VERSION "HNNBNNNYNNNNNNNNNNNNNNNNNNNNNNNNNNNNNNNNNN/4/%%%/4/'%**4NNN///"

NS_ :

BS_:

BU_: BAP_Tester BCM Gateway_Max TSGGen3_BFS TSGGen3_FS TSGGen3_HBFS TSGGen3_HFS WLC_01_CFD

BO_ 332 Motor_54: 32 Gateway_Max
 SG_ Motor_54_CRC : 0|8@1+ (1,0) [0|255] ""  BCM
 SG_ Motor_54_BZ : 8|4@1+ (1,0) [0|15] ""  BCM
 SG_ MO_Anforderung_HMS : 12|3@1+ (1.0,0.0) [0.0|7] ""  BCM
 SG_ FoD_DTC_TSK_GRA : 15|1@1+ (1.0,0.0) [0.0|1] ""  BCM
 SG_ TSK_vMax_aktuell : 16|8@1+ (1,0) [0|253] "Unit_KiloMeterPerHour"  BCM
 SG_ ISA_Status : 24|3@1+ (1.0,0.0) [0.0|7] ""  BCM
 SG_ ISA_Regelung_aktiv : 27|1@1+ (1.0,0.0) [0.0|1] ""  BCM
 SG_ ISA_Tempolimitwarnung : 28|1@1+ (1.0,0.0) [0.0|1] ""  BCM
 SG_ MO_Red_El_Fahrleistung : 29|3@1+ (1.0,0.0) [0.0|7] ""  BCM
 SG_ TSK_Status_EA : 32|3@1+ (1.0,0.0) [0.0|7] ""  BCM
 SG_ FoD_DTC_TSK_ACC : 35|1@1+ (1.0,0.0) [0.0|1] ""  BCM
 SG_ TSK_ACC_FoD_Status : 36|2@1+ (1.0,0.0) [0.0|3] ""  BCM
 SG_ TSK_GRA_FoD_Status : 38|2@1+ (1.0,0.0) [0.0|3] ""  BCM
 SG_ TSK_vMax_Fahrerassistenz : 40|9@1+ (1,0) [0|510] ""  BCM
 SG_ TSK_Einheit_vMax_Fahrerassistenz : 49|1@1+ (1.0,0.0) [0.0|1] ""  BCM
 SG_ TSK_Status_PLA : 50|3@1+ (1.0,0.0) [0.0|7] ""  BCM
 SG_ TSK_aktives_System : 53|3@1+ (1.0,0.0) [0.0|7] ""  BCM
 SG_ TSK_erhoehter_Fahrwiderstand : 56|1@1+ (1.0,0.0) [0.0|1] ""  BCM
 SG_ TSK_Anf_Antriebsmoment : 57|1@1+ (1.0,0.0) [0.0|1] ""  BCM
 SG_ TSK_Status_ARA : 58|3@1+ (1.0,0.0) [0.0|7] ""  BCM
 SG_ TSK_Status_IPA : 61|3@1+ (1.0,0.0) [0.0|7] ""  BCM
 SG_ TSK_aktives_System_02 : 64|4@1+ (1.0,0.0) [0.0|15] ""  BCM
 SG_ TSK_Status_RHP : 68|3@1+ (1.0,0.0) [0.0|7] ""  BCM
 SG_ MO_Kuppl_betaetigt : 72|1@1+ (1.0,0.0) [0.0|1] ""  BCM
 SG_ MO_QBit_Kuppl_betaetigt : 73|1@1+ (1.0,0.0) [0.0|1] ""  BCM
 SG_ MO_Klima_Regelmodus : 74|2@1+ (1.0,0.0) [0.0|3] ""  BCM
 SG_ MO_Fahrbereitschaft : 76|2@1+ (1.0,0.0) [0.0|3] ""  BCM
 SG_ MO_Freilauf_Info : 78|2@1+ (1.0,0.0) [0.0|3] ""  BCM
 SG_ CE_FlgLnchCtlPreCnd : 80|1@1+ (1.0,0.0) [0.0|1] ""  BCM
 SG_ MO_Krit_Heckobjekt : 81|3@1+ (1.0,0.0) [0.0|7] ""  BCM
 SG_ MO_NGS_Gangpos : 84|3@1+ (1.0,0.0) [0.0|7] ""  BCM
 SG_ MO_Freilauf_Status : 87|3@1+ (1.0,0.0) [0.0|7] ""  BCM
 SG_ MO_EBoost_verf_praed : 90|2@1+ (1.0,0.0) [0.0|3] ""  BCM
 SG_ MO_Heckspoiler_Anf : 92|1@1+ (1.0,0.0) [0.0|1] ""  BCM
 SG_ MO_eLaunch_verf : 93|2@1+ (1.0,0.0) [0.0|3] ""  BCM
 SG_ MO_Positionierung_aktiv : 95|1@1+ (1.0,0.0) [0.0|1] ""  BCM
 SG_ MO_Veto_Launchcontrol : 96|1@1+ (1.0,0.0) [0.0|1] ""  BCM
 SG_ MO_Startwunsch : 100|1@1+ (1.0,0.0) [0.0|1] ""  BCM
 SG_ MO_LaunchControl : 101|1@1+ (1.0,0.0) [0.0|1] ""  BCM
 SG_ MO_UBE_Hybrid_Reserve : 102|10@1+ (5,0) [0|5110] "Unit_WattHour"  BCM
 SG_ OBDProtocol_req : 112|8@1+ (1.0,0.0) [0.0|255] ""  BCM
 SG_ OBD_Calc_Load_Val : 128|8@1+ (0.39215686274509803,0) [0E-17|99.99999999999999765] "Unit_PerCent"  BCM
 SG_ OBD_Eng_Cool_Temp : 136|8@1+ (1,-40) [-40|215] "Unit_DegreCelsi"  BCM
 SG_ OBD_Abs_Throttle_Pos : 144|8@1+ (0.39215686274509803,0) [0E-17|99.99999999999999765] "Unit_PerCent"  BCM
 SG_ OBD_Abs_Load_Val : 152|16@1+ (0.39215686274509803,0) [0E-17|25699.99999999999939605] "Unit_PerCent"  BCM
 SG_ OBD_Abs_Pedal_Pos : 168|8@1+ (0.39215686274509803,0) [0E-17|99.99999999999999765] "Unit_PerCent"  BCM
 SG_ MO_Servicemodus : 176|4@1+ (1.0,0.0) [0.0|15] ""  BCM
 SG_ OBD_ClearMem_Inhibit : 183|1@1+ (1.0,0.0) [0.0|1] ""  BCM
 SG_ OBD_Sperrung_Kaltstart_Denom : 184|1@1+ (1.0,0.0) [0.0|1] ""  BCM
 SG_ MO_QBit_Aussen_Temp : 185|1@1+ (1.0,0.0) [0.0|1] ""  BCM
 SG_ OBD_Sperrung_IUMPR : 186|1@1+ (1.0,0.0) [0.0|1] ""  BCM
 SG_ OBD_Kaltstart_Denominator : 187|1@1+ (1.0,0.0) [0.0|1] ""  BCM
 SG_ OBD_Minimum_Trip : 188|1@1+ (1.0,0.0) [0.0|1] ""  BCM
 SG_ OBD_Driving_Cycle : 189|1@1+ (1.0,0.0) [0.0|1] ""  BCM,TSGGen3_BFS,TSGGen3_FS,TSGGen3_HBFS,TSGGen3_HFS,WLC_01_CFD
 SG_ OBD_Warm_Up_Cycle : 190|1@1+ (1.0,0.0) [0.0|1] ""  BCM,TSGGen3_BFS,TSGGen3_FS,TSGGen3_HBFS,TSGGen3_HFS,WLC_01_CFD
 SG_ OBD_Normed_Trip : 191|1@1+ (1.0,0.0) [0.0|1] ""  BCM
 SG_ MO_EMG_Min_Leistung : 192|11@1+ (100,-102200) [-102200|102300] "Unit_Watt"  BCM
 SG_ MO_EMG_Max_Leistung : 203|11@1+ (100,-102200) [-102200|102300] "Unit_Watt"  BCM
 SG_ MO_MVEM_MinLeistung_MVVerbrauch : 214|10@1+ (50,-10500) [-10500|40500] "Unit_Watt"  BCM
 SG_ MO_MVEM_MaxLeistung_MVVerbrauch : 224|10@1+ (50,-10500) [-10500|40500] "Unit_Watt"  BCM
 SG_ MO_UBE_Reserve : 238|10@1+ (5,0) [0|5110] "Unit_WattHour"  BCM
 SG_ OBD_Aussen_Temp_gef : 248|8@1+ (1,-40) [-40|213] "Unit_DegreCelsi"  BCM

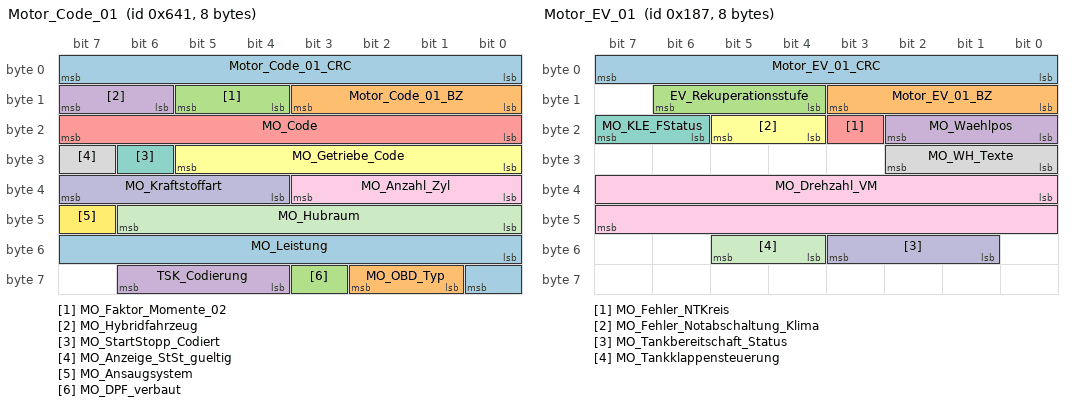
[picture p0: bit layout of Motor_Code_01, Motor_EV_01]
BO_ 1601 Motor_Code_01: 8 Gateway_Max
 SG_ Motor_Code_01_CRC : 0|8@1+ (1,0) [0|255] ""  Vector__XXX
 SG_ Motor_Code_01_BZ : 8|4@1+ (1,0) [0|15] ""  Vector__XXX
 SG_ MO_Faktor_Momente_02 : 12|2@1+ (1,0) [1|3] "Unit_NewtoMeter"  Vector__XXX
 SG_ MO_Hybridfahrzeug : 14|2@1+ (1.0,0.0) [0.0|3] ""  BCM,TSGGen3_BFS,TSGGen3_FS,TSGGen3_HBFS,TSGGen3_HFS
 SG_ MO_Code : 16|8@1+ (1,0) [0|255] ""  Vector__XXX
 SG_ MO_Getriebe_Code : 24|6@1+ (1.0,0.0) [0.0|63] ""  BCM
 SG_ MO_StartStopp_Codiert : 30|1@1+ (1.0,0.0) [0.0|1] ""  Vector__XXX
 SG_ MO_Anzeige_StSt_gueltig : 31|1@1+ (1.0,0.0) [0.0|1] ""  Vector__XXX
 SG_ MO_Anzahl_Zyl : 32|4@1+ (1.0,0.0) [0.0|15] ""  Vector__XXX
 SG_ MO_Kraftstoffart : 36|4@1+ (1.0,0.0) [0.0|15] ""  Vector__XXX
 SG_ MO_Hubraum : 40|7@1+ (0.1,0) [0.0|12.7] "Unit_Liter"  Vector__XXX
 SG_ MO_Ansaugsystem : 47|1@1+ (1.0,0.0) [0.0|1] ""  Vector__XXX
 SG_ MO_Leistung : 48|9@1+ (1,0) [0|511] "Unit_KiloWatt"  Vector__XXX
 SG_ MO_OBD_Typ : 57|2@1+ (1.0,0.0) [0.0|3] ""  Vector__XXX
 SG_ MO_DPF_verbaut : 59|1@1+ (1.0,0.0) [0.0|1] ""  Vector__XXX
 SG_ TSK_Codierung : 60|3@1+ (1.0,0.0) [0.0|7] ""  Vector__XXX

BO_ 391 Motor_EV_01: 8 Gateway_Max
 SG_ Motor_EV_01_CRC : 0|8@1+ (1,0) [0|255] ""  Vector__XXX
 SG_ Motor_EV_01_BZ : 8|4@1+ (1,0) [0|15] ""  Vector__XXX
 SG_ EV_Rekuperationsstufe : 12|3@1+ (1.0,0.0) [0.0|7] ""  Vector__XXX
 SG_ MO_Waehlpos : 16|3@1+ (1.0,0.0) [0.0|7] ""  BCM
 SG_ MO_Fehler_NTKreis : 19|1@1+ (1.0,0.0) [0.0|1] ""  Vector__XXX
 SG_ MO_Fehler_Notabschaltung_Klima : 20|2@1+ (1.0,0.0) [0.0|3] ""  Vector__XXX
 SG_ MO_KLE_FStatus : 22|2@1+ (1.0,0.0) [0.0|3] ""  Vector__XXX
 SG_ MO_WH_Texte : 24|3@1+ (1.0,0.0) [0.0|7] ""  Vector__XXX
 SG_ MO_Drehzahl_VM : 32|16@1+ (0.25,0) [0.00|16383.00] "Unit_MinutInver"  Vector__XXX
 SG_ MO_Tankbereitschaft_Status : 49|3@1+ (1.0,0.0) [0.0|7] ""  Vector__XXX
 SG_ MO_Tankklappensteuerung : 52|2@1+ (1.0,0.0) [0.0|3] ""  BCM

BO_ 16 MSG1_WFS_Anfrage: 8 Gateway_Max
 SG_ WFS_MSG1_RND : 0|32@1+ (1.0,0.0) [0.0|4294967295] ""  BCM
 SG_ WFS_MSG1_CRC : 32|32@1+ (1.0,0.0) [0.0|4294967295] ""  BCM

BO_ 22 MSG3_WFS_Anfrage: 8 Gateway_Max
 SG_ WFS_MSG3_RND : 0|32@1+ (1.0,0.0) [0.0|4294967295] ""  BCM
 SG_ WFS_MSG3_CRC : 32|32@1+ (1.0,0.0) [0.0|4294967295] ""  BCM

BO_ 24 MSG4_WFS_Anfrage: 8 Gateway_Max
 SG_ WFS_MSG4_RND : 0|32@1+ (1.0,0.0) [0.0|4294967295] ""  BCM
 SG_ WFS_MSG4_CRC : 32|32@1+ (1.0,0.0) [0.0|4294967295] ""  BCM

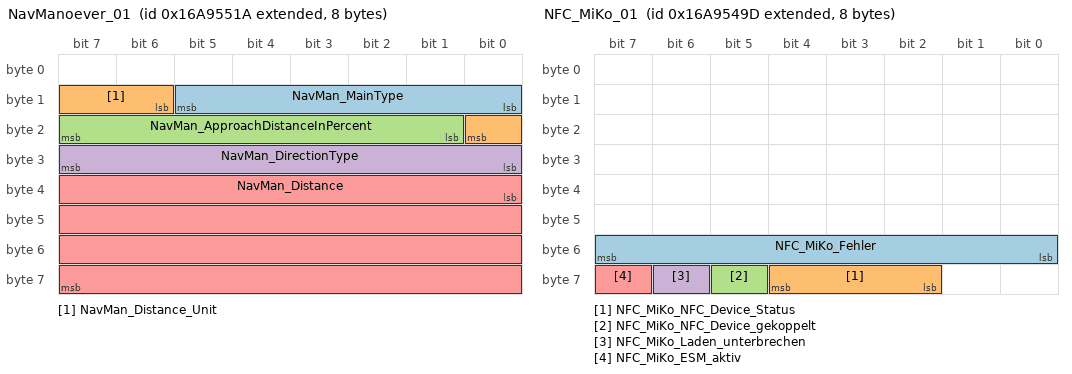
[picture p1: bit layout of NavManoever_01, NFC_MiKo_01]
BO_ 2527679770 NavManoever_01: 8 Gateway_Max
 SG_ NavMan_MainType : 8|6@1+ (1.0,0.0) [0.0|63] ""  BCM
 SG_ NavMan_Distance_Unit : 14|3@1+ (1.0,0.0) [0.0|7] ""  Vector__XXX
 SG_ NavMan_ApproachDistanceInPercent : 17|7@1+ (1,0) [0|100] "Unit_PerCent"  BCM
 SG_ NavMan_DirectionType : 24|8@1+ (1.411764705882353,0) [0E-15|360.000000000000015] "Unit_DegreOfArc"  BCM
 SG_ NavMan_Distance : 32|32@1+ (0.1,0) [0.0|429496729.5] "Unit_None"  Vector__XXX

BO_ 2527679645 NFC_MiKo_01: 8 WLC_01_CFD
 SG_ NFC_MiKo_Fehler : 48|8@1+ (1.0,0.0) [0.0|255] ""  Gateway_Max
 SG_ NFC_MiKo_NFC_Device_Status : 58|3@1+ (1.0,0.0) [0.0|7] ""  BCM,Gateway_Max
 SG_ NFC_MiKo_NFC_Device_gekoppelt : 61|1@1+ (1.0,0.0) [0.0|1] ""  BCM,Gateway_Max
 SG_ NFC_MiKo_Laden_unterbrechen : 62|1@1+ (1.0,0.0) [0.0|1] ""  Gateway_Max
 SG_ NFC_MiKo_ESM_aktiv : 63|1@1+ (1.0,0.0) [0.0|1] ""  Gateway_Max

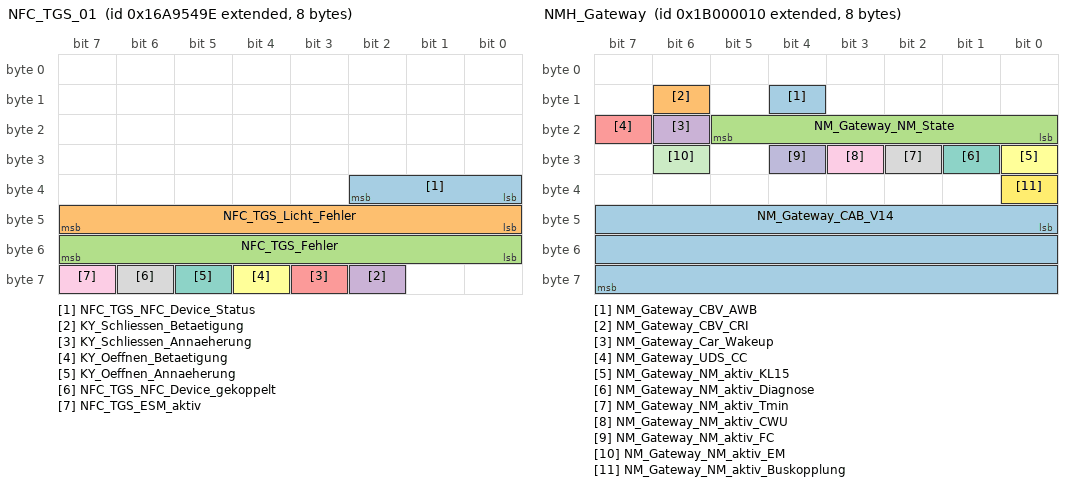
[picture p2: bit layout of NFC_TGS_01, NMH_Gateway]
BO_ 2527679646 NFC_TGS_01: 8 BCM
 SG_ NFC_TGS_NFC_Device_Status : 32|3@1+ (1.0,0.0) [0.0|7] ""  Vector__XXX
 SG_ NFC_TGS_Licht_Fehler : 40|8@1+ (1.0,0.0) [0.0|255] ""  Vector__XXX
 SG_ NFC_TGS_Fehler : 48|8@1+ (1.0,0.0) [0.0|255] ""  Vector__XXX
 SG_ KY_Schliessen_Betaetigung : 58|1@1+ (1.0,0.0) [0.0|1] ""  Vector__XXX
 SG_ KY_Schliessen_Annaeherung : 59|1@1+ (1.0,0.0) [0.0|1] ""  Vector__XXX
 SG_ KY_Oeffnen_Betaetigung : 60|1@1+ (1.0,0.0) [0.0|1] ""  TSGGen3_FS
 SG_ KY_Oeffnen_Annaeherung : 61|1@1+ (1.0,0.0) [0.0|1] ""  TSGGen3_FS
 SG_ NFC_TGS_NFC_Device_gekoppelt : 62|1@1+ (1.0,0.0) [0.0|1] ""  Vector__XXX
 SG_ NFC_TGS_ESM_aktiv : 63|1@1+ (1.0,0.0) [0.0|1] ""  Vector__XXX

BO_ 2600468494 NMH_BCM1: 8 BCM
 SG_ NM_BCM1_CBV_AWB : 12|1@1+ (1.0,0.0) [0.0|1] ""  Gateway_Max
 SG_ NM_BCM1_CBV_CRI : 14|1@1+ (1.0,0.0) [0.0|1] ""  Gateway_Max
 SG_ NM_BCM1_NM_State : 16|6@1+ (1.0,0.0) [0.0|63] ""  TSGGen3_BFS,TSGGen3_FS,TSGGen3_HBFS,TSGGen3_HFS,WLC_01_CFD
 SG_ NM_BCM1_Car_Wakeup : 22|1@1+ (1.0,0.0) [0.0|1] ""  Gateway_Max
 SG_ NM_BCM1_UDS_CC : 23|1@1+ (1.0,0.0) [0.0|1] ""  Vector__XXX
 SG_ NM_BCM1_NM_aktiv_KL15 : 24|1@1+ (1.0,0.0) [0.0|1] ""  Vector__XXX
 SG_ NM_BCM1_NM_aktiv_Diagnose : 25|1@1+ (1.0,0.0) [0.0|1] ""  Vector__XXX
 SG_ NM_BCM1_NM_aktiv_Tmin : 26|1@1+ (1.0,0.0) [0.0|1] ""  Vector__XXX
 SG_ NM_BCM1_NM_aktiv_Aussenlicht : 27|1@1+ (1.0,0.0) [0.0|1] ""  Vector__XXX
 SG_ NM_BCM1_NM_aktiv_ZV : 28|1@1+ (1.0,0.0) [0.0|1] ""  Vector__XXX
 SG_ NM_BCM1_NM_aktiv_Heizung : 29|1@1+ (1.0,0.0) [0.0|1] ""  Vector__XXX
 SG_ NM_BCM1_NM_aktiv_Innenlicht : 30|1@1+ (1.0,0.0) [0.0|1] ""  Vector__XXX
 SG_ NM_BCM1_NM_aktiv_DWA : 31|1@1+ (1.0,0.0) [0.0|1] ""  Vector__XXX
 SG_ NM_BCM1_NM_aktiv_Funk : 32|1@1+ (1.0,0.0) [0.0|1] ""  Vector__XXX
 SG_ NM_BCM1_NM_aktiv_Kessy : 33|1@1+ (1.0,0.0) [0.0|1] ""  Vector__XXX
 SG_ NM_BCM1_NM_aktiv_TK_geschlossen : 34|1@1+ (1.0,0.0) [0.0|1] ""  Vector__XXX
 SG_ NM_BCM1_NM_aktiv_Applikation : 35|1@1+ (1.0,0.0) [0.0|1] ""  Vector__XXX
 SG_ NM_BCM1_NM_aktiv_Remotestart : 36|1@1+ (1.0,0.0) [0.0|1] ""  Vector__XXX
 SG_ NM_BCM1_NM_aktiv_Remot_Door_L_Un : 37|1@1+ (1.0,0.0) [0.0|1] ""  Vector__XXX
 SG_ NM_BCM1_NM_aktiv_VLW : 38|1@1+ (1.0,0.0) [0.0|1] ""  Vector__XXX
 SG_ NM_BCM1_CAB_V14 : 40|24@1+ (1.0,0.0) [0.0|16777215] ""  Gateway_Max

BO_ 2600468496 NMH_Gateway: 8 Gateway_Max
 SG_ NM_Gateway_CBV_AWB : 12|1@1+ (1.0,0.0) [0.0|1] ""  Vector__XXX
 SG_ NM_Gateway_CBV_CRI : 14|1@1+ (1.0,0.0) [0.0|1] ""  Vector__XXX
 SG_ NM_Gateway_NM_State : 16|6@1+ (1.0,0.0) [0.0|63] ""  BCM,TSGGen3_BFS,TSGGen3_FS,TSGGen3_HBFS,TSGGen3_HFS,WLC_01_CFD
 SG_ NM_Gateway_Car_Wakeup : 22|1@1+ (1.0,0.0) [0.0|1] ""  Vector__XXX
 SG_ NM_Gateway_UDS_CC : 23|1@1+ (1.0,0.0) [0.0|1] ""  Vector__XXX
 SG_ NM_Gateway_NM_aktiv_KL15 : 24|1@1+ (1.0,0.0) [0.0|1] ""  Vector__XXX
 SG_ NM_Gateway_NM_aktiv_Diagnose : 25|1@1+ (1.0,0.0) [0.0|1] ""  Vector__XXX
 SG_ NM_Gateway_NM_aktiv_Tmin : 26|1@1+ (1.0,0.0) [0.0|1] ""  Vector__XXX
 SG_ NM_Gateway_NM_aktiv_CWU : 27|1@1+ (1.0,0.0) [0.0|1] ""  Vector__XXX
 SG_ NM_Gateway_NM_aktiv_FC : 28|1@1+ (1.0,0.0) [0.0|1] ""  Vector__XXX
 SG_ NM_Gateway_NM_aktiv_EM : 30|1@1+ (1.0,0.0) [0.0|1] ""  Vector__XXX
 SG_ NM_Gateway_NM_aktiv_Buskopplung : 32|1@1+ (1.0,0.0) [0.0|1] ""  Vector__XXX
 SG_ NM_Gateway_CAB_V14 : 40|24@1+ (1.0,0.0) [0.0|16777215] ""  Vector__XXX

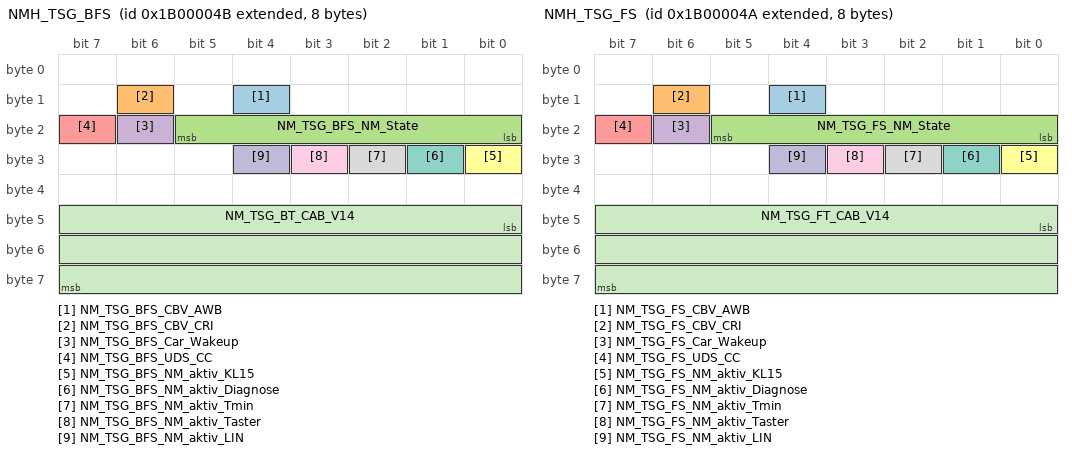
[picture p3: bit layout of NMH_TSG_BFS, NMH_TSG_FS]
BO_ 2600468555 NMH_TSG_BFS: 8 TSGGen3_BFS
 SG_ NM_TSG_BFS_CBV_AWB : 12|1@1+ (1.0,0.0) [0.0|1] ""  Gateway_Max
 SG_ NM_TSG_BFS_CBV_CRI : 14|1@1+ (1.0,0.0) [0.0|1] ""  Gateway_Max
 SG_ NM_TSG_BFS_NM_State : 16|6@1+ (1.0,0.0) [0.0|63] ""  BCM,TSGGen3_FS,TSGGen3_HBFS,TSGGen3_HFS,WLC_01_CFD
 SG_ NM_TSG_BFS_Car_Wakeup : 22|1@1+ (1.0,0.0) [0.0|1] ""  Gateway_Max
 SG_ NM_TSG_BFS_UDS_CC : 23|1@1+ (1.0,0.0) [0.0|1] ""  Vector__XXX
 SG_ NM_TSG_BFS_NM_aktiv_KL15 : 24|1@1+ (1.0,0.0) [0.0|1] ""  Vector__XXX
 SG_ NM_TSG_BFS_NM_aktiv_Diagnose : 25|1@1+ (1.0,0.0) [0.0|1] ""  Vector__XXX
 SG_ NM_TSG_BFS_NM_aktiv_Tmin : 26|1@1+ (1.0,0.0) [0.0|1] ""  Vector__XXX
 SG_ NM_TSG_BFS_NM_aktiv_Taster : 27|1@1+ (1.0,0.0) [0.0|1] ""  Vector__XXX
 SG_ NM_TSG_BFS_NM_aktiv_LIN : 28|1@1+ (1.0,0.0) [0.0|1] ""  Vector__XXX
 SG_ NM_TSG_BT_CAB_V14 : 40|24@1+ (1.0,0.0) [0.0|16777215] ""  Gateway_Max

BO_ 2600468554 NMH_TSG_FS: 8 TSGGen3_FS
 SG_ NM_TSG_FS_CBV_AWB : 12|1@1+ (1.0,0.0) [0.0|1] ""  Gateway_Max
 SG_ NM_TSG_FS_CBV_CRI : 14|1@1+ (1.0,0.0) [0.0|1] ""  Gateway_Max
 SG_ NM_TSG_FS_NM_State : 16|6@1+ (1.0,0.0) [0.0|63] ""  BCM,TSGGen3_BFS,TSGGen3_HBFS,TSGGen3_HFS,WLC_01_CFD
 SG_ NM_TSG_FS_Car_Wakeup : 22|1@1+ (1.0,0.0) [0.0|1] ""  Gateway_Max
 SG_ NM_TSG_FS_UDS_CC : 23|1@1+ (1.0,0.0) [0.0|1] ""  Vector__XXX
 SG_ NM_TSG_FS_NM_aktiv_KL15 : 24|1@1+ (1.0,0.0) [0.0|1] ""  Vector__XXX
 SG_ NM_TSG_FS_NM_aktiv_Diagnose : 25|1@1+ (1.0,0.0) [0.0|1] ""  Vector__XXX
 SG_ NM_TSG_FS_NM_aktiv_Tmin : 26|1@1+ (1.0,0.0) [0.0|1] ""  Vector__XXX
 SG_ NM_TSG_FS_NM_aktiv_Taster : 27|1@1+ (1.0,0.0) [0.0|1] ""  Vector__XXX
 SG_ NM_TSG_FS_NM_aktiv_LIN : 28|1@1+ (1.0,0.0) [0.0|1] ""  Vector__XXX
 SG_ NM_TSG_FT_CAB_V14 : 40|24@1+ (1.0,0.0) [0.0|16777215] ""  Gateway_Max

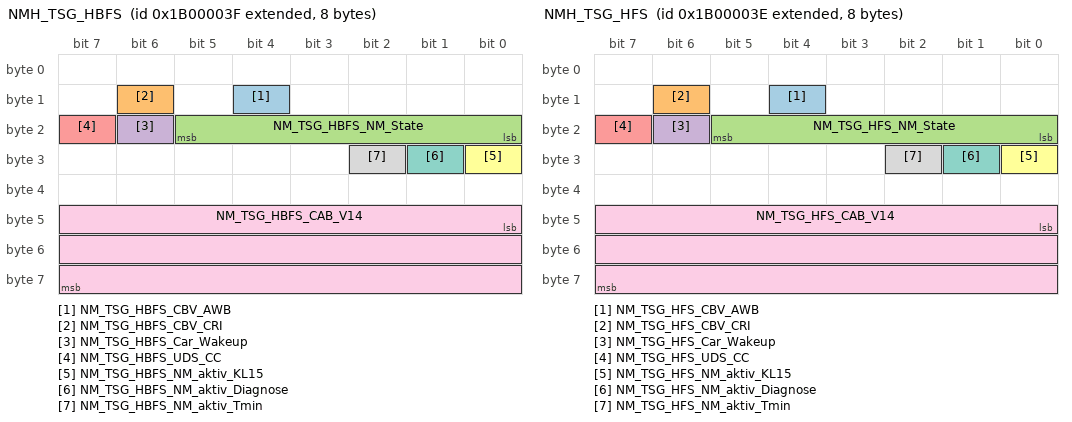
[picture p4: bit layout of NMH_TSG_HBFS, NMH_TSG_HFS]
BO_ 2600468543 NMH_TSG_HBFS: 8 TSGGen3_HBFS
 SG_ NM_TSG_HBFS_CBV_AWB : 12|1@1+ (1.0,0.0) [0.0|1] ""  Vector__XXX
 SG_ NM_TSG_HBFS_CBV_CRI : 14|1@1+ (1.0,0.0) [0.0|1] ""  Gateway_Max
 SG_ NM_TSG_HBFS_NM_State : 16|6@1+ (1.0,0.0) [0.0|63] ""  BCM,TSGGen3_BFS,TSGGen3_FS,TSGGen3_HFS,WLC_01_CFD
 SG_ NM_TSG_HBFS_Car_Wakeup : 22|1@1+ (1.0,0.0) [0.0|1] ""  Gateway_Max
 SG_ NM_TSG_HBFS_UDS_CC : 23|1@1+ (1.0,0.0) [0.0|1] ""  Vector__XXX
 SG_ NM_TSG_HBFS_NM_aktiv_KL15 : 24|1@1+ (1.0,0.0) [0.0|1] ""  Vector__XXX
 SG_ NM_TSG_HBFS_NM_aktiv_Diagnose : 25|1@1+ (1.0,0.0) [0.0|1] ""  Vector__XXX
 SG_ NM_TSG_HBFS_NM_aktiv_Tmin : 26|1@1+ (1.0,0.0) [0.0|1] ""  Vector__XXX
 SG_ NM_TSG_HBFS_CAB_V14 : 40|24@1+ (1.0,0.0) [0.0|16777215] ""  Gateway_Max

BO_ 2600468542 NMH_TSG_HFS: 8 TSGGen3_HFS
 SG_ NM_TSG_HFS_CBV_AWB : 12|1@1+ (1.0,0.0) [0.0|1] ""  Vector__XXX
 SG_ NM_TSG_HFS_CBV_CRI : 14|1@1+ (1.0,0.0) [0.0|1] ""  Vector__XXX
 SG_ NM_TSG_HFS_NM_State : 16|6@1+ (1.0,0.0) [0.0|63] ""  BCM,TSGGen3_BFS,TSGGen3_FS,TSGGen3_HBFS,WLC_01_CFD
 SG_ NM_TSG_HFS_Car_Wakeup : 22|1@1+ (1.0,0.0) [0.0|1] ""  Gateway_Max
 SG_ NM_TSG_HFS_UDS_CC : 23|1@1+ (1.0,0.0) [0.0|1] ""  Vector__XXX
 SG_ NM_TSG_HFS_NM_aktiv_KL15 : 24|1@1+ (1.0,0.0) [0.0|1] ""  Vector__XXX
 SG_ NM_TSG_HFS_NM_aktiv_Diagnose : 25|1@1+ (1.0,0.0) [0.0|1] ""  Vector__XXX
 SG_ NM_TSG_HFS_NM_aktiv_Tmin : 26|1@1+ (1.0,0.0) [0.0|1] ""  Vector__XXX
 SG_ NM_TSG_HFS_CAB_V14 : 40|24@1+ (1.0,0.0) [0.0|16777215] ""  Gateway_Max

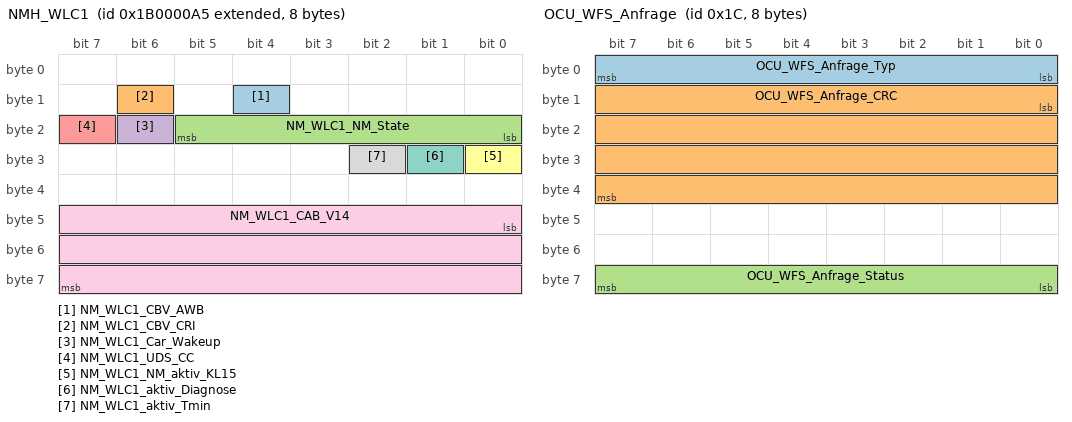
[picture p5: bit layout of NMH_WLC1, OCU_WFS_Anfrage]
BO_ 2600468645 NMH_WLC1: 8 WLC_01_CFD
 SG_ NM_WLC1_CBV_AWB : 12|1@1+ (1.0,0.0) [0.0|1] ""  Gateway_Max
 SG_ NM_WLC1_CBV_CRI : 14|1@1+ (1.0,0.0) [0.0|1] ""  Gateway_Max
 SG_ NM_WLC1_NM_State : 16|6@1+ (1.0,0.0) [0.0|63] ""  BCM,TSGGen3_BFS,TSGGen3_FS,TSGGen3_HBFS,TSGGen3_HFS
 SG_ NM_WLC1_Car_Wakeup : 22|1@1+ (1.0,0.0) [0.0|1] ""  Gateway_Max
 SG_ NM_WLC1_UDS_CC : 23|1@1+ (1.0,0.0) [0.0|1] ""  Vector__XXX
 SG_ NM_WLC1_NM_aktiv_KL15 : 24|1@1+ (1.0,0.0) [0.0|1] ""  Vector__XXX
 SG_ NM_WLC1_aktiv_Diagnose : 25|1@1+ (1.0,0.0) [0.0|1] ""  Vector__XXX
 SG_ NM_WLC1_aktiv_Tmin : 26|1@1+ (1.0,0.0) [0.0|1] ""  Vector__XXX
 SG_ NM_WLC1_CAB_V14 : 40|24@1+ (1.0,0.0) [0.0|16777215] ""  Gateway_Max

BO_ 2621440526 OBDC_BCM1_Req_FD: 64 Gateway_Max
 SG_ OBDC_BCM1_Req_FD_Data : 0|512@1+ (1.0,0.0) [0.0|13407807929942597099574024998205846127479365820592393377723561443721764030073546976801874298166903427690031858186486050853753882811946569946433649006084095] ""  BCM

BO_ 2621571598 OBDC_BCM1_Resp_FD: 64 BCM
 SG_ OBDC_BCM1_Resp_FD_Data : 0|512@1+ (1.0,0.0) [0.0|13407807929942597099574024998205846127479365820592393377723561443721764030073546976801874298166903427690031858186486050853753882811946569946433649006084095] ""  Gateway_Max

BO_ 2549875386 OBDC_DDA_Req: 8 Gateway_Max
 SG_ OBDC_DDA_Req_Data : 0|64@1+ (1.0,0.0) [0.0|18446744073709551615] ""  BCM

BO_ 2550006458 OBDC_DDA_Resp: 8 BCM
 SG_ OBDC_DDA_Resp_Data : 0|64@1+ (1.0,0.0) [0.0|18446744073709551615] ""  Gateway_Max

BO_ 2549940736 OBDC_Funktionaler_Req_All: 8 Gateway_Max
 SG_ OBDC_Funktionaler_Req_All_Data : 0|64@1+ (1.0,0.0) [0.0|18446744073709551615] ""  BCM

BO_ 2621506048 OBDC_Funktionaler_Req_All_FD: 64 Gateway_Max
 SG_ OBDC_Funktion_Req_All_FD_Data : 0|512@1+ (1.0,0.0) [0.0|13407807929942597099574024998205846127479365820592393377723561443721764030073546976801874298166903427690031858186486050853753882811946569946433649006084095] ""  BCM,TSGGen3_BFS,TSGGen3_FS,TSGGen3_HBFS,TSGGen3_HFS,WLC_01_CFD

BO_ 2549875250 OBDC_Kessy_Req: 8 Gateway_Max
 SG_ OBDC_Kessy_Req_Data : 0|64@1+ (1.0,0.0) [0.0|18446744073709551615] ""  BCM

BO_ 2550006322 OBDC_Kessy_Resp: 8 BCM
 SG_ OBDC_Kessy_Resp_Data : 0|64@1+ (1.0,0.0) [0.0|18446744073709551615] ""  Gateway_Max

BO_ 2549875350 OBDC_LED_LM_L_Req: 8 Gateway_Max
 SG_ OBDC_LED_LM_L_Req_Data : 0|64@1+ (1.0,0.0) [0.0|18446744073709551615] ""  BCM

BO_ 2550006422 OBDC_LED_LM_L_Resp: 8 BCM
 SG_ OBDC_LED_LM_L_Resp_Data : 0|64@1+ (1.0,0.0) [0.0|18446744073709551615] ""  Gateway_Max

BO_ 2549875351 OBDC_LED_LM_R_Req: 8 Gateway_Max
 SG_ OBDC_LED_LM_R_Req_Data : 0|64@1+ (1.0,0.0) [0.0|18446744073709551615] ""  BCM

BO_ 2550006423 OBDC_LED_LM_R_Resp: 8 BCM
 SG_ OBDC_LED_LM_R_Resp_Data : 0|64@1+ (1.0,0.0) [0.0|18446744073709551615] ""  Gateway_Max

BO_ 2550399491 OBDC_RSAD_HL_Req: 8 Gateway_Max
 SG_ OBDC_RSAD_HL_Req_Data : 0|64@1+ (1,0) [0|18446744073709551615] "Unit_None"  BCM

BO_ 2621702659 OBDC_RSAD_HL_Req_FD: 64 Gateway_Max
 SG_ OBDC_RSAD_HL_Req_FD_Data : 0|512@1+ (1.0,0.0) [0.0|13407807929942597099574024998205846127479365820592393377723561443721764030073546976801874298166903427690031858186486050853753882811946569946433649006084095] ""  BCM

BO_ 2550530563 OBDC_RSAD_HL_Resp: 8 BCM
 SG_ OBDC_RSAD_HL_Resp_Data : 0|64@1+ (1,0) [0|18446744073709551615] "Unit_None"  Gateway_Max

BO_ 2621833731 OBDC_RSAD_HL_Resp_FD: 64 BCM
 SG_ OBDC_RSAD_HL_Resp_FD_Data : 0|512@1+ (1.0,0.0) [0.0|13407807929942597099574024998205846127479365820592393377723561443721764030073546976801874298166903427690031858186486050853753882811946569946433649006084095] ""  Gateway_Max

BO_ 2550399492 OBDC_RSAD_HR_Req: 8 Gateway_Max
 SG_ OBDC_RSAD_HR_Req_Data : 0|64@1+ (1,0) [0|18446744073709551615] "Unit_None"  BCM

BO_ 2621702660 OBDC_RSAD_HR_Req_FD: 64 Gateway_Max
 SG_ OBDC_RSAD_HR_Req_FD_Data : 0|512@1+ (1.0,0.0) [0.0|13407807929942597099574024998205846127479365820592393377723561443721764030073546976801874298166903427690031858186486050853753882811946569946433649006084095] ""  BCM

BO_ 2550530564 OBDC_RSAD_HR_Resp: 8 BCM
 SG_ OBDC_RSAD_HR_Resp_Data : 0|64@1+ (1,0) [0|18446744073709551615] "Unit_None"  Gateway_Max

BO_ 2621833732 OBDC_RSAD_HR_Resp_FD: 64 BCM
 SG_ OBDC_RSAD_HR_Resp_FD_Data : 0|512@1+ (1.0,0.0) [0.0|13407807929942597099574024998205846127479365820592393377723561443721764030073546976801874298166903427690031858186486050853753882811946569946433649006084095] ""  Gateway_Max

BO_ 2621702709 OBDC_RSAD_IN2_Req_FD: 64 Gateway_Max
 SG_ OBDC_RSAD_IN2_Req_FD_Data : 0|512@1+ (1.0,0.0) [0.0|13407807929942597099574024998205846127479365820592393377723561443721764030073546976801874298166903427690031858186486050853753882811946569946433649006084095] ""  BCM

BO_ 2621833781 OBDC_RSAD_IN2_Resp_FD: 64 BCM
 SG_ OBDC_RSAD_IN2_Resp_FD_Data : 0|512@1+ (1.0,0.0) [0.0|13407807929942597099574024998205846127479365820592393377723561443721764030073546976801874298166903427690031858186486050853753882811946569946433649006084095] ""  Gateway_Max

BO_ 2621702710 OBDC_RSAD_IN3_Req_FD: 64 Gateway_Max
 SG_ OBDC_RSAD_IN3_Req_FD_Data : 0|512@1+ (1.0,0.0) [0.0|13407807929942597099574024998205846127479365820592393377723561443721764030073546976801874298166903427690031858186486050853753882811946569946433649006084095] ""  BCM

BO_ 2621833782 OBDC_RSAD_IN3_Resp_FD: 64 BCM
 SG_ OBDC_RSAD_IN3_Resp_FD_Data : 0|512@1+ (1.0,0.0) [0.0|13407807929942597099574024998205846127479365820592393377723561443721764030073546976801874298166903427690031858186486050853753882811946569946433649006084095] ""  Gateway_Max

BO_ 2621702711 OBDC_RSAD_IN4_Req_FD: 64 Gateway_Max
 SG_ OBDC_RSAD_IN4_Req_FD_Data : 0|512@1+ (1.0,0.0) [0.0|13407807929942597099574024998205846127479365820592393377723561443721764030073546976801874298166903427690031858186486050853753882811946569946433649006084095] ""  BCM

BO_ 2621833783 OBDC_RSAD_IN4_Resp_FD: 64 BCM
 SG_ OBDC_RSAD_IN4_Resp_FD_Data : 0|512@1+ (1.0,0.0) [0.0|13407807929942597099574024998205846127479365820592393377723561443721764030073546976801874298166903427690031858186486050853753882811946569946433649006084095] ""  Gateway_Max

BO_ 2550399493 OBDC_RSAD_IN_Req: 8 Gateway_Max
 SG_ OBDC_RSAD_IN_Req_Data : 0|64@1+ (1,0) [0|18446744073709551615] "Unit_None"  BCM

BO_ 2621702661 OBDC_RSAD_IN_Req_FD: 64 Gateway_Max
 SG_ OBDC_RSAD_IN_Req_FD_Data : 0|512@1+ (1.0,0.0) [0.0|13407807929942597099574024998205846127479365820592393377723561443721764030073546976801874298166903427690031858186486050853753882811946569946433649006084095] ""  BCM

BO_ 2550530565 OBDC_RSAD_IN_Resp: 8 BCM
 SG_ OBDC_RSAD_IN_Resp_Data : 0|64@1+ (1,0) [0|18446744073709551615] "Unit_None"  Gateway_Max

BO_ 2621833733 OBDC_RSAD_IN_Resp_FD: 64 BCM
 SG_ OBDC_RSAD_IN_Resp_FD_Data : 0|512@1+ (1.0,0.0) [0.0|13407807929942597099574024998205846127479365820592393377723561443721764030073546976801874298166903427690031858186486050853753882811946569946433649006084095] ""  Gateway_Max

BO_ 2550399489 OBDC_RSAD_VL_Req: 8 Gateway_Max
 SG_ OBDC_RSAD_VL_Req_Data : 0|64@1+ (1,0) [0|18446744073709551615] "Unit_None"  BCM

BO_ 2621702657 OBDC_RSAD_VL_Req_FD: 64 Gateway_Max
 SG_ OBDC_RSAD_VL_Req_FD_Data : 0|512@1+ (1.0,0.0) [0.0|13407807929942597099574024998205846127479365820592393377723561443721764030073546976801874298166903427690031858186486050853753882811946569946433649006084095] ""  BCM

BO_ 2550530561 OBDC_RSAD_VL_Resp: 8 BCM
 SG_ OBDC_RSAD_VL_Resp_Data : 0|64@1+ (1,0) [0|18446744073709551615] "Unit_None"  Gateway_Max

BO_ 2621833729 OBDC_RSAD_VL_Resp_FD: 64 BCM
 SG_ OBDC_RSAD_VL_Resp_FD_Data : 0|512@1+ (1.0,0.0) [0.0|13407807929942597099574024998205846127479365820592393377723561443721764030073546976801874298166903427690031858186486050853753882811946569946433649006084095] ""  Gateway_Max

BO_ 2550399490 OBDC_RSAD_VR_Req: 8 Gateway_Max
 SG_ OBDC_RSAD_VR_Req_Data : 0|64@1+ (1,0) [0|18446744073709551615] "Unit_None"  BCM

BO_ 2621702658 OBDC_RSAD_VR_Req_FD: 64 Gateway_Max
 SG_ OBDC_RSAD_VR_Req_FD_Data : 0|512@1+ (1.0,0.0) [0.0|13407807929942597099574024998205846127479365820592393377723561443721764030073546976801874298166903427690031858186486050853753882811946569946433649006084095] ""  BCM

BO_ 2550530562 OBDC_RSAD_VR_Resp: 8 BCM
 SG_ OBDC_RSAD_VR_Resp_Data : 0|64@1+ (1,0) [0|18446744073709551615] "Unit_None"  Gateway_Max

BO_ 2621833730 OBDC_RSAD_VR_Resp_FD: 64 BCM
 SG_ OBDC_RSAD_VR_Resp_FD_Data : 0|512@1+ (1.0,0.0) [0.0|13407807929942597099574024998205846127479365820592393377723561443721764030073546976801874298166903427690031858186486050853753882811946569946433649006084095] ""  Gateway_Max

BO_ 2549903595 OBDC_SSN_NFC_TGS_Req: 8 Gateway_Max
 SG_ OBDC_SSN_NFC_TGS_Req_Data : 0|64@1+ (1.0,0.0) [0.0|18446744073709551615] ""  BCM

BO_ 2550034667 OBDC_SSN_NFC_TGS_Resp: 8 BCM
 SG_ OBDC_SSN_NFC_TGS_Resp_Data : 0|64@1+ (1.0,0.0) [0.0|18446744073709551615] ""  Gateway_Max

BO_ 2621440587 OBDC_TSG_BT_Req_FD: 64 Gateway_Max
 SG_ OBDC_TSG_BT_Req_FD_Data : 0|512@1+ (1.0,0.0) [0.0|13407807929942597099574024998205846127479365820592393377723561443721764030073546976801874298166903427690031858186486050853753882811946569946433649006084095] ""  TSGGen3_BFS

BO_ 2621571659 OBDC_TSG_BT_Resp_FD: 64 TSGGen3_BFS
 SG_ OBDC_TSG_BT_Resp_FD_Data : 0|512@1+ (1.0,0.0) [0.0|13407807929942597099574024998205846127479365820592393377723561443721764030073546976801874298166903427690031858186486050853753882811946569946433649006084095] ""  Gateway_Max

BO_ 2621440586 OBDC_TSG_FT_Req_FD: 64 Gateway_Max
 SG_ OBDC_TSG_FT_Req_FD_Data : 0|512@1+ (1.0,0.0) [0.0|13407807929942597099574024998205846127479365820592393377723561443721764030073546976801874298166903427690031858186486050853753882811946569946433649006084095] ""  TSGGen3_FS

BO_ 2621571658 OBDC_TSG_FT_Resp_FD: 64 TSGGen3_FS
 SG_ OBDC_TSG_FT_Resp_FD_Data : 0|512@1+ (1.0,0.0) [0.0|13407807929942597099574024998205846127479365820592393377723561443721764030073546976801874298166903427690031858186486050853753882811946569946433649006084095] ""  Gateway_Max

BO_ 2621440575 OBDC_TSG_HBFS_Req_FD: 64 Gateway_Max
 SG_ OBDC_TSG_HBFS_Req_FD_Data : 0|512@1+ (1.0,0.0) [0.0|13407807929942597099574024998205846127479365820592393377723561443721764030073546976801874298166903427690031858186486050853753882811946569946433649006084095] ""  TSGGen3_HBFS

BO_ 2621571647 OBDC_TSG_HBFS_Resp_FD: 64 TSGGen3_HBFS
 SG_ OBDC_TSG_HBFS_Resp_FD_Data : 0|512@1+ (1.0,0.0) [0.0|13407807929942597099574024998205846127479365820592393377723561443721764030073546976801874298166903427690031858186486050853753882811946569946433649006084095] ""  Gateway_Max

BO_ 2621440574 OBDC_TSG_HFS_Req_FD: 64 Gateway_Max
 SG_ OBDC_TSG_HFS_Req_FD_Data : 0|512@1+ (1.0,0.0) [0.0|13407807929942597099574024998205846127479365820592393377723561443721764030073546976801874298166903427690031858186486050853753882811946569946433649006084095] ""  TSGGen3_HFS

BO_ 2621571646 OBDC_TSG_HFS_Resp_FD: 64 TSGGen3_HFS
 SG_ OBDC_TSG_HFS_Resp_FD_Data : 0|512@1+ (1.0,0.0) [0.0|13407807929942597099574024998205846127479365820592393377723561443721764030073546976801874298166903427690031858186486050853753882811946569946433649006084095] ""  Gateway_Max

BO_ 2621440677 OBDC_WLC1_Req_FD: 64 Gateway_Max
 SG_ OBDC_WLC1_Req_FD_Data : 0|512@1+ (1.0,0.0) [0.0|13407807929942597099574024998205846127479365820592393377723561443721764030073546976801874298166903427690031858186486050853753882811946569946433649006084095] ""  WLC_01_CFD

BO_ 2621571749 OBDC_WLC1_Resp_FD: 64 WLC_01_CFD
 SG_ OBDC_WLC1_Resp_FD_Data : 0|512@1+ (1.0,0.0) [0.0|13407807929942597099574024998205846127479365820592393377723561443721764030073546976801874298166903427690031858186486050853753882811946569946433649006084095] ""  Gateway_Max

BO_ 2564502513 OBDx_allOBD_Req: 8 Gateway_Max
 SG_ OBDx_allOBD_Req_Data : 0|64@1+ (1.0,0.0) [0.0|18446744073709551615] ""  Vector__XXX

BO_ 28 OCU_WFS_Anfrage: 8 Gateway_Max
 SG_ OCU_WFS_Anfrage_Typ : 0|8@1+ (1.0,0.0) [0.0|255] ""  BCM
 SG_ OCU_WFS_Anfrage_CRC : 8|32@1+ (1.0,0.0) [0.0|4294967295] ""  BCM
 SG_ OCU_WFS_Anfrage_Status : 56|8@1+ (1.0,0.0) [0.0|255] ""  BCM

BO_ 2589283656 ORU_01: 8 Gateway_Max
 SG_ ORU_Warnung : 58|2@1+ (1.0,0.0) [0.0|3] ""  BCM
 SG_ ORU_Status : 61|3@1+ (1.0,0.0) [0.0|7] ""  BCM,TSGGen3_BFS,TSGGen3_FS,TSGGen3_HBFS,TSGGen3_HFS

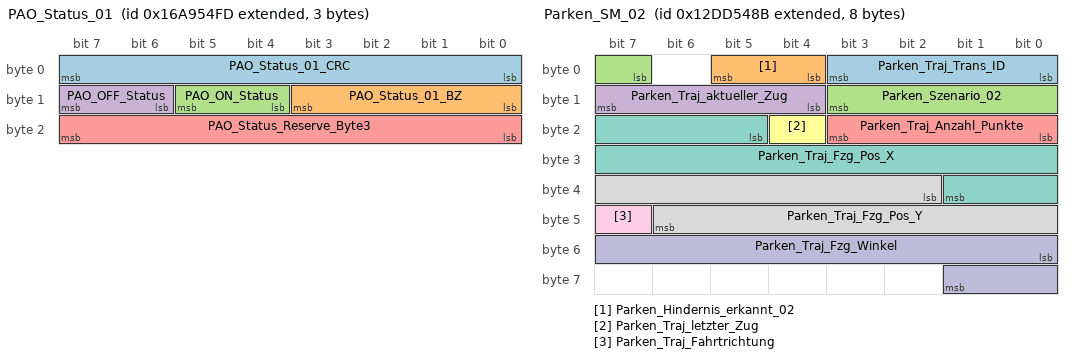
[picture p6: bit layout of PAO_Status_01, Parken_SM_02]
BO_ 2527679741 PAO_Status_01: 3 BCM
 SG_ PAO_Status_01_CRC : 0|8@1+ (1,0) [0|255] ""  Gateway_Max
 SG_ PAO_Status_01_BZ : 8|4@1+ (1,0) [0|15] ""  Gateway_Max
 SG_ PAO_ON_Status : 12|2@1+ (1.0,0.0) [0.0|3] ""  Gateway_Max
 SG_ PAO_OFF_Status : 14|2@1+ (1.0,0.0) [0.0|3] ""  Gateway_Max
 SG_ PAO_Status_Reserve_Byte3 : 16|8@1+ (1.0,0.0) [0.0|255] ""  Gateway_Max

BO_ 233 Parken_SM_01: 8 Gateway_Max
 SG_ Parken_Hindernis_Bereich : 0|4@1+ (1.0,0.0) [0.0|15] ""  BCM
 SG_ Parken_SM_Sensor : 5|1@1+ (1.0,0.0) [0.0|1] ""  BCM
 SG_ Parken_SM_Stillstand : 6|1@1+ (1.0,0.0) [0.0|1] ""  BCM
 SG_ Parken_SM_Schluessel : 7|1@1+ (1.0,0.0) [0.0|1] ""  BCM
 SG_ Parken_SM_Tueren : 8|1@1+ (1.0,0.0) [0.0|1] ""  BCM
 SG_ Parken_SM_Anhaenger : 9|1@1+ (1.0,0.0) [0.0|1] ""  BCM
 SG_ Parken_SM_Fahrbereitschaft : 10|1@1+ (1.0,0.0) [0.0|1] ""  BCM
 SG_ Parken_SM_Fahrstufe : 11|1@1+ (1.0,0.0) [0.0|1] ""  BCM
 SG_ Parken_Anhaltegrund_ext : 12|6@1+ (1.0,0.0) [0.0|63] ""  BCM
 SG_ Parken_Touchdiagnose_Anf : 18|1@1+ (1.0,0.0) [0.0|1] ""  BCM
 SG_ Parken_BT_Wunsch : 19|1@1+ (1.0,0.0) [0.0|1] ""  BCM
 SG_ Parken_Hindernis_erkannt : 20|1@1+ (1.0,0.0) [0.0|1] ""  BCM
 SG_ Parken_Fortschrittszaehler : 21|7@1+ (1,0) [0|100] "Unit_PerCent"  BCM
 SG_ Parken_SM_AktivesRemoteSystem : 28|2@1+ (1.0,0.0) [0.0|3] ""  BCM
 SG_ Parken_Fahrtaster_Empfehlung : 32|2@1+ (1.0,0.0) [0.0|3] ""  BCM
 SG_ Parken_Aktives_Bedienelement : 34|2@1+ (1.0,0.0) [0.0|3] ""  BCM
 SG_ Parken_FFB_Status : 36|3@1+ (1.0,0.0) [0.0|7] ""  BCM
 SG_ Parken_Reversieren_moeglich : 39|1@1+ (1.0,0.0) [0.0|1] ""  BCM
 SG_ Parken_Seite : 40|3@1+ (1.0,0.0) [0.0|7] ""  BCM
 SG_ Parken_Seite_Aktiv : 43|2@1+ (1.0,0.0) [0.0|3] ""  BCM
 SG_ Parken_Szenario_Aktiv : 45|3@1+ (1.0,0.0) [0.0|7] ""  BCM
 SG_ Parken_Manoever_Aktiv : 48|2@1+ (1.0,0.0) [0.0|3] ""  BCM
 SG_ Parken_Manoever : 50|2@1+ (1.0,0.0) [0.0|3] ""  BCM
 SG_ Parken_Szenario : 52|4@1+ (1.0,0.0) [0.0|15] ""  BCM
 SG_ Parken_Funktionsstatus : 56|4@1+ (1.0,0.0) [0.0|15] ""  BCM
 SG_ Parken_Richtung : 60|2@1+ (1.0,0.0) [0.0|3] ""  BCM
 SG_ Parken_Richtung_Aktiv : 62|2@1+ (1.0,0.0) [0.0|3] ""  BCM

BO_ 2463978635 Parken_SM_02: 8 Gateway_Max
 SG_ Parken_Traj_Trans_ID : 0|4@1+ (1.0,0.0) [0.0|15] ""  BCM
 SG_ Parken_Hindernis_erkannt_02 : 4|2@1+ (1.0,0.0) [0.0|3] ""  BCM
 SG_ Parken_Szenario_02 : 7|5@1+ (1.0,0.0) [0.0|31] ""  BCM
 SG_ Parken_Traj_aktueller_Zug : 12|4@1+ (1.0,0.0) [0.0|15] ""  BCM
 SG_ Parken_Traj_Anzahl_Punkte : 16|4@1+ (1.0,0.0) [0.0|15] ""  BCM
 SG_ Parken_Traj_letzter_Zug : 20|1@1+ (1.0,0.0) [0.0|1] ""  BCM
 SG_ Parken_Traj_Fzg_Pos_X : 21|13@1+ (0.5,-2047.5) [-2047.5|2048.0] "Unit_Centimeter"  BCM
 SG_ Parken_Traj_Fzg_Pos_Y : 34|13@1+ (0.5,-2047.5) [-2047.5|2048.0] "Unit_Centimeter"  BCM
 SG_ Parken_Traj_Fahrtrichtung : 47|1@1+ (1.0,0.0) [0.0|1] ""  BCM
 SG_ Parken_Traj_Fzg_Winkel : 48|10@1+ (0.3515625,0) [0E-7|359.6484375] "Unit_DegreOfArc"  BCM

BO_ 850 Parken_SM_03: 8 Gateway_Max
 SG_ Parken_SM_03_MUX M  : 0|3@1+ (1.0,0.0) [0.0|7] ""  BCM
 SG_ Parken_SM_03_Traj_Trans_ID_00 m0  : 3|4@1+ (1.0,0.0) [0.0|15] ""  BCM
 SG_ Parken_SM_03_Traj_Trans_ID_01 m1  : 3|4@1+ (1.0,0.0) [0.0|15] ""  BCM
 SG_ Parken_SM_03_Traj_Trans_ID_02 m2  : 3|4@1+ (1.0,0.0) [0.0|15] ""  BCM
 SG_ Parken_SM_03_Traj_Trans_ID_03 m3  : 3|4@1+ (1.0,0.0) [0.0|15] ""  BCM
 SG_ Parken_SM_03_Traj_Trans_ID_04 m4  : 3|4@1+ (1.0,0.0) [0.0|15] ""  BCM
 SG_ Parken_SM_03_Traj_Trans_ID_05 m5  : 3|4@1+ (1.0,0.0) [0.0|15] ""  BCM
 SG_ Parken_SM_03_Traj_Trans_ID_06 m6  : 3|4@1+ (1.0,0.0) [0.0|15] ""  BCM
 SG_ Parken_Traj_P1_Pos_X m0  : 7|13@1+ (0.5,-2047.5) [-2047.5|2048.0] "Unit_Centimeter"  BCM
 SG_ Parken_Traj_P2_Pos_Y m1  : 7|13@1+ (0.5,-2047.5) [-2047.5|2048.0] "Unit_Centimeter"  BCM
 SG_ Parken_Traj_P3_Tangent m2  : 7|10@1+ (0.3515625,0) [0E-7|359.6484375] "Unit_DegreOfArc"  BCM
 SG_ Parken_Traj_P5_Pos_X m3  : 7|13@1+ (0.5,-2047.5) [-2047.5|2048.0] "Unit_Centimeter"  BCM
 SG_ Parken_Traj_P6_Pos_Y m4  : 7|13@1+ (0.5,-2047.5) [-2047.5|2048.0] "Unit_Centimeter"  BCM
 SG_ Parken_Traj_P7_Tangent m5  : 7|10@1+ (0.3515625,0) [0E-7|359.6484375] "Unit_DegreOfArc"  BCM
 SG_ Parken_Traj_P9_Pos_X m6  : 7|13@1+ (0.5,-2047.5) [-2047.5|2048.0] "Unit_Centimeter"  BCM
 SG_ Parken_Traj_P4_Pos_X m2  : 17|13@1+ (0.5,-2047.5) [-2047.5|2048.0] "Unit_Centimeter"  BCM
 SG_ Parken_Traj_P8_Pos_X m5  : 17|13@1+ (0.5,-2047.5) [-2047.5|2048.0] "Unit_Centimeter"  BCM
 SG_ Parken_Traj_P1_Pos_Y m0  : 20|13@1+ (0.5,-2047.5) [-2047.5|2048.0] "Unit_Centimeter"  BCM
 SG_ Parken_Traj_P2_Tangent m1  : 20|10@1+ (0.3515625,0) [0E-7|359.6484375] "Unit_DegreOfArc"  BCM
 SG_ Parken_Traj_P5_Pos_Y m3  : 20|13@1+ (0.5,-2047.5) [-2047.5|2048.0] "Unit_Centimeter"  BCM
 SG_ Parken_Traj_P6_Tangent m4  : 20|10@1+ (0.3515625,0) [0E-7|359.6484375] "Unit_DegreOfArc"  BCM
 SG_ Parken_Traj_P9_Pos_Y m6  : 20|13@1+ (0.5,-2047.5) [-2047.5|2048.0] "Unit_Centimeter"  BCM
 SG_ Parken_Traj_P3_Pos_X m1  : 30|13@1+ (0.5,-2047.5) [-2047.5|2048.0] "Unit_Centimeter"  BCM
 SG_ Parken_Traj_P4_Pos_Y m2  : 30|13@1+ (0.5,-2047.5) [-2047.5|2048.0] "Unit_Centimeter"  BCM
 SG_ Parken_Traj_P7_Pos_X m4  : 30|13@1+ (0.5,-2047.5) [-2047.5|2048.0] "Unit_Centimeter"  BCM
 SG_ Parken_Traj_P8_Pos_Y m5  : 30|13@1+ (0.5,-2047.5) [-2047.5|2048.0] "Unit_Centimeter"  BCM
 SG_ Parken_Traj_P1_Tangent m0  : 33|10@1+ (0.3515625,0) [0E-7|359.6484375] "Unit_DegreOfArc"  BCM
 SG_ Parken_Traj_P5_Tangent m3  : 33|10@1+ (0.3515625,0) [0E-7|359.6484375] "Unit_DegreOfArc"  BCM
 SG_ Parken_Traj_P9_Tangent m6  : 33|10@1+ (0.3515625,0) [0E-7|359.6484375] "Unit_DegreOfArc"  BCM
 SG_ Parken_Traj_P2_Pos_X m0  : 43|13@1+ (0.5,-2047.5) [-2047.5|2048.0] "Unit_Centimeter"  BCM
 SG_ Parken_Traj_P3_Pos_Y m1  : 43|13@1+ (0.5,-2047.5) [-2047.5|2048.0] "Unit_Centimeter"  BCM
 SG_ Parken_Traj_P4_Tangent m2  : 43|10@1+ (0.3515625,0) [0E-7|359.6484375] "Unit_DegreOfArc"  BCM
 SG_ Parken_Traj_P6_Pos_X m3  : 43|13@1+ (0.5,-2047.5) [-2047.5|2048.0] "Unit_Centimeter"  BCM
 SG_ Parken_Traj_P7_Pos_Y m4  : 43|13@1+ (0.5,-2047.5) [-2047.5|2048.0] "Unit_Centimeter"  BCM
 SG_ Parken_Traj_P8_Tangent m5  : 43|10@1+ (0.3515625,0) [0E-7|359.6484375] "Unit_DegreOfArc"  BCM

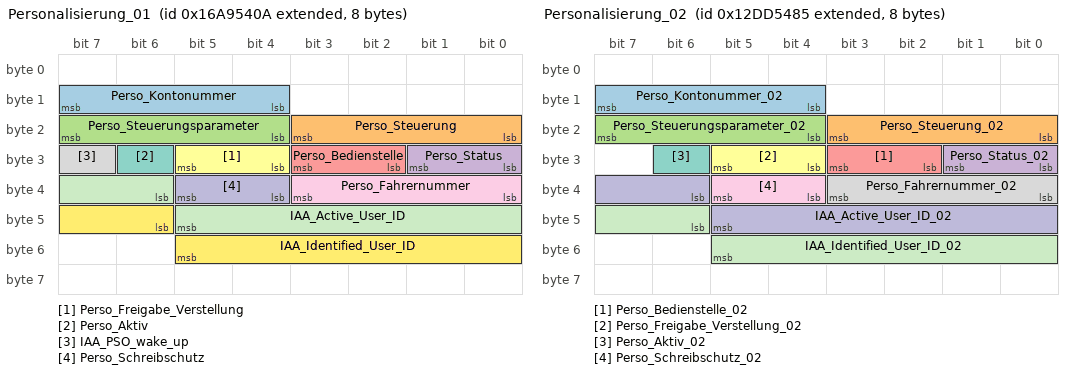
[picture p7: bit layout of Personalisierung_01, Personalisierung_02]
BO_ 2527679498 Personalisierung_01: 8 BCM
 SG_ Perso_Kontonummer : 12|4@1+ (1.0,0.0) [0.0|15] ""  Gateway_Max,TSGGen3_BFS,TSGGen3_FS,TSGGen3_HBFS,TSGGen3_HFS
 SG_ Perso_Steuerung : 16|4@1+ (1.0,0.0) [0.0|15] ""  Gateway_Max,TSGGen3_BFS,TSGGen3_FS,TSGGen3_HBFS,TSGGen3_HFS
 SG_ Perso_Steuerungsparameter : 20|4@1+ (1.0,0.0) [0.0|15] ""  Gateway_Max,TSGGen3_BFS,TSGGen3_FS,TSGGen3_HBFS,TSGGen3_HFS
 SG_ Perso_Status : 24|2@1+ (1.0,0.0) [0.0|3] ""  Gateway_Max,TSGGen3_BFS,TSGGen3_FS,TSGGen3_HBFS,TSGGen3_HFS
 SG_ Perso_Bedienstelle : 26|2@1+ (1.0,0.0) [0.0|3] ""  Gateway_Max
 SG_ Perso_Freigabe_Verstellung : 28|2@1+ (1.0,0.0) [0.0|3] ""  Gateway_Max
 SG_ Perso_Aktiv : 30|1@1+ (1.0,0.0) [0.0|1] ""  Gateway_Max
 SG_ IAA_PSO_wake_up : 31|1@1+ (1.0,0.0) [0.0|1] ""  Gateway_Max
 SG_ Perso_Fahrernummer : 32|4@1+ (1.0,0.0) [0.0|15] ""  Gateway_Max,TSGGen3_BFS,TSGGen3_FS,TSGGen3_HBFS,TSGGen3_HFS
 SG_ Perso_Schreibschutz : 36|2@1+ (1.0,0.0) [0.0|3] ""  Gateway_Max
 SG_ IAA_Active_User_ID : 38|8@1+ (1,0) [0|255] "Unit_None"  Gateway_Max
 SG_ IAA_Identified_User_ID : 46|8@1+ (1,0) [0|255] "Unit_None"  Gateway_Max

BO_ 2463978629 Personalisierung_02: 8 Gateway_Max
 SG_ Perso_Kontonummer_02 : 12|4@1+ (1.0,0.0) [0.0|15] ""  BCM
 SG_ Perso_Steuerung_02 : 16|4@1+ (1.0,0.0) [0.0|15] ""  BCM
 SG_ Perso_Steuerungsparameter_02 : 20|4@1+ (1.0,0.0) [0.0|15] ""  BCM
 SG_ Perso_Status_02 : 24|2@1+ (1.0,0.0) [0.0|3] ""  BCM
 SG_ Perso_Bedienstelle_02 : 26|2@1+ (1.0,0.0) [0.0|3] ""  BCM
 SG_ Perso_Freigabe_Verstellung_02 : 28|2@1+ (1.0,0.0) [0.0|3] ""  BCM
 SG_ Perso_Aktiv_02 : 30|1@1+ (1.0,0.0) [0.0|1] ""  BCM
 SG_ Perso_Fahrernummer_02 : 32|4@1+ (1.0,0.0) [0.0|15] ""  BCM
 SG_ Perso_Schreibschutz_02 : 36|2@1+ (1.0,0.0) [0.0|3] ""  BCM
 SG_ IAA_Active_User_ID_02 : 38|8@1+ (1,0) [0|255] "Unit_None"  BCM
 SG_ IAA_Identified_User_ID_02 : 46|8@1+ (1,0) [0|255] "Unit_None"  BCM

CM_ BO_ 1601 "ab MQB mit CRC-8";
CM_ BO_ 2549940736 "VDC funktionaler Request auf CANHS";
CM_ BO_ 2621506048 "VDC funktionaler Request auf CANFD";

CM_ SG_ 332 CE_FlgLnchCtlPreCnd "Launch Control: status of combustion engine preconditions";
CM_ SG_ 332 FoD_DTC_TSK_ACC "DTC ist entweder bereits eingetragen oder wird eingetragen, sobald die zugehörige FOD Funktion freigeschaltet wird.";
CM_ SG_ 332 FoD_DTC_TSK_GRA "DTC ist entweder bereits eingetragen oder wird eingetragen, sobald die zugehörige FoD Funktion freigeschaltet wird.";
CM_ SG_ 332 ISA_Regelung_aktiv "Signalisiert, dass die Regelung zur Überführung der Fahrzeuggeschwindigkeit auf ein gültiges Tempolimit der Funktion Intelligent Speed Assist (ISA) aktiv ist.";
CM_ SG_ 332 ISA_Status "Signalisiert den Status der Funktion Intelligent Speed Assist (ISA). Der Status zeigt an, ob ISA Tempolimits übernimmt und einregelt. Dabei wird unterschieden, ob es sich um eine globale Aktivierung/Deaktivierung der Funktion, oder um eine temporäre Einsc";
CM_ SG_ 332 ISA_Tempolimitwarnung "Signal zur Ausgabe einer Warnung an den Fahrer, wenn bei aktiviertem Intelligent Speed Assit (ISA) das gültige Tempolimit überschritten wird.";
CM_ SG_ 332 MO_Anforderung_HMS "Halteanforderung vom Motor an HMS";
CM_ SG_ 332 MO_EBoost_verf_praed "Zeigt an, ob für eine im Projekt definierte Zeit (max. 10s) E-Boost in Höhe von EM1_maxPred_Moment verfügbar sein wird.

0 - Init_oder_nicht_verfügbar
1 - EBoost_kurzzeit_verfügbar (~3Sek.)
2 - EBoost_langzeit_verfügbar (~10Sek)";
CM_ SG_ 332 MO_eLaunch_verf "Zeigt an, ob aus Antriebssicht E-Launch verfügbar ist.";
CM_ SG_ 332 MO_EMG_Max_Leistung "zugeteilte elektrische Leistung für den motorischen Betrieb;
elektrische Leistung zur Berechnung eines momentan möglichen maximalen Moments";
CM_ SG_ 332 MO_EMG_Min_Leistung "zugeteilte elektrische Leistung für den generatorischen Betrieb;
elektrische Leistung zur Berechnung eines momentan möglichen minimalen Moments";
CM_ SG_ 332 MO_Fahrbereitschaft "Das Signal MO_Fahrbereitschaft zeigt in mehreren Stufen an, ob der Motor in einem anfahrbereiten Zustand ist.";
CM_ SG_ 332 MO_Freilauf_Info "Freilauf Informationssignal vom Motorsteuergerät zum Getriebesteuergerät. Das Motorsteuergerät kann über dieses Signal den Freilauf freigeben, verhindern bzw. explizit anfordern.";
CM_ SG_ 332 MO_Freilauf_Status "Freilauf-Status-Signal vom Frailauf-Master an aktive Freilauf-Teilnehmer. In diesem Signal zeigt der Freilauf-Master an, welchen aktuellen Status die Freilauf-Betriebsstrategie hat.";
CM_ SG_ 332 MO_Heckspoiler_Anf "Anforderung den Heckspoiler zur Ladeluft- bzw. Motorraumkühlung auszufahren.";
CM_ SG_ 332 MO_Klima_Regelmodus "Anforderung an Klima SG zur Regelungsanpassung der HV Klimakomponenten bei bestimmten Umweltbedingungen";
CM_ SG_ 332 MO_Krit_Heckobjekt "Beschreibt die Kritikalität des hinter einem in der Spur fahrenden Fahrzeuges";
CM_ SG_ 332 MO_Kuppl_betaetigt "Das Motorsteuergerät gibt eine plausibilisierte Information aus, ob die Kupplung betätigt oder nicht betätigt wurde.";
CM_ SG_ 332 MO_LaunchControl "Signalisierung einer verfügbaren LaunchControl Funktion ans Kombiinstrument";
CM_ SG_ 332 MO_MVEM_MaxLeistung_MVVerbrauch "Einzuhaltende Max-Grenze der Leistungsaufnahme bzw. -abgabe der 48V-Verbraucher (inkl 48V-DC/DC-Wandler) im 48V-Netz. Für Begrenzung der Leistungsaufnahme der MV-Verbraucher vorgesehen.

Verbrauch - positiv";
CM_ SG_ 332 MO_MVEM_MinLeistung_MVVerbrauch "Einzuhaltende Min-Grenze der Leistungsaufnahme bzw. -abgabe der 48V-Verbraucher (inkl 48V-DC/DC-Wandler) im 48V-Netz. Für Anforderung einer Leistungsaufnahme der MV-Verbraucher vorgesehen. 
 
Verbrauch - positiv
Rückspeisung - negativ";
CM_ SG_ 332 MO_NGS_Gangpos "Gang- bzw. Neutralinformation des erweiterten Neutralgangsensors. Bedingt durch den eingeschränkten Erfassungssbereich des Sensors sind die Ganginformationen als eingelegt bzw. fast eingelegt/vorausgewählt zu interpretieren (nur Handschalter)";
CM_ SG_ 332 MO_Positionierung_aktiv "Zeigt an, dass die Motorpositionierung mit Hilfe des Riemenstartergenerator momentan aktiv ist.";
CM_ SG_ 332 MO_QBit_Aussen_Temp "QBit der Aussentemperatur. Gesetzt bei Ersatzwert, Init oder Fehler.";
CM_ SG_ 332 MO_QBit_Kuppl_betaetigt "Q - Bit für das Signal Kupplung betätigt";
CM_ SG_ 332 MO_Red_El_Fahrleistung "Anzeige einer eingeschränkten Fahrleistung";
CM_ SG_ 332 MO_Servicemodus "Ausgabe aktiver Service-Mode";
CM_ SG_ 332 MO_Startwunsch "o	Setzen bei Erfüllung der kompletten Fahrerbedienhandlung (z.B. Zündanlasstaster + Bremse + Fahrstufe P/N [klassisch] oder Fahrstufe D/R + Bremse [MEB]), je nach Fahrzeug z.T. bereits vor oder immer erst nach Einschalten der Klemme 15;
o	Rücksetzen bei ";
CM_ SG_ 332 MO_UBE_Hybrid_Reserve "Seitens Antrieb in einem (P)HEV erforderliche Energiereserve der HV-Batterie, die den Fußpunkt der „Usable Battery Energy“ (BMS_UBE) verschiebt. Die Reserve dient der Darstellung von Hybrid-Grundfunktionen (z.B. Start/Stopp, elektrisch Kriechen,usw.) unte";
CM_ SG_ 332 MO_UBE_Reserve "Seitens Antrieb erforderliche Energiereserve der HV-Batterie, die den Fußpunkt der „Usable Battery Energy“ (BMS_UBE) verschiebt. Die Reserve dient der Gewährleistung von Sicherheitsfunktionen und ggf. Emissionierungsmaßnahmen unterhalb des Fahrbetriebs im";
CM_ SG_ 332 MO_Veto_Launchcontrol "Veto des Motor-Steuergeräts bzgl. der Aktivierung der Launch-Control";
CM_ SG_ 332 Motor_54_BZ "4bit Botschaftszähler, wird mit jeder Sendebotschaft inkrementiert";
CM_ SG_ 332 Motor_54_CRC "Für MLB:
Berechnung siehe Lastenheft 'Kommunikationsabsicherung für FlexRay und CAN'
Ab MQB und MLBevo:
Berechnung siehe Lastenheft 'End-to-End Kommunikationsabsicherung'

Endwerte siehe Begleitdokument 'S-PDU Kennungsfolgen'";
CM_ SG_ 332 OBD_Abs_Load_Val "Absolute Load Value

Übertragung von Meßgrößen an das Getriebesteuergerät für Freeze Frame Abspeicherung bei Getriebefehlern

PID $43 Absolute Load Value; 0 .. 25700%  mit 100/255 %/bit";
CM_ SG_ 332 OBD_Abs_Pedal_Pos "Absolute Pedal Position

Übertragung von Meßgrößen an das Getriebesteuergerät für Freeze Frame Abspeicherung bei Getriebefehlern

PID $49 Accelerator Pedal Position D; 0 .. 100% mit 100/255 %/bit";
CM_ SG_ 332 OBD_Abs_Throttle_Pos "Absolute Throttle Position

Übertragung von Meßgrößen an das Getriebesteuergerät für Freeze Frame Abspeicherung bei Getriebefehlern

PID $11 Absolute Throttle Position; 0 .. 100% mit 100/255 %/bit";
CM_ SG_ 332 OBD_Aussen_Temp_gef "Gefilterte Aussentemperatur vom Motor für OBD Funktionen.";
CM_ SG_ 332 OBD_Calc_Load_Val "Calculated Load Value

Übertragung von Meßgrößen an das Getriebesteuergerät für Freeze Frame Abspeicherung bei Getriebefehlern

PID $04 Calculated Load Value; 0 .. 100% mit 100/255 % per bit
";
CM_ SG_ 332 OBD_ClearMem_Inhibit "Bei FSP_Loeschen_zulässig müssen alle OBD-ECUs im Gesamtfahrzeug einen Service 04hex Request (Ereignisspeicher löschen) korrekt ausführen. 

In MLB-, MLBevo-, MQB-Fahrzeugkonzepten muss der MIL-Master/Motorsteuergerät bei Kl.15 ein, projektabhängig, kon";
CM_ SG_ 332 OBD_Driving_Cycle "Signalisierung Driving Cycle Qualifizierung - Trigger Ignition Cycle Counter";
CM_ SG_ 332 OBD_Eng_Cool_Temp "Engine Coolant Temperature

Übertragung von Meßgrößen an das Getriebesteuergerät für Freeze Frame Abspeicherung bei Getriebefehlern

PID $05 Engine Coolant Temperature; -40 .. +215°C mit 1°C/bit und 40°C Offset";
CM_ SG_ 332 OBD_Kaltstart_Denominator "Bestimmte Diagnosen werden nur unter Kaltstartbedingungen durchgeführt, der entsprechende Denominator bei IUMPR-pflichtigen Systemen wird anhand dieses vom MSG gebildeten Signals inkrementiert. (Entspricht EVAP-Denominator)";
CM_ SG_ 332 OBD_Minimum_Trip "Grundlage OBD-Gesetz CCR 1968.2 (d)(4.3) Denominator Specifications
Bildung des General Denominator 'Normed Trip':
 600 sec. (kumulativ) Zeit nach Motorstart
 300 sec. (kumulativ) mit Fahrzeuggeschwindigkeit > 25 mph (40 km/h)
 30 sec. (kontinuierlich";
CM_ SG_ 332 OBD_Normed_Trip "Gesetzlich definierte 'Normed Condition' erfüllt, 'General Denominator' darf erhöht werden";
CM_ SG_ 332 OBD_Sperrung_IUMPR "Wenn der General Denominator auf Grund eines Fehlers in den Eingangsgrößen gesperrt wird, wird diese Information über Bussystem als OBD-Statusinformation OBD_Sperrung_IUMPR für andere OBD-Steuergeräte bereitgestellt. 

Das MSG (MIL-Master) setzt dieses ";
CM_ SG_ 332 OBD_Sperrung_Kaltstart_Denom "Information vom MIL Master, dass die Bildung des EVAP Denominators  im Motor nicht möglich ist und damit der noECM-Denominator gesperrt werden darf.";
CM_ SG_ 332 OBD_Warm_Up_Cycle "Mit dem Warm-Up-Cycle wird der zentrale Verlernzähler vom Gateway inkrementiert";
CM_ SG_ 332 OBDProtocol_req "Der PrimaryOBDECU_MILMaster stellt allen PrimaryOBDECUnoMILMaster über das Bussignal [OBDProtocol_req], das für das Fahrzeug zu verwendende OBD-Diagnoseprotokoll bereit.";
CM_ SG_ 332 TSK_ACC_FoD_Status "Information, ob die TSK-ACC-Funktion freigeschaltet ist oder nicht.";
CM_ SG_ 332 TSK_aktives_System "Anzeige der in der TSK-Längsführung aktiven Funktion";
CM_ SG_ 332 TSK_aktives_System_02 "Anzeige der in der TSK-Längsführung aktiven Funktion";
CM_ SG_ 332 TSK_Anf_Antriebsmoment "Das Signal zeigt an, ob die TSK-Laengsregelung aktuell Antriebsmoment anfordert, zur Verwendung in der ASR/EDS-Funktion";
CM_ SG_ 332 TSK_Einheit_vMax_Fahrerassistenz "Einheit zu Signal TSK_vMax_Fahrerassistenz";
CM_ SG_ 332 TSK_erhoehter_Fahrwiderstand "Rueckmeldung vom Triebstrangkoordinator, dass eine große Reglerdifferenz detektiert wurde. Soll ermoeglichen, einen ggfs. unbekannten Fahrwiderstand am Boden zu erkennen.";
CM_ SG_ 332 TSK_GRA_FoD_Status "Information, ob die TSK-GRA-Funktion freigeschaltet ist oder nicht.";
CM_ SG_ 332 TSK_Status_ARA "Funktionsstatus des Triebstrangkoordinators für den Anhängerrangierassistenten";
CM_ SG_ 332 TSK_Status_EA "Funktionsstatus des Triebstrangkoordinators für den Anforderer Emergency Assist";
CM_ SG_ 332 TSK_Status_IPA "Funktionsstatus des Triebstrangkoordinators für die Längsführung des Einparkassistenten";
CM_ SG_ 332 TSK_Status_PLA "Funktionsstatus des Triebstrangkoordinators für den Speedlimiter des Parkassistenten";
CM_ SG_ 332 TSK_Status_RHP "Functional status of the drive train coordinator for the longitudinal guidance of the rush hour pilot.";
CM_ SG_ 332 TSK_vMax_aktuell "Im aktuellen Betriebszustand global gültige Geschwindigkeitslimitierung.";
CM_ SG_ 332 TSK_vMax_Fahrerassistenz "maximale Sollgeschwindigkeit für GRA/ACC/Limiter
Hinweis: Signal ist mit Signal TSK_Einheit_vMax_Fahrerassistenz zu interpretieren.  Das Signal wird abwechselnd in km/h und mph gesendet.";

CM_ SG_ 1601 MO_Ansaugsystem "Art des Ansaugsystems des Verbrennungsmotors";
CM_ SG_ 1601 MO_Anzahl_Zyl "Zylinderzahl des Verbrennungsmotors";
CM_ SG_ 1601 MO_Anzeige_StSt_gueltig "Zeigt die Gültigkeit der neuen StSt-Anzeigesignale an, MO_Anzeige_StSt_Text und  MO_Anzeige_Symbol. Mo_Text_Motorstart 1..5 sind zu ignorieren.";
CM_ SG_ 1601 MO_Code "Motorcodierinformation Version 16 (Details siehe Anhang)";
CM_ SG_ 1601 MO_DPF_verbaut "Verbauinformation Diesel-Partikel-Filter
";
CM_ SG_ 1601 MO_Faktor_Momente_02 "Dieses Signal schaltet den Wertebereich aller Momente vom Motor, Getriebe, TSK, Bremse ... um! Die Momente besitzen somit einen variablen Wertebereich, weil sich durch den Faktor die Momente sowohl in Auflösung als auch Maximalwerten ändert.

0x0 nicht ";
CM_ SG_ 1601 MO_Getriebe_Code "Getriebecodierung des Motors";
CM_ SG_ 1601 MO_Hubraum "Hubraum des Verbrennungsmotors";
CM_ SG_ 1601 MO_Hybridfahrzeug "Anhand dieses Signals plausibilisiert die Lenkhilfe das Bit Fahrbereitschaft.

Im Projekt Cayenne PHEV (und ggf. auch VW526 PHEV) ist aus Gründen der Abwärtskompatibilität der Wert '2' zu senden.";
CM_ SG_ 1601 MO_Kraftstoffart "Primärkraftstoff zum Antrieb des Fahrzeugs";
CM_ SG_ 1601 MO_Leistung "Nennleistung des Verbrennungsmotors

Im reinen E-Fahrzeug (BEV): Ausgabe der elektrischen Systemleistung";
CM_ SG_ 1601 MO_OBD_Typ "Abgastyp OBD
Hinweis: In Fahrzeugen mit dem Zielmarkt China und einer Zertifizierung ab China 6 muss auf dem Signal 'MO_OBD_Typ' der Wert 'US_OBD' gesendet werden.";
CM_ SG_ 1601 MO_StartStopp_Codiert "Funktion StartStopp im aktuellen Klemmenzyklus verbaut";
CM_ SG_ 1601 Motor_Code_01_CRC "Für MLB:
'Berechnung siehe Lastenheft 'Kommunikationsabsicherung für FlexRay und CAN''

Ab MQB und MLBevo:
'Berechnung siehe Lastenheft 'End-to-End Kommunikationsabsicherung''

Endwerte siehe Begleitdokument 'S-PDU Kennungsfolgen'";
CM_ SG_ 1601 TSK_Codierung "Information über den plausibilisierten Codierungszustand des Triebstrangskoordinators auf ACC oder GRA.";

CM_ SG_ 391 EV_Rekuperationsstufe "Im Kombi anzuzeigende Rekuperationsstufe";
CM_ SG_ 391 MO_Drehzahl_VM "Motordrehzahl des Verbrennungsmotors

für OBD freeze frame

Hinweis: 
Ehemaliger Fehlerwert 0xFFFF wird senderseitig nicht unterstützt. 
Diesen Wert aus Kompatibilitätsgründen nicht neu belegen!";
CM_ SG_ 391 MO_Fehler_Notabschaltung_Klima "Das Signal dient der schnellen Abschaltung der Klimakomponenten (EKK, HV-Heizung) durch den HV-Koordinator (MSG) nach einem HV-Interlock Ereignis.";
CM_ SG_ 391 MO_Fehler_NTKreis "Fehlerstatus Niedertemperaturkreis";
CM_ SG_ 391 MO_KLE_FStatus "Fehlerstatus der Kühlerlüfterelektronik";
CM_ SG_ 391 MO_Tankbereitschaft_Status "Meldung der Tankbereitschaft";
CM_ SG_ 391 MO_Tankklappensteuerung "Ansteuerungsanforderung der Tankklappe";
CM_ SG_ 391 MO_Waehlpos "Wählhebelposition (im VW120/7 und MQB BEV ist der Wählhebel am HCAN mit Master Motor-SG angeschlossen)

(wenn das Signal zusätzlich in Botschaft MSG_HYB_03 verortet ist, gilt: Signal nur in der CAN-Welt PQ35/25 zu verwenden, da dort am ACAN die Wählhebe";
CM_ SG_ 391 MO_WH_Texte "Fahrerhinweise für das Kombi";
CM_ SG_ 391 Motor_EV_01_BZ "Fehlende Beschreibung (Import)";
CM_ SG_ 391 Motor_EV_01_CRC "Für MLB:
'Berechnung siehe Lastenheft 'Kommunikationsabsicherung für FlexRay und CAN''

Ab MQB und MLBevo:
'Berechnung siehe Lastenheft 'End-to-End Kommunikationsabsicherung''

Endwerte siehe Begleitdokument 'S-PDU Kennungsfolgen'";

CM_ SG_ 2527679770 NavMan_ApproachDistanceInPercent "The distance to the maneuver point within the approach range as defined by the service for each maneuver. 100 = maximum distance to the maneuver within the approaching range, 0 = maneuver point reached.";
CM_ SG_ 2527679770 NavMan_DirectionType "The direction type of the maneuver
0 -> Straight
64 -> Left
128 -> Back
192 -> Right";
CM_ SG_ 2527679770 NavMan_Distance "Maneouvering Information for brand specific (SEAT) lighting events";
CM_ SG_ 2527679770 NavMan_Distance_Unit "Maneouvering Information for brand specific (SEAT) lighting events";
CM_ SG_ 2527679770 NavMan_MainType "The type of the requested maneuver encoded in a integer.";

CM_ SG_ 2527679645 NFC_MiKo_ESM_aktiv "Energiesparmodus ist aktiv, z.B. nach 72h Fahrzeugstillstand";
CM_ SG_ 2527679645 NFC_MiKo_Fehler "Das Steuergeraet hat einen Fehler und ist nicht komplett einsatzfaehig.";
CM_ SG_ 2527679645 NFC_MiKo_Laden_unterbrechen "Anforderung seitens Mittelkonsolen-STG das Laden in der Phonebox zu unterbrechen";
CM_ SG_ 2527679645 NFC_MiKo_NFC_Device_gekoppelt "Ein NFC-Device ist im Empfangsbereich und der NFC-Reader hat eine aktive Verbindung aufgebaut.";
CM_ SG_ 2527679645 NFC_MiKo_NFC_Device_Status "Status der aktuellen NFC Erkennung";

CM_ SG_ 2527679646 KY_Oeffnen_Annaeherung "Der Kapazitive Sensor hat eine Annaeherung zum Oeffnen erkannt.";
CM_ SG_ 2527679646 KY_Oeffnen_Betaetigung "Der Kapazitive Sensor hat eine Betaetigung zum Oeffnen erkannt.";
CM_ SG_ 2527679646 KY_Schliessen_Annaeherung "Der Kapazitive Sensor hat eine Annaeherung zum Schliessen erkannt.";
CM_ SG_ 2527679646 KY_Schliessen_Betaetigung "Der Kapazitive Sensor hat eine Betaetigung zum Schliessen erkannt.";
CM_ SG_ 2527679646 NFC_TGS_ESM_aktiv "Energiesparmodus ist aktiv, z.B. nach 72h Fahrzeugstillstand";
CM_ SG_ 2527679646 NFC_TGS_Fehler "Das Steuergeraet hat einen Fehler und ist nicht komplett einsatzfaehig.";
CM_ SG_ 2527679646 NFC_TGS_Licht_Fehler "Sammelsignal für Fehler, die ein Lichtmodul hat, das in den NFC-Türgriff integriert ist";
CM_ SG_ 2527679646 NFC_TGS_NFC_Device_gekoppelt "Ein NFC-Device ist im Empfangsbereich und der NFC-Reader hat eine aktive Verbindung aufgebaut.";
CM_ SG_ 2527679646 NFC_TGS_NFC_Device_Status "Status der aktuellen NFC Erkennung";

CM_ SG_ 2600468494 NM_BCM1_CAB_V14 "CAB_01_Antrieb
Remotestartvoraussetzungen nach Bedienhandlung prüfen
Aktive Verlassenswarn. (Aktive Warnung max.5min; Stillstand, nicht p-verriegelt, Tür offen)
CAB_02_Hybrid_Laden
ZV Zust.wchsl. (ZV Zust.wchsl. verriegelt/gesafet steuert Ladeklappe u";
CM_ SG_ 2600468494 NM_BCM1_Car_Wakeup "Car Wakeup (Gateway wertet aus)

MQB: 
-Kl.58xd, Kl.58xs, Kl.58xt eingeschaltet oder ausgeschaltet oder Dimmungssignal wurde vom Kunden geändert (nicht vom Fototransistor)
-S-Kontakt wurde ein- oder ausgeschaltet
-Remotestartbetrieb
-Tankklappe wurd";
CM_ SG_ 2600468494 NM_BCM1_CBV_AWB "Das Signal ist zu setzen, wenn das SG aktiv den Bus geweckt hat
0 = Passiver_WakeUp = SG hat das Netzwerk nicht aktiv geweckt
1 = Akitiver_WakeUp = SG hat das Netzwerk aktiv geweckt";
CM_ SG_ 2600468494 NM_BCM1_CBV_CRI "Das Signal ist dauerhaft gesetzt, wenn das NM-Layout Cluster- Anforderungen enthält";
CM_ SG_ 2600468494 NM_BCM1_NM_aktiv_Applikation "Eine Applikationsanforderung fordert den Bus.";
CM_ SG_ 2600468494 NM_BCM1_NM_aktiv_Aussenlicht "Funktionsnachlauf Außenlicht (inkl. Blinken, Warnblinken, Lichthupe)";
CM_ SG_ 2600468494 NM_BCM1_NM_aktiv_Diagnose "Diagnose befindet sich nach VW80124 in einer NonDefaultDiagnostic-Session, z.B. ExtendedDiagnostic-Session";
CM_ SG_ 2600468494 NM_BCM1_NM_aktiv_DWA "Funktionsnachlauf Diebstahlwarnanlage";
CM_ SG_ 2600468494 NM_BCM1_NM_aktiv_Funk "Funktionsnachlauf Funk";
CM_ SG_ 2600468494 NM_BCM1_NM_aktiv_Heizung "Funktionsnachlauf Klima/Heizung";
CM_ SG_ 2600468494 NM_BCM1_NM_aktiv_Innenlicht "Funktionsnachlauf Innenlicht (inkl. KL 58x)";
CM_ SG_ 2600468494 NM_BCM1_NM_aktiv_Kessy "Funktionsnachlauf Kessy";
CM_ SG_ 2600468494 NM_BCM1_NM_aktiv_KL15 "Steuergerät hat KL15-EIN erkannt";
CM_ SG_ 2600468494 NM_BCM1_NM_aktiv_Remot_Door_L_Un "Remote Door Lock oder Unlock wird ausgefuehrt";
CM_ SG_ 2600468494 NM_BCM1_NM_aktiv_Remotestart "Funktionsnachlauf Remotestart";
CM_ SG_ 2600468494 NM_BCM1_NM_aktiv_TK_geschlossen "Drucktank: Rückmeldung des Tankklappenstatus (Tankklappe wurde geschlossen)";
CM_ SG_ 2600468494 NM_BCM1_NM_aktiv_Tmin "Mindestaktivzeit ist noch nicht abgelaufen (bei jedem Weckereignis wird die Mindestaktivzeit neu gestartet)";
CM_ SG_ 2600468494 NM_BCM1_NM_aktiv_VLW "Über dieses Signal wird eine aktive Verlassenswarnung angezeigt.";
CM_ SG_ 2600468494 NM_BCM1_NM_aktiv_ZV "Funktionsnachlauf Zentralverriegelung";
CM_ SG_ 2600468494 NM_BCM1_NM_State "1 = Zustand Repeat Message (<-- Bus-Sleep Mode)
2 = Zustand Repeat Message (<-- Prepare Bus-Sleep Mode)
4 = Zustand Normal Operation (<-- Repeat Message)
8 = Zustand Normal Operation (<-- Ready Sleep)";
CM_ SG_ 2600468494 NM_BCM1_UDS_CC "Funktionseinschränkung aufgrund aktivem UDS-Communication Control, siehe VW80124";

CM_ SG_ 2600468496 NM_Gateway_CAB_V14 "CAB = Clusteraktivbits (V14)

Cluster CAB_01_Antrieb
-Innenraumklimatisierung starten
-Ladevorbedingung, Beginn des Ladens, Ende
-Lademodusänderung, Timer-Laden vs. Sofort Laden

Cluster CAB_02_Hybrid_Laden
-Laden an oder ausschalten
-Ladevorbedi";
CM_ SG_ 2600468496 NM_Gateway_Car_Wakeup "Car Wakeup (Subbusmaster wertet aus)

MQB: 
-Diagnose- oder Komponentenschutzmaster-Funktion weckt den schlafenden Subbus (z.B. MOST)

E3_Volumen:
- Diagnose aktiv -aktive Diagnosekommunikation am OBD-Stecker

MQBw_Baseline:
- Diagnose aktiv -akt";
CM_ SG_ 2600468496 NM_Gateway_CBV_AWB "Das Signal ist zu setzen, wenn das SG aktiv den Bus geweckt hat
0 = Passiver_WakeUp = SG hat das Netzwerk nicht aktiv geweckt
1 = Akitiver_WakeUp = SG hat das Netzwerk aktiv geweckt";
CM_ SG_ 2600468496 NM_Gateway_CBV_CRI "Das Signal ist dauerhaft gesetzt, wenn das NM-Layout Cluster- Anforderungen enthält";
CM_ SG_ 2600468496 NM_Gateway_NM_aktiv_Buskopplung "Nachlauf aufgrund Kopplung zweier Busse. z.B. K-CAN und K2-CAN";
CM_ SG_ 2600468496 NM_Gateway_NM_aktiv_CWU "Nachlauf aufgrund CWU Anforderung";
CM_ SG_ 2600468496 NM_Gateway_NM_aktiv_Diagnose "Diagnose befindet sich nach VW80124 in einer NonDefaultDiagnostic-Session, z.B. ExtendedDiagnostic-Session";
CM_ SG_ 2600468496 NM_Gateway_NM_aktiv_EM "Nachlauf aufgrund Energiemanagement";
CM_ SG_ 2600468496 NM_Gateway_NM_aktiv_FC "Nachlauf aufgrund Funktionscluster Anforderung";
CM_ SG_ 2600468496 NM_Gateway_NM_aktiv_KL15 "Steuergerät hat KL15-EIN erkannt";
CM_ SG_ 2600468496 NM_Gateway_NM_aktiv_Tmin "Mindestaktivzeit ist noch nicht abgelaufen (bei jedem Weckereignis wird die Mindestaktivzeit neu gestartet)";
CM_ SG_ 2600468496 NM_Gateway_NM_State "1 = Zustand Repeat Message (<-- Bus-Sleep Mode)
2 = Zustand Repeat Message (<-- Prepare Bus-Sleep Mode)
4 = Zustand Normal Operation (<-- Repeat Message)
8 = Zustand Normal Operation (<-- Ready Sleep)";
CM_ SG_ 2600468496 NM_Gateway_UDS_CC "Funktionseinschränkung aufgrund aktivem UDS-Communication Control, siehe VW80124";

CM_ SG_ 2600468555 NM_TSG_BFS_Car_Wakeup "Car Wakeup (Gateway wertet aus)

MQB: 
-Türkontakt öffnen

MQB2020:
-Beifahrertürkontakt öffnen: Vorlauf Infotainment, Türkontakt für Nfz

E3_1_1:
-Beifahrertürkontakt öffnen: Vorlauf Infotainment, Türkontakt für Nfz

E3_1_2:
-Beifahrertürkont";
CM_ SG_ 2600468555 NM_TSG_BFS_CBV_AWB "Das Signal ist zu setzen, wenn das SG aktiv den Bus geweckt hat";
CM_ SG_ 2600468555 NM_TSG_BFS_CBV_CRI "Das Signal ist dauerhaft gesetzt, wenn das NM-Layout dem neuen NM-Layout für Teilnetzbetrieb entspricht";
CM_ SG_ 2600468555 NM_TSG_BFS_NM_aktiv_Diagnose "Diagnose befindet sich nach VW80124 in einer NonDefaultDiagnostic-Session, z.B. ExtendedDiagnostic-Session";
CM_ SG_ 2600468555 NM_TSG_BFS_NM_aktiv_KL15 "Steuergerät hat KL15-EIN erkannt";
CM_ SG_ 2600468555 NM_TSG_BFS_NM_aktiv_LIN "Hinteres TSG (LIN-Slave) meldet keine Schlafbereitschaft.";
CM_ SG_ 2600468555 NM_TSG_BFS_NM_aktiv_Taster "Nachlauf aufgrund Betätigung oder anhaltenden Betätigung einer Taste oder Schalter.
Dies gilt auch für das Senden von Botschaften aufgrund aktiver oder inaktiver Wiederholungen die für Signale von Tasten oder Schalterereignissen definiert wurden.";
CM_ SG_ 2600468555 NM_TSG_BFS_NM_aktiv_Tmin "Mindestaktivzeit ist noch nicht abgelaufen (bei jedem Weckereignis wird die Mindestaktivzeit neu gestartet)";
CM_ SG_ 2600468555 NM_TSG_BFS_NM_State "1 = Zustand Repeat Message (<-- Bus-Sleep Mode)
2 = Zustand Repeat Message (<-- Prepare Bus-Sleep Mode)
4 = Zustand Normal Operation (<-- Repeat Message)
8 = Zustand Normal Operation (<-- Ready Sleep)";
CM_ SG_ 2600468555 NM_TSG_BFS_UDS_CC "Funktionseinschränkung aufgrund aktivem UDS-Communication Control; siehe VW80124";
CM_ SG_ 2600468555 NM_TSG_BT_CAB_V14 "CAB = Clusteraktivbits (V14)

CAB_04_Fahrerassistenz:
- Ausstiegswarnung ASW aktiv (Erstmaliges Öffnen einer Tür nach Entriegelung aktiviert Ausstiegswarnung)";

CM_ SG_ 2600468554 NM_TSG_FS_Car_Wakeup "Car Wakeup (Gateway wertet aus)

MQB:
-Türkontakt öffnen
-Tankwunschtaster betätigt (Drucktank)

MQB2020:
-Türkontakt öffnen
- ASW-aktiv (Erstmaliges Öffnen einer Tür nach Entriegelung aktiviert Ausstiegswarnung)
-Tankwunschtaster betätigt (Druck";
CM_ SG_ 2600468554 NM_TSG_FS_CBV_AWB "Das Signal ist zu setzen, wenn das SG aktiv den Bus geweckt hat";
CM_ SG_ 2600468554 NM_TSG_FS_CBV_CRI "Das Signal ist dauerhaft gesetzt, wenn das NM-Layout dem neuen NM-Layout für Teilnetzbetrieb entspricht";
CM_ SG_ 2600468554 NM_TSG_FS_NM_aktiv_Diagnose "Diagnose befindet sich nach VW80124 in einer NonDefaultDiagnostic-Session, z.B. ExtendedDiagnostic-Session";
CM_ SG_ 2600468554 NM_TSG_FS_NM_aktiv_KL15 "Steuergerät hat KL15-EIN erkannt";
CM_ SG_ 2600468554 NM_TSG_FS_NM_aktiv_LIN "Hinteres TSG (LIN-Slave) meldet keine Schlafbereitschaft.";
CM_ SG_ 2600468554 NM_TSG_FS_NM_aktiv_Taster "Nachlauf aufgrund Betätigung oder anhaltenden Betätigung einer Taste oder Schalter.
Dies gilt auch für das Senden von Botschaften aufgrund aktiver oder inaktiver Wiederholungen die für Signale von Tasten oder Schalterereignissen definiert wurden.
";
CM_ SG_ 2600468554 NM_TSG_FS_NM_aktiv_Tmin "Mindestaktivzeit ist noch nicht abgelaufen (bei jedem Weckereignis wird die Mindestaktivzeit neu gestartet)";
CM_ SG_ 2600468554 NM_TSG_FS_NM_State "1 = Zustand Repeat Message (<-- Bus-Sleep Mode)
2 = Zustand Repeat Message (<-- Prepare Bus-Sleep Mode)
4 = Zustand Normal Operation (<-- Repeat Message)
8 = Zustand Normal Operation (<-- Ready Sleep)";
CM_ SG_ 2600468554 NM_TSG_FS_UDS_CC "Funktionseinschränkung aufgrund aktivem UDS-Communication Control; siehe VW80124";
CM_ SG_ 2600468554 NM_TSG_FT_CAB_V14 "CAB = Clusteraktivbits (V14)

CAB_01_Antrieb:
-Tankwunschtaster betätigt (Drucktank)

CAB_04_Fahrerassistenz:
- Ausstiegswarnung ASW aktiv (Erstmaliges Öffnen einer Tür nach Entriegelung aktiviert Ausstiegswarnung)";

CM_ SG_ 2600468543 NM_TSG_HBFS_CAB_V14 "CAB = Clusteraktivbits (V14)

CAB_04_Fahrerassistenz:
- Ausstiegswarnung ASW aktiv (Erstmaliges Öffnen einer Tür nach Entriegelung aktiviert Ausstiegswarnung)";
CM_ SG_ 2600468543 NM_TSG_HBFS_Car_Wakeup "Car Wakeup (Gateway wertet aus)";
CM_ SG_ 2600468543 NM_TSG_HBFS_CBV_AWB "Das Signal ist zu setzen, wenn das SG aktiv den Bus geweckt hat
0 = Passiver_WakeUp = SG hat das Netzwerk nicht aktiv geweckt
1 = Akitiver_WakeUp = SG hat das Netzwerk aktiv geweckt";
CM_ SG_ 2600468543 NM_TSG_HBFS_CBV_CRI "Das Signal ist dauerhaft gesetzt, wenn das NM-Layout Cluster- Anforderungen enthält";
CM_ SG_ 2600468543 NM_TSG_HBFS_NM_aktiv_Diagnose "Diagnose befindet sich nach VW80124 in einer NonDefaultDiagnostic-Session, z.B. ExtendedDiagnostic-Session";
CM_ SG_ 2600468543 NM_TSG_HBFS_NM_aktiv_KL15 "Steuergerät hat KL15-EIN erkannt";
CM_ SG_ 2600468543 NM_TSG_HBFS_NM_aktiv_Tmin "Mindestaktivzeit ist noch nicht abgelaufen (bei jedem Weckereignis wird die Mindestaktivzeit neu gestartet)";
CM_ SG_ 2600468543 NM_TSG_HBFS_NM_State "1 = Zustand Repeat Message (<-- Bus-Sleep Mode)
2 = Zustand Repeat Message (<-- Prepare Bus-Sleep Mode)
4 = Zustand Normal Operation (<-- Repeat Message)
8 = Zustand Normal Operation (<-- Ready Sleep)";
CM_ SG_ 2600468543 NM_TSG_HBFS_UDS_CC "Funktionseinschränkung aufgrund aktivem UDS-Communication Control, siehe VW80124";

CM_ SG_ 2600468542 NM_TSG_HFS_CAB_V14 "CAB = Clusteraktivbits (V14)

CAB_04_Fahrerassistenz:
- Ausstiegswarnung ASW aktiv (Erstmaliges Öffnen einer Tür nach Entriegelung aktiviert Ausstiegswarnung)";
CM_ SG_ 2600468542 NM_TSG_HFS_Car_Wakeup "Car Wakeup (Gateway wertet aus)";
CM_ SG_ 2600468542 NM_TSG_HFS_CBV_AWB "Das Signal ist zu setzen, wenn das SG aktiv den Bus geweckt hat
0 = Passiver_WakeUp = SG hat das Netzwerk nicht aktiv geweckt
1 = Akitiver_WakeUp = SG hat das Netzwerk aktiv geweckt";
CM_ SG_ 2600468542 NM_TSG_HFS_CBV_CRI "Das Signal ist dauerhaft gesetzt, wenn das NM-Layout Cluster- Anforderungen enthält";
CM_ SG_ 2600468542 NM_TSG_HFS_NM_aktiv_Diagnose "Diagnose befindet sich nach VW80124 in einer NonDefaultDiagnostic-Session, z.B. ExtendedDiagnostic-Session";
CM_ SG_ 2600468542 NM_TSG_HFS_NM_aktiv_KL15 "Steuergerät hat KL15-EIN erkannt";
CM_ SG_ 2600468542 NM_TSG_HFS_NM_aktiv_Tmin "Mindestaktivzeit ist noch nicht abgelaufen (bei jedem Weckereignis wird die Mindestaktivzeit neu gestartet)";
CM_ SG_ 2600468542 NM_TSG_HFS_NM_State "1 = Zustand Repeat Message (<-- Bus-Sleep Mode)
2 = Zustand Repeat Message (<-- Prepare Bus-Sleep Mode)
4 = Zustand Normal Operation (<-- Repeat Message)
8 = Zustand Normal Operation (<-- Ready Sleep)";
CM_ SG_ 2600468542 NM_TSG_HFS_UDS_CC "Funktionseinschränkung aufgrund aktivem UDS-Communication Control, siehe VW80124";

CM_ SG_ 2600468645 NM_WLC1_aktiv_Diagnose "Diagnose befindet sich nach VW80124 in einer NonDefaultDiagnostic-Session, z.B. ExtendedDiagnostic-Session";
CM_ SG_ 2600468645 NM_WLC1_aktiv_Tmin "Mindestaktivzeit ist noch nicht abgelaufen (bei jedem Weckereignis wird die Mindestaktivzeit neu gestartet)";
CM_ SG_ 2600468645 NM_WLC1_CAB_V14 "CAB = Clusteraktivbits (V14)";
CM_ SG_ 2600468645 NM_WLC1_Car_Wakeup "Car Wakeup (Gateway wertet aus)";
CM_ SG_ 2600468645 NM_WLC1_CBV_AWB "Das Signal ist zu setzen, wenn das SG aktiv den Bus geweckt hat
0 = Passiver_WakeUp = SG hat das Netzwerk nicht aktiv geweckt
1 = Akitiver_WakeUp = SG hat das Netzwerk aktiv geweckt";
CM_ SG_ 2600468645 NM_WLC1_CBV_CRI "Das Signal ist dauerhaft gesetzt, wenn das NM-Layout Cluster- Anforderungen enthält";
CM_ SG_ 2600468645 NM_WLC1_NM_aktiv_KL15 "Steuergerät hat KL15-EIN erkannt";
CM_ SG_ 2600468645 NM_WLC1_NM_State "1 = Zustand Repeat Message (<-- Bus-Sleep Mode)
2 = Zustand Repeat Message (<-- Prepare Bus-Sleep Mode)
4 = Zustand Normal Operation (<-- Repeat Message)
8 = Zustand Normal Operation (<-- Ready Sleep)";
CM_ SG_ 2600468645 NM_WLC1_UDS_CC "Funktionseinschränkung aufgrund aktivem UDS-Communication Control, siehe VW80124";

CM_ SG_ 2621440526 OBDC_BCM1_Req_FD_Data "OnBoard Tester Diagnose über ISO TP.";

CM_ SG_ 2621571598 OBDC_BCM1_Resp_FD_Data "OnBoard Tester Diagnose über ISO TP.";

CM_ SG_ 2549875386 OBDC_DDA_Req_Data "TP-Kanal für den Onboard Datensammler";

CM_ SG_ 2550006458 OBDC_DDA_Resp_Data "TP-Kanal für den Onboard Datensammler";

CM_ SG_ 2549940736 OBDC_Funktionaler_Req_All_Data "VDC funktionaler Request auf CANHS";

CM_ SG_ 2621506048 OBDC_Funktion_Req_All_FD_Data "OnBoard Tester funktionaler Diagnose Request ALL";

CM_ SG_ 2550399491 OBDC_RSAD_HL_Req_Data "TP-Kanal für den Onboard Datensammler";

CM_ SG_ 2621702659 OBDC_RSAD_HL_Req_FD_Data "OnBoard Tester Diagnose Request RSAD_HL";

CM_ SG_ 2550530563 OBDC_RSAD_HL_Resp_Data "TP-Kanal für den Onboard Datensammler";

CM_ SG_ 2621833731 OBDC_RSAD_HL_Resp_FD_Data "OnBoard Tester Diagnose Response RSAD_HL";

CM_ SG_ 2550399492 OBDC_RSAD_HR_Req_Data "TP-Kanal für den Onboard Datensammler";

CM_ SG_ 2621702660 OBDC_RSAD_HR_Req_FD_Data "OnBoard Tester Diagnose Request RSAD_HR";

CM_ SG_ 2550530564 OBDC_RSAD_HR_Resp_Data "TP-Kanal für den Onboard Datensammler";

CM_ SG_ 2621833732 OBDC_RSAD_HR_Resp_FD_Data "OnBoard Tester Diagnose Response RSAD_HR";

CM_ SG_ 2621702709 OBDC_RSAD_IN2_Req_FD_Data "OnBoard Tester Diagnose Request RSAD_IN2";

CM_ SG_ 2621833781 OBDC_RSAD_IN2_Resp_FD_Data "OnBoard Tester Diagnose Response RSAD_IN2";

CM_ SG_ 2621702710 OBDC_RSAD_IN3_Req_FD_Data "OnBoard Tester Diagnose Request RSAD_IN3";

CM_ SG_ 2621833782 OBDC_RSAD_IN3_Resp_FD_Data "OnBoard Tester Diagnose Response RSAD_IN3";

CM_ SG_ 2621702711 OBDC_RSAD_IN4_Req_FD_Data "OnBoard Tester Diagnose Request RSAD_IN4";

CM_ SG_ 2621833783 OBDC_RSAD_IN4_Resp_FD_Data "OnBoard Tester Diagnose Response RSAD_IN4";

CM_ SG_ 2550399493 OBDC_RSAD_IN_Req_Data "TP-Kanal für den Onboard Datensammler";

CM_ SG_ 2621702661 OBDC_RSAD_IN_Req_FD_Data "OnBoard Tester Diagnose Request RSAD_IN";

CM_ SG_ 2550530565 OBDC_RSAD_IN_Resp_Data "TP-Kanal für den Onboard Datensammler";

CM_ SG_ 2621833733 OBDC_RSAD_IN_Resp_FD_Data "OnBoard Tester Diagnose Response RSAD_IN";

CM_ SG_ 2550399489 OBDC_RSAD_VL_Req_Data "TP-Kanal für den Onboard Datensammler";

CM_ SG_ 2621702657 OBDC_RSAD_VL_Req_FD_Data "OnBoard Tester Diagnose Request RSAD_VL";

CM_ SG_ 2550530561 OBDC_RSAD_VL_Resp_Data "TP-Kanal für den Onboard Datensammler";

CM_ SG_ 2621833729 OBDC_RSAD_VL_Resp_FD_Data "OnBoard Tester Diagnose Response RSAD_VL";

CM_ SG_ 2550399490 OBDC_RSAD_VR_Req_Data "TP-Kanal für den Onboard Datensammler";

CM_ SG_ 2621702658 OBDC_RSAD_VR_Req_FD_Data "OnBoard Tester Diagnose Request RSAD_VR";

CM_ SG_ 2550530562 OBDC_RSAD_VR_Resp_Data "TP-Kanal für den Onboard Datensammler";

CM_ SG_ 2621833730 OBDC_RSAD_VR_Resp_FD_Data "OnBoard Tester Diagnose Response RSAD_VR";

CM_ SG_ 2549903595 OBDC_SSN_NFC_TGS_Req_Data "Request FID- zu NA- Kommunikation zw. OnboardDiagnoseClient und DK2F Sub-System-Knoten NFC_TGS";

CM_ SG_ 2550034667 OBDC_SSN_NFC_TGS_Resp_Data "Response FID- zu NA- Kommunikation zw. OnboardDiagnoseClient und DK2F Sub-System-Knoten NFC_TGS";

CM_ SG_ 2621440587 OBDC_TSG_BT_Req_FD_Data "OnBoard Tester Diagnose Request TSG_BT";

CM_ SG_ 2621571659 OBDC_TSG_BT_Resp_FD_Data "OnBoard Tester Diagnose Response TSG_BT";

CM_ SG_ 2621440586 OBDC_TSG_FT_Req_FD_Data "OnBoard Tester Diagnose Request TSG_FT";

CM_ SG_ 2621571658 OBDC_TSG_FT_Resp_FD_Data "OnBoard Tester Diagnose Response TSG_FT";

CM_ SG_ 2621440575 OBDC_TSG_HBFS_Req_FD_Data "OnBoard Tester Diagnose Request TSG_HBFS";

CM_ SG_ 2621571647 OBDC_TSG_HBFS_Resp_FD_Data "OnBoard Tester Diagnose Response TSG_HBFS";

CM_ SG_ 2621440574 OBDC_TSG_HFS_Req_FD_Data "OnBoard Tester Diagnose Request TSG_HFS";

CM_ SG_ 2621571646 OBDC_TSG_HFS_Resp_FD_Data "OnBoard Tester Diagnose Response TSG_HFS";

CM_ SG_ 2621440677 OBDC_WLC1_Req_FD_Data "OnBoard Tester Diagnose Request WLC1";

CM_ SG_ 2621571749 OBDC_WLC1_Resp_FD_Data "OnBoard Tester Diagnose Response WLC1";

CM_ SG_ 2564502513 OBDx_allOBD_Req_Data "Generic Scan Tool funktionaler Diagnose Request ALL OBD";

CM_ SG_ 28 OCU_WFS_Anfrage_CRC "OCU_WFS_Anfrage_CRC";
CM_ SG_ 28 OCU_WFS_Anfrage_Status "OCU_WFS_Anfrage_Status";
CM_ SG_ 28 OCU_WFS_Anfrage_Typ "OCU_WFS_Anfrage_Typ";

CM_ SG_ 2589283656 ORU_Status "Verteilung des internen ORU Zustandes";
CM_ SG_ 2589283656 ORU_Warnung "Wenn durch Störungen der Funktion Online Remote Update nicht sichergestellt ist, dass vor Kunde keine Funktionseinschränkungen auftreten, muss der Benutzer des Fahrzeugs entsprechend gewarnt werden.";

CM_ SG_ 2527679741 PAO_OFF_Status "Istwert für LED 'OFF' in Anzeige Passenger Airbag On/Off";
CM_ SG_ 2527679741 PAO_ON_Status "Istwert für LED 'ON' in Anzeige Passenger Airbag On/Off";
CM_ SG_ 2527679741 PAO_Status_01_BZ "4bit Botschaftszähler, wird mit jeder Sendebotschaft inkrementiert";
CM_ SG_ 2527679741 PAO_Status_01_CRC "Für MLB:
Berechnung siehe Lastenheft 'Kommunikationsabsicherung für FlexRay und CAN'
Ab MQB und MLBevo:
Berechnung siehe Lastenheft 'End-to-End Kommunikationsabsicherung'

Endwerte siehe Begleitdokument 'S-PDU Kennungsfolgen'";
CM_ SG_ 2527679741 PAO_Status_Reserve_Byte3 "Zweck: Befüllen der reservierten Bitpositionen mit 0 (wg. LIN-Teilnehmer)";

CM_ SG_ 233 Parken_Aktives_Bedienelement "Wird während der Bedienung mittels Smartphone ein anderes Bedienelement betätigt (Schlüssel, Innenraumtaste) wird die Funktion zunächst unterbrochen. Der Kunde muss den Grund hierfür auf dem Smartphone angezeigt bekommen. ";
CM_ SG_ 233 Parken_Anhaltegrund_ext "Beschreibt den Grund für das Anhalten des Fahrzeugs. Grund kann ein Abbruch oder eine Unterbrechung sein. Dieses Signal erweitert den Wertebereich von Parken_Anhaltegrund.";
CM_ SG_ 233 Parken_BT_Wunsch "Das zFAS teilt der Antenne mit, dass eine Bluetooth Verbindung erwuenscht ist. Der Wert „0“ zeigt an, dass die Antenne in den Sleep Mode gehen kann.";
CM_ SG_ 233 Parken_Fahrtaster_Empfehlung "Hat der Nutzer den Fahrtaster auf dem Smartphone losgelassen und erkennt die Parkfunktion die Möglichkeit in mehr als eine Fahrtrichtung fortzusetzen, bekommt der Nutzer eine Empfehlung der Parkfunktion ausgesprochen. Dieses Signal dient der Markierung/He";
CM_ SG_ 233 Parken_FFB_Status "Dieses Signal teilt den aktuellen Fahrzeugschlüsselstatus mit. ";
CM_ SG_ 233 Parken_Fortschrittszaehler "Zeigt den aktuellen Zustand des Fortschrittsbalken. Der Fortschrittsbalken spiegelt den zeitlichen Verlauf des gesamten Parkvorgangs wider.";
CM_ SG_ 233 Parken_Funktionsstatus "Die Parkfunktion liefert den aktuellen Funktionsstatus. Daraus resultieren die verschiedenen Screens auf dem Smartphone, die Freischaltung bestimmter Eingabeelemente und/oder die Anzeige von Texten etc.";
CM_ SG_ 233 Parken_Hindernis_Bereich "Teilt dem Smartphone mit, in welchem Bereich das nächstgelegene Hindernis im Fahrschlauch erkannt wurde.";
CM_ SG_ 233 Parken_Hindernis_erkannt "Die Parkfunktion teilt dem Smartphone mit, ob ein Hindernis erkannt wurde, auf das gebremst wurde. ";
CM_ SG_ 233 Parken_Manoever "Beschreibt ob ein- oder ausgeparkt werden soll";
CM_ SG_ 233 Parken_Manoever_Aktiv "Beschreibt das anliegende bzw. ausgewählte Manoever.";
CM_ SG_ 233 Parken_Reversieren_moeglich "Die Parkfunktion teilt dem Smartphone mit, ob eine Betätigung des 'Reverse' oder 'Back' Tasters durch den Kunden möglich ist. ";
CM_ SG_ 233 Parken_Richtung "Beschreibt ob die Parklücke vorwärts oder rückwärts beparkt werden soll";
CM_ SG_ 233 Parken_Richtung_Aktiv "Beschreibt die anliegende bzw. ausgewählte Richtung.";
CM_ SG_ 233 Parken_Seite "Beschreibt ob eine Lücke links oder rechts vom Fahrzeug beparkt werden soll. Beim Ausparken kann zusätzlich zu einer Seite, geradeaus ausgeparkt werden. ";
CM_ SG_ 233 Parken_Seite_Aktiv "Beschreibt die anliegende bzw. ausgewählte Seite.";
CM_ SG_ 233 Parken_SM_AktivesRemoteSystem "Gibt an welche der Remote Funktionen Aktiv";
CM_ SG_ 233 Parken_SM_Anhaenger "Teilt der App mit, dass ein gültiger Anhänger erkannt wurde.";
CM_ SG_ 233 Parken_SM_Fahrbereitschaft "Teilt der App die Fahrbereitschaft des Motors mit";
CM_ SG_ 233 Parken_SM_Fahrstufe "Teilt der App mit, dass die korrekteFahrstufe eingelegt ist.";
CM_ SG_ 233 Parken_SM_Schluessel "Teilt der App mit, dass ein gültiger Schlüssel in Reichweite ist.";
CM_ SG_ 233 Parken_SM_Sensor "Teilt der App den Zustand der Rückfahkamera mit";
CM_ SG_ 233 Parken_SM_Stillstand "Teilt der App den sicheren Stillstand mit.";
CM_ SG_ 233 Parken_SM_Tueren "Teilt der App den Zustand der Klappen und Türen mit.";
CM_ SG_ 233 Parken_Szenario "Beschreibt den Grundszenarientyp (Parallel = Längsparken; Perpendicular = Querparken; Garage = Garagenparken; Basic = Basisfunktion vorwärts oder rückwärts ohne Lenkeingriff) ";
CM_ SG_ 233 Parken_Szenario_Aktiv "Beschreibt das anliegende bzw. ausgewählte Szenario.";
CM_ SG_ 233 Parken_Touchdiagnose_Anf "Anforderung einer Touch-Diagnose auf dem mobilen Endgerät.";

CM_ SG_ 2463978635 Parken_Hindernis_erkannt_02 "Die Parkfunktion teilt dem Smartphone mit, ob ein Hindernis erkannt wurde, auf das gebremst wurde.";
CM_ SG_ 2463978635 Parken_Szenario_02 "Beschreibt den Grundszenarientyp (Parallel = Längsparken; Perpendicular = Querparken; Garage = Garagenparken; Basic = Basisfunktion vorwärts oder rückwärts ohne Lenkeingriff; TPA = Trainiertes Parken) 
Die Bezeichnungen in den Signalwertbeschreibungen wu";
CM_ SG_ 2463978635 Parken_Traj_aktueller_Zug "Nummer des aktuellen Zuges";
CM_ SG_ 2463978635 Parken_Traj_Anzahl_Punkte "Anzahl der Punkte auf der Trajektorie";
CM_ SG_ 2463978635 Parken_Traj_Fahrtrichtung "Aktuelle Fahrtrichtung des Fahrzeugs";
CM_ SG_ 2463978635 Parken_Traj_Fzg_Pos_X "relative X-Position Fahrzeug zu Startpunkt Parkvorgang in cm";
CM_ SG_ 2463978635 Parken_Traj_Fzg_Pos_Y "relative Y-Position Fahrzeug zu Startpunkt Parkvorgang in cm";
CM_ SG_ 2463978635 Parken_Traj_Fzg_Winkel "Ausrichtung des Fahrzeugs ausgehend von der Fahrzeug Position als Polarwinkel";
CM_ SG_ 2463978635 Parken_Traj_letzter_Zug "Zur Definition, ob es sich um ein Wendepunkt oder Zielpunkt handelt";
CM_ SG_ 2463978635 Parken_Traj_Trans_ID "Eineindeutige ID für berechnete Trajektorie zum aktuellen Parkvorgang vom ZFAS für das Smartphone (geroutet über die DDA)";

CM_ SG_ 850 Parken_SM_03_MUX "Linearer MUX-Verlauf.

Wird bei jedem MUX übertragen
Punktinfo 1 -9 (Mux 0 -6)";
CM_ SG_ 850 Parken_SM_03_Traj_Trans_ID_00 "wird bei jedem MUX übertragen
Transaktion ID der Trajektorienpunkte
Wird bei jedem MUX übertragen um die Zusammengehörigkeit zwischen Basisinfo und Punktinfos zu gewährleisten";
CM_ SG_ 850 Parken_SM_03_Traj_Trans_ID_01 "wird bei jedem MUX übertragen
Transaktion ID der Trajektorienpunkte
Wird bei jedem MUX übertragen um die Zusammengehörigkeit zwischen Basisinfo und Punktinfos zu gewährleisten";
CM_ SG_ 850 Parken_SM_03_Traj_Trans_ID_02 "wird bei jedem MUX übertragen
Transaktion ID der Trajektorienpunkte
Wird bei jedem MUX übertragen um die Zusammengehörigkeit zwischen Basisinfo und Punktinfos zu gewährleisten";
CM_ SG_ 850 Parken_SM_03_Traj_Trans_ID_03 "wird bei jedem MUX übertragen
Transaktion ID der Trajektorienpunkte
Wird bei jedem MUX übertragen um die Zusammengehörigkeit zwischen Basisinfo und Punktinfos zu gewährleisten";
CM_ SG_ 850 Parken_SM_03_Traj_Trans_ID_04 "wird bei jedem MUX übertragen
Transaktion ID der Trajektorienpunkte
Wird bei jedem MUX übertragen um die Zusammengehörigkeit zwischen Basisinfo und Punktinfos zu gewährleisten";
CM_ SG_ 850 Parken_SM_03_Traj_Trans_ID_05 "wird bei jedem MUX übertragen
Transaktion ID der Trajektorienpunkte
Wird bei jedem MUX übertragen um die Zusammengehörigkeit zwischen Basisinfo und Punktinfos zu gewährleisten";
CM_ SG_ 850 Parken_SM_03_Traj_Trans_ID_06 "wird bei jedem MUX übertragen
Transaktion ID der Trajektorienpunkte
Wird bei jedem MUX übertragen um die Zusammengehörigkeit zwischen Basisinfo und Punktinfos zu gewährleisten";
CM_ SG_ 850 Parken_Traj_P1_Pos_X "MUX = 0 
relative X-Position Punkt zu Startpunkt Parkvorgang in cm";
CM_ SG_ 850 Parken_Traj_P1_Pos_Y "MUX = 0 
relative Y-Position Punkt zu Startpunkt Parkvorgang in cm";
CM_ SG_ 850 Parken_Traj_P1_Tangent "MUX = 0
Beschreibt den Polarwinkel den Tangenten-Vektor des Kreisbogen der am Punkt (X-Position / Y-Position) startet";
CM_ SG_ 850 Parken_Traj_P2_Pos_X "MUX = 0 
relative X-Position Punkt zu Startpunkt Parkvorgang in cm";
CM_ SG_ 850 Parken_Traj_P2_Pos_Y "MUX = 1
relative Y-Position Punkt zu Startpunkt Parkvorgang in cm";
CM_ SG_ 850 Parken_Traj_P2_Tangent "MUX = 1
Beschreibt den Polarwinkel den Tangenten-Vektor des Kreisbogen der am Punkt (X-Position / Y-Position) startet'";
CM_ SG_ 850 Parken_Traj_P3_Pos_X "MUX = 1
relative X-Position Punkt zu Startpunkt Parkvorgang in cm";
CM_ SG_ 850 Parken_Traj_P3_Pos_Y "MUX = 1
relative Y-Position Punkt zu Startpunkt Parkvorgang in cm";
CM_ SG_ 850 Parken_Traj_P3_Tangent "MUX = 2
Beschreibt den Polarwinkel den Tangenten-Vektor des Kreisbogen der am Punkt (X-Position / Y-Position) startet";
CM_ SG_ 850 Parken_Traj_P4_Pos_X "MUX = 2
relative X-Position Punkt zu Startpunkt Parkvorgang in cm";
CM_ SG_ 850 Parken_Traj_P4_Pos_Y "MUX = 2
relative Y-Position Punkt zu Startpunkt Parkvorgang in cm";
CM_ SG_ 850 Parken_Traj_P4_Tangent "MUX = 2
Beschreibt den Polarwinkel den Tangenten-Vektor des Kreisbogen der am Punkt (X-Position / Y-Position) startet";
CM_ SG_ 850 Parken_Traj_P5_Pos_X "MUX = 3
relative X-Position Punkt zu Startpunkt Parkvorgang in cm";
CM_ SG_ 850 Parken_Traj_P5_Pos_Y "MUX = 3
relative Y-Position Punkt zu Startpunkt Parkvorgang in cm";
CM_ SG_ 850 Parken_Traj_P5_Tangent "MUX = 3
Beschreibt den Polarwinkel den Tangenten-Vektor des Kreisbogen der am Punkt (X-Position / Y-Position) startet";
CM_ SG_ 850 Parken_Traj_P6_Pos_X "MUX = 3
relative X-Position Punkt zu Startpunkt Parkvorgang in cm";
CM_ SG_ 850 Parken_Traj_P6_Pos_Y "MUX = 4
relative Y-Position Punkt zu Startpunkt Parkvorgang in cm";
CM_ SG_ 850 Parken_Traj_P6_Tangent "MUX = 4
Beschreibt den Polarwinkel den Tangenten-Vektor des Kreisbogen der am Punkt (X-Position / Y-Position) startet";
CM_ SG_ 850 Parken_Traj_P7_Pos_X "MUX = 4
relative X-Position Punkt zu Startpunkt Parkvorgang in cm";
CM_ SG_ 850 Parken_Traj_P7_Pos_Y "MUX = 4
relative Y-Position Punkt zu Startpunkt Parkvorgang in cm";
CM_ SG_ 850 Parken_Traj_P7_Tangent "MUX = 5
Beschreibt den Polarwinkel den Tangenten-Vektor des Kreisbogen der am Punkt (X-Position / Y-Position) startet";
CM_ SG_ 850 Parken_Traj_P8_Pos_X "MUX = 5
relative X-Position Punkt zu Startpunkt Parkvorgang in cm";
CM_ SG_ 850 Parken_Traj_P8_Pos_Y "MUX = 5
relative Y-Position Punkt zu Startpunkt Parkvorgang in cm";
CM_ SG_ 850 Parken_Traj_P8_Tangent "MUX = 5
Beschreibt den Polarwinkel den Tangenten-Vektor des Kreisbogen der am Punkt (X-Position / Y-Position) startet";
CM_ SG_ 850 Parken_Traj_P9_Pos_X "MUX = 6
relative X-Position Punkt zu Startpunkt Parkvorgang in cm";
CM_ SG_ 850 Parken_Traj_P9_Pos_Y "MUX = 6
relative Y-Position Punkt zu Startpunkt Parkvorgang in cm";
CM_ SG_ 850 Parken_Traj_P9_Tangent "MUX = 6
Beschreibt den Polarwinkel den Tangenten-Vektor des Kreisbogen der am Punkt (X-Position / Y-Position) startet";

CM_ SG_ 2527679498 IAA_Active_User_ID "Signal gibt die IAA Nutzer ID des aktiven IAA Nutzers an.";
CM_ SG_ 2527679498 IAA_Identified_User_ID "Signal gibt die IAA Nutzer ID des vom BCM identifizierten IAA Nutzers an";
CM_ SG_ 2527679498 IAA_PSO_wake_up "Signal zum Wake_up der IAA und PSO Komponenten im Kombi und in der OCU";
CM_ SG_ 2527679498 Perso_Aktiv "Status Personalisierung für den Fahrer aktiviert/ deaktiviert (via HMI)";
CM_ SG_ 2527679498 Perso_Bedienstelle "Signal zeigt an, über welche Bedienstelle die Umschaltung des Benutzerkontos gestartet wurden.";
CM_ SG_ 2527679498 Perso_Fahrernummer "Signal gibt die jewels aktuelle Nummer des Fahrers für die Personalisierung an.
Nicht für AU736 und AU48x.";
CM_ SG_ 2527679498 Perso_Freigabe_Verstellung "Signal zeigt an, ob die Ergonomiefunktionen nach Umschaltung des Benutzerkontos verfahren dürfen.";
CM_ SG_ 2527679498 Perso_Kontonummer "Signal gibt die jewels aktuelle Kontonummer für die Personalisierung an.
Nicht für AU736 und AU48x.";
CM_ SG_ 2527679498 Perso_Schreibschutz "Signal zeigt an, ob der Schreibschutz der Personalisierung aktiv ist.";
CM_ SG_ 2527679498 Perso_Status "Codierstatus der Personalisierung
Nicht für AU736 und AU49x.";
CM_ SG_ 2527679498 Perso_Steuerung "Signal gibt einen Steuerungsbefehl an die Funktionsteilnehmer der Personalisierung.
Nicht für AU736 und AU49x.";
CM_ SG_ 2527679498 Perso_Steuerungsparameter "Signal gibt einen Parameter zum Steuerungsbefehl (Signal Perso_Steuerung) für die Personalisierung an.
Nicht für AU736 und AU49x.";

CM_ SG_ 2463978629 IAA_Active_User_ID_02 "Signal gibt die IAA Nutzer ID des aktiven IAA Nutzers an.";
CM_ SG_ 2463978629 IAA_Identified_User_ID_02 "Signal gibt die IAA Nutzer ID des vom BCM identifizierten IAA Nutzers an";
CM_ SG_ 2463978629 Perso_Aktiv_02 "Status Personalisierung für den Fahrer aktiviert/ deaktiviert (via HMI)";
CM_ SG_ 2463978629 Perso_Bedienstelle_02 "Signal zeigt an, über welche Bedienstelle die Umschaltung des Benutzerkontos gestartet wurden.";
CM_ SG_ 2463978629 Perso_Fahrernummer_02 "Signal gibt die jewels aktuelle Nummer des Fahrers für die Personalisierung an.
Nicht für AU736 und AU48x.";
CM_ SG_ 2463978629 Perso_Freigabe_Verstellung_02 "Signal zeigt an, ob die Ergonomiefunktionen nach Umschaltung des Benutzerkontos verfahren dürfen.";
CM_ SG_ 2463978629 Perso_Kontonummer_02 "Signal gibt die jewels aktuelle Kontonummer für die Personalisierung an.
Nicht für AU736 und AU48x.";
CM_ SG_ 2463978629 Perso_Schreibschutz_02 "Signal zeigt an, ob der Schreibschutz der Personalisierung aktiv ist.";
CM_ SG_ 2463978629 Perso_Status_02 "Codierstatus der Personalisierung
Nicht für AU736 und AU49x.";
CM_ SG_ 2463978629 Perso_Steuerung_02 "Signal gibt einen Steuerungsbefehl an die Funktionsteilnehmer der Personalisierung.
Nicht für AU736 und AU49x.";
CM_ SG_ 2463978629 Perso_Steuerungsparameter_02 "Signal gibt einen Parameter zum Steuerungsbefehl (Signal Perso_Steuerung) für die Personalisierung an.
Nicht für AU736 und AU49x.";
BA_DEF_REL_ BU_SG_REL_  "GenSigTimeoutTime" INT 0 65535;
BA_DEF_ BO_  "DiagRequest" ENUM "No", "Yes";
BA_DEF_ BO_  "DiagResponse" ENUM "No", "Yes";
BA_DEF_ BO_  "DiagState" ENUM "No", "Yes";
BA_DEF_ BO_  "GenMsgChkConstant" HEX 0 4095;
BA_DEF_ BO_  "GenMsgCycleTime" INT 0 65535;
BA_DEF_ BO_  "GenMsgCycleTimeFast" INT 0 65535;
BA_DEF_ BO_  "GenMsgDelayTime" INT 0 100000;
BA_DEF_ BO_  "GenMsgILSupport" ENUM "No", "Yes";
BA_DEF_ BO_  "GenMsgNrOfRepetition" INT 0 100;
BA_DEF_ BO_  "GenMsgPDUConstants" STRING;
BA_DEF_ BO_  "GenMsgSendType" ENUM "Cyclic", "not_used", "not_used", "not_used", "not_used", "not_used", "not_used", "IfActive", "NoMsgSendType";
BA_DEF_ BO_  "GenMsgStartDelayTime" INT 0 100000;
BA_DEF_ BO_  "NmMessage" ENUM "No", "Yes";
BA_DEF_ BO_  "NmhMessage" ENUM "No", "Yes";
BA_DEF_ BO_  "MsgType" ENUM "Application", "NM ", "NMH", "TP2.0", "ISO-TP ", "BAP", "EID", "KS", "XCP_PRE_CONFIGURED", "XCP_RUNTIME_CONFIGURED";
BA_DEF_ BO_  "VAGTP20_API" HEX 0 255;
BA_DEF_ BO_  "VAGTP20_DynConnection" ENUM "No", "Yes";
BA_DEF_ BO_  "VAGTP20_DynSetup" ENUM "No", "Yes";
BA_DEF_ BO_  "VAGTP20_StatConnection" ENUM "No", "Yes";
BA_DEF_ BO_  "CANFD_BRS" ENUM "0", "1";
BA_DEF_ BO_  "VFrameFormat" ENUM "StandardCAN", "ExtendedCAN", "reserved", "reserved", "reserved", "reserved", "reserved", "reserved", "reserved", "reserved", "reserved", "reserved", "reserved", "reserved", "StandardCAN_FD", "ExtendedCAN_FD";
BA_DEF_ SG_  "GenSigActiveRepetitions" INT -2147483648 2147483647;
BA_DEF_ SG_  "GenSigInactiveValue" INT -2147483648 2147483647;
BA_DEF_ SG_  "GenSigSendType" ENUM "Cyclic", "OnWrite", "OnWriteWithRepetition", "OnChange", "OnChangeWithRepetition", "IfActive", "IfActiveWithRepetition", "NoSigSendType", "OnChangeAndIfActive", "OnChangeAndIfActiveWithRepetition";
BA_DEF_ SG_  "GenSigStartValue" INT -2147483648 2147483647;
BA_DEF_ SG_  "NWM-WakeupAllowed" ENUM "No", "Yes";
BA_DEF_ SG_  "GenSigFuncType" ENUM "NoFunction", "MsgCounter", "CRC-8", "XOR", "XOR-2", "DatedBit", "SW-Kl15", "CHK", "Constant", "Protocol", "CRC-8-SAE_J1850", "CRC-32", "DataLength", "DataID", "MsgCounter16", "SOK-Signatur", "Cluster";
BA_DEF_ SG_  "GenSigSwitchedByIgnition" ENUM "No", "Yes";
BA_DEF_ SG_  "Fehlerwert" HEX 0 2147483647;
BA_DEF_ SG_  "GenSigMissingSourceValue" HEX 0 2147483647;
BA_DEF_DEF_REL_  "GenSigTimeoutTime" 0;
BA_DEF_DEF_  "DiagRequest" "No";
BA_DEF_DEF_  "DiagResponse" "No";
BA_DEF_DEF_  "DiagState" "No";
BA_DEF_DEF_  "GenMsgChkConstant" 0;
BA_DEF_DEF_  "GenMsgCycleTime" 0;
BA_DEF_DEF_  "GenMsgCycleTimeFast" 0;
BA_DEF_DEF_  "GenMsgDelayTime" 0;
BA_DEF_DEF_  "GenMsgILSupport" "No";
BA_DEF_DEF_  "GenMsgNrOfRepetition" 0;
BA_DEF_DEF_  "GenMsgPDUConstants" "";
BA_DEF_DEF_  "GenMsgSendType" "NoMsgSendType";
BA_DEF_DEF_  "GenMsgStartDelayTime" 0;
BA_DEF_DEF_  "NmMessage" "No";
BA_DEF_DEF_  "NmhMessage" "No";
BA_DEF_DEF_  "MsgType" "Application";
BA_DEF_DEF_  "VAGTP20_API" 0;
BA_DEF_DEF_  "VAGTP20_DynConnection" "No";
BA_DEF_DEF_  "VAGTP20_DynSetup" "No";
BA_DEF_DEF_  "VAGTP20_StatConnection" "No";
BA_DEF_DEF_  "CANFD_BRS" "1";
BA_DEF_DEF_  "VFrameFormat" "StandardCAN";
BA_DEF_DEF_  "GenSigActiveRepetitions" 0;
BA_DEF_DEF_  "GenSigInactiveValue" 0;
BA_DEF_DEF_  "GenSigSendType" "NoSigSendType";
BA_DEF_DEF_  "GenSigStartValue" 0;
BA_DEF_DEF_  "NWM-WakeupAllowed" "No";
BA_DEF_DEF_  "GenSigFuncType" "NoFunction";
BA_DEF_DEF_  "GenSigSwitchedByIgnition" "Yes";
BA_DEF_DEF_  "Fehlerwert" 0;
BA_DEF_DEF_  "GenSigMissingSourceValue" 0;
BA_ "GenMsgCycleTime" BO_ 332 100;
BA_ "GenMsgDelayTime" BO_ 332 10;
BA_ "GenMsgILSupport" BO_ 332 1;
BA_ "GenMsgPDUConstants" BO_ 332 "0x16,0x35,0x59,0x15,0x9a,0x2a,0x97,0xb8,0x0e,0x4e,0x30,0xcc,0xb3,0x07,0x01,0xad";
BA_ "GenMsgSendType" BO_ 332 0;
BA_ "CANFD_BRS" BO_ 332 0;
BA_ "VFrameFormat" BO_ 332 14;
BA_ "GenMsgChkConstant" BO_ 1601 71;
BA_ "GenMsgCycleTime" BO_ 1601 1000;
BA_ "GenMsgILSupport" BO_ 1601 1;
BA_ "GenMsgPDUConstants" BO_ 1601 "0x47,0x47,0x47,0x47,0x47,0x47,0x47,0x47,0x47,0x47,0x47,0x47,0x47,0x47,0x47,0x47";
BA_ "GenMsgSendType" BO_ 1601 0;
BA_ "CANFD_BRS" BO_ 1601 0;
BA_ "VFrameFormat" BO_ 1601 14;
BA_ "GenMsgCycleTime" BO_ 391 100;
BA_ "GenMsgDelayTime" BO_ 391 40;
BA_ "GenMsgILSupport" BO_ 391 1;
BA_ "GenMsgPDUConstants" BO_ 391 "0x7f,0xed,0x17,0xc2,0x7c,0xeb,0x44,0x21,0x01,0xfa,0xdb,0x15,0x4a,0x6b,0x23,0x05";
BA_ "GenMsgSendType" BO_ 391 0;
BA_ "CANFD_BRS" BO_ 391 0;
BA_ "VFrameFormat" BO_ 391 14;
BA_ "GenMsgILSupport" BO_ 16 1;
BA_ "CANFD_BRS" BO_ 16 0;
BA_ "VFrameFormat" BO_ 16 14;
BA_ "GenMsgILSupport" BO_ 22 1;
BA_ "CANFD_BRS" BO_ 22 0;
BA_ "VFrameFormat" BO_ 22 14;
BA_ "GenMsgILSupport" BO_ 24 1;
BA_ "CANFD_BRS" BO_ 24 0;
BA_ "VFrameFormat" BO_ 24 14;
BA_ "GenMsgCycleTime" BO_ 2527679770 200;
BA_ "GenMsgILSupport" BO_ 2527679770 1;
BA_ "GenMsgSendType" BO_ 2527679770 0;
BA_ "CANFD_BRS" BO_ 2527679770 0;
BA_ "VFrameFormat" BO_ 2527679770 15;
BA_ "GenMsgCycleTime" BO_ 2527679645 200;
BA_ "GenMsgILSupport" BO_ 2527679645 1;
BA_ "GenMsgSendType" BO_ 2527679645 0;
BA_ "CANFD_BRS" BO_ 2527679645 0;
BA_ "VFrameFormat" BO_ 2527679645 15;
BA_ "GenMsgCycleTime" BO_ 2527679646 200;
BA_ "GenMsgILSupport" BO_ 2527679646 1;
BA_ "GenMsgSendType" BO_ 2527679646 0;
BA_ "CANFD_BRS" BO_ 2527679646 0;
BA_ "VFrameFormat" BO_ 2527679646 15;
BA_ "GenMsgCycleTime" BO_ 2600468494 200;
BA_ "GenMsgCycleTimeFast" BO_ 2600468494 10;
BA_ "NmhMessage" BO_ 2600468494 1;
BA_ "MsgType" BO_ 2600468494 2;
BA_ "CANFD_BRS" BO_ 2600468494 0;
BA_ "VFrameFormat" BO_ 2600468494 1;
BA_ "GenMsgCycleTime" BO_ 2600468496 200;
BA_ "GenMsgCycleTimeFast" BO_ 2600468496 10;
BA_ "NmhMessage" BO_ 2600468496 1;
BA_ "MsgType" BO_ 2600468496 2;
BA_ "CANFD_BRS" BO_ 2600468496 0;
BA_ "VFrameFormat" BO_ 2600468496 1;
BA_ "GenMsgCycleTime" BO_ 2600468555 200;
BA_ "GenMsgCycleTimeFast" BO_ 2600468555 10;
BA_ "NmhMessage" BO_ 2600468555 1;
BA_ "MsgType" BO_ 2600468555 2;
BA_ "CANFD_BRS" BO_ 2600468555 0;
BA_ "VFrameFormat" BO_ 2600468555 1;
BA_ "GenMsgCycleTime" BO_ 2600468554 200;
BA_ "GenMsgCycleTimeFast" BO_ 2600468554 10;
BA_ "NmhMessage" BO_ 2600468554 1;
BA_ "MsgType" BO_ 2600468554 2;
BA_ "CANFD_BRS" BO_ 2600468554 0;
BA_ "VFrameFormat" BO_ 2600468554 1;
BA_ "GenMsgCycleTime" BO_ 2600468543 200;
BA_ "GenMsgCycleTimeFast" BO_ 2600468543 10;
BA_ "NmhMessage" BO_ 2600468543 1;
BA_ "MsgType" BO_ 2600468543 2;
BA_ "CANFD_BRS" BO_ 2600468543 0;
BA_ "VFrameFormat" BO_ 2600468543 1;
BA_ "GenMsgCycleTime" BO_ 2600468542 200;
BA_ "GenMsgCycleTimeFast" BO_ 2600468542 10;
BA_ "NmhMessage" BO_ 2600468542 1;
BA_ "MsgType" BO_ 2600468542 2;
BA_ "CANFD_BRS" BO_ 2600468542 0;
BA_ "VFrameFormat" BO_ 2600468542 1;
BA_ "GenMsgCycleTime" BO_ 2600468645 200;
BA_ "GenMsgCycleTimeFast" BO_ 2600468645 10;
BA_ "NmhMessage" BO_ 2600468645 1;
BA_ "MsgType" BO_ 2600468645 2;
BA_ "CANFD_BRS" BO_ 2600468645 0;
BA_ "VFrameFormat" BO_ 2600468645 1;
BA_ "DiagRequest" BO_ 2621440526 1;
BA_ "MsgType" BO_ 2621440526 4;
BA_ "CANFD_BRS" BO_ 2621440526 0;
BA_ "VFrameFormat" BO_ 2621440526 15;
BA_ "DiagResponse" BO_ 2621571598 1;
BA_ "MsgType" BO_ 2621571598 4;
BA_ "CANFD_BRS" BO_ 2621571598 0;
BA_ "VFrameFormat" BO_ 2621571598 15;
BA_ "DiagRequest" BO_ 2549875386 1;
BA_ "MsgType" BO_ 2549875386 4;
BA_ "CANFD_BRS" BO_ 2549875386 0;
BA_ "VFrameFormat" BO_ 2549875386 15;
BA_ "DiagResponse" BO_ 2550006458 1;
BA_ "MsgType" BO_ 2550006458 4;
BA_ "CANFD_BRS" BO_ 2550006458 0;
BA_ "VFrameFormat" BO_ 2550006458 15;
BA_ "DiagState" BO_ 2549940736 1;
BA_ "MsgType" BO_ 2549940736 4;
BA_ "CANFD_BRS" BO_ 2549940736 0;
BA_ "VFrameFormat" BO_ 2549940736 15;
BA_ "DiagState" BO_ 2621506048 1;
BA_ "MsgType" BO_ 2621506048 4;
BA_ "CANFD_BRS" BO_ 2621506048 0;
BA_ "VFrameFormat" BO_ 2621506048 15;
BA_ "DiagRequest" BO_ 2549875250 1;
BA_ "MsgType" BO_ 2549875250 4;
BA_ "CANFD_BRS" BO_ 2549875250 0;
BA_ "VFrameFormat" BO_ 2549875250 15;
BA_ "DiagResponse" BO_ 2550006322 1;
BA_ "MsgType" BO_ 2550006322 4;
BA_ "CANFD_BRS" BO_ 2550006322 0;
BA_ "VFrameFormat" BO_ 2550006322 15;
BA_ "DiagRequest" BO_ 2549875350 1;
BA_ "MsgType" BO_ 2549875350 4;
BA_ "CANFD_BRS" BO_ 2549875350 0;
BA_ "VFrameFormat" BO_ 2549875350 15;
BA_ "DiagResponse" BO_ 2550006422 1;
BA_ "MsgType" BO_ 2550006422 4;
BA_ "CANFD_BRS" BO_ 2550006422 0;
BA_ "VFrameFormat" BO_ 2550006422 15;
BA_ "DiagRequest" BO_ 2549875351 1;
BA_ "MsgType" BO_ 2549875351 4;
BA_ "CANFD_BRS" BO_ 2549875351 0;
BA_ "VFrameFormat" BO_ 2549875351 15;
BA_ "DiagResponse" BO_ 2550006423 1;
BA_ "MsgType" BO_ 2550006423 4;
BA_ "CANFD_BRS" BO_ 2550006423 0;
BA_ "VFrameFormat" BO_ 2550006423 15;
BA_ "DiagRequest" BO_ 2550399491 1;
BA_ "MsgType" BO_ 2550399491 4;
BA_ "CANFD_BRS" BO_ 2550399491 0;
BA_ "VFrameFormat" BO_ 2550399491 15;
BA_ "DiagRequest" BO_ 2621702659 1;
BA_ "MsgType" BO_ 2621702659 4;
BA_ "CANFD_BRS" BO_ 2621702659 0;
BA_ "VFrameFormat" BO_ 2621702659 15;
BA_ "DiagResponse" BO_ 2550530563 1;
BA_ "MsgType" BO_ 2550530563 4;
BA_ "CANFD_BRS" BO_ 2550530563 0;
BA_ "VFrameFormat" BO_ 2550530563 15;
BA_ "DiagResponse" BO_ 2621833731 1;
BA_ "MsgType" BO_ 2621833731 4;
BA_ "CANFD_BRS" BO_ 2621833731 0;
BA_ "VFrameFormat" BO_ 2621833731 15;
BA_ "DiagRequest" BO_ 2550399492 1;
BA_ "MsgType" BO_ 2550399492 4;
BA_ "CANFD_BRS" BO_ 2550399492 0;
BA_ "VFrameFormat" BO_ 2550399492 15;
BA_ "DiagRequest" BO_ 2621702660 1;
BA_ "MsgType" BO_ 2621702660 4;
BA_ "CANFD_BRS" BO_ 2621702660 0;
BA_ "VFrameFormat" BO_ 2621702660 15;
BA_ "DiagResponse" BO_ 2550530564 1;
BA_ "MsgType" BO_ 2550530564 4;
BA_ "CANFD_BRS" BO_ 2550530564 0;
BA_ "VFrameFormat" BO_ 2550530564 15;
BA_ "DiagResponse" BO_ 2621833732 1;
BA_ "MsgType" BO_ 2621833732 4;
BA_ "CANFD_BRS" BO_ 2621833732 0;
BA_ "VFrameFormat" BO_ 2621833732 15;
BA_ "DiagRequest" BO_ 2621702709 1;
BA_ "MsgType" BO_ 2621702709 4;
BA_ "CANFD_BRS" BO_ 2621702709 0;
BA_ "VFrameFormat" BO_ 2621702709 15;
BA_ "DiagResponse" BO_ 2621833781 1;
BA_ "MsgType" BO_ 2621833781 4;
BA_ "CANFD_BRS" BO_ 2621833781 0;
BA_ "VFrameFormat" BO_ 2621833781 15;
BA_ "DiagRequest" BO_ 2621702710 1;
BA_ "MsgType" BO_ 2621702710 4;
BA_ "CANFD_BRS" BO_ 2621702710 0;
BA_ "VFrameFormat" BO_ 2621702710 15;
BA_ "DiagResponse" BO_ 2621833782 1;
BA_ "MsgType" BO_ 2621833782 4;
BA_ "CANFD_BRS" BO_ 2621833782 0;
BA_ "VFrameFormat" BO_ 2621833782 15;
BA_ "DiagRequest" BO_ 2621702711 1;
BA_ "MsgType" BO_ 2621702711 4;
BA_ "CANFD_BRS" BO_ 2621702711 0;
BA_ "VFrameFormat" BO_ 2621702711 15;
BA_ "DiagResponse" BO_ 2621833783 1;
BA_ "MsgType" BO_ 2621833783 4;
BA_ "CANFD_BRS" BO_ 2621833783 0;
BA_ "VFrameFormat" BO_ 2621833783 15;
BA_ "DiagRequest" BO_ 2550399493 1;
BA_ "MsgType" BO_ 2550399493 4;
BA_ "CANFD_BRS" BO_ 2550399493 0;
BA_ "VFrameFormat" BO_ 2550399493 15;
BA_ "DiagRequest" BO_ 2621702661 1;
BA_ "MsgType" BO_ 2621702661 4;
BA_ "CANFD_BRS" BO_ 2621702661 0;
BA_ "VFrameFormat" BO_ 2621702661 15;
BA_ "DiagResponse" BO_ 2550530565 1;
BA_ "MsgType" BO_ 2550530565 4;
BA_ "CANFD_BRS" BO_ 2550530565 0;
BA_ "VFrameFormat" BO_ 2550530565 15;
BA_ "DiagResponse" BO_ 2621833733 1;
BA_ "MsgType" BO_ 2621833733 4;
BA_ "CANFD_BRS" BO_ 2621833733 0;
BA_ "VFrameFormat" BO_ 2621833733 15;
BA_ "DiagRequest" BO_ 2550399489 1;
BA_ "MsgType" BO_ 2550399489 4;
BA_ "CANFD_BRS" BO_ 2550399489 0;
BA_ "VFrameFormat" BO_ 2550399489 15;
BA_ "DiagRequest" BO_ 2621702657 1;
BA_ "MsgType" BO_ 2621702657 4;
BA_ "CANFD_BRS" BO_ 2621702657 0;
BA_ "VFrameFormat" BO_ 2621702657 15;
BA_ "DiagResponse" BO_ 2550530561 1;
BA_ "MsgType" BO_ 2550530561 4;
BA_ "CANFD_BRS" BO_ 2550530561 0;
BA_ "VFrameFormat" BO_ 2550530561 15;
BA_ "DiagResponse" BO_ 2621833729 1;
BA_ "MsgType" BO_ 2621833729 4;
BA_ "CANFD_BRS" BO_ 2621833729 0;
BA_ "VFrameFormat" BO_ 2621833729 15;
BA_ "DiagRequest" BO_ 2550399490 1;
BA_ "MsgType" BO_ 2550399490 4;
BA_ "CANFD_BRS" BO_ 2550399490 0;
BA_ "VFrameFormat" BO_ 2550399490 15;
BA_ "DiagRequest" BO_ 2621702658 1;
BA_ "MsgType" BO_ 2621702658 4;
BA_ "CANFD_BRS" BO_ 2621702658 0;
BA_ "VFrameFormat" BO_ 2621702658 15;
BA_ "DiagResponse" BO_ 2550530562 1;
BA_ "MsgType" BO_ 2550530562 4;
BA_ "CANFD_BRS" BO_ 2550530562 0;
BA_ "VFrameFormat" BO_ 2550530562 15;
BA_ "DiagResponse" BO_ 2621833730 1;
BA_ "MsgType" BO_ 2621833730 4;
BA_ "CANFD_BRS" BO_ 2621833730 0;
BA_ "VFrameFormat" BO_ 2621833730 15;
BA_ "DiagRequest" BO_ 2549903595 1;
BA_ "MsgType" BO_ 2549903595 4;
BA_ "CANFD_BRS" BO_ 2549903595 0;
BA_ "VFrameFormat" BO_ 2549903595 15;
BA_ "DiagResponse" BO_ 2550034667 1;
BA_ "MsgType" BO_ 2550034667 4;
BA_ "CANFD_BRS" BO_ 2550034667 0;
BA_ "VFrameFormat" BO_ 2550034667 15;
BA_ "DiagRequest" BO_ 2621440587 1;
BA_ "MsgType" BO_ 2621440587 4;
BA_ "CANFD_BRS" BO_ 2621440587 0;
BA_ "VFrameFormat" BO_ 2621440587 15;
BA_ "DiagResponse" BO_ 2621571659 1;
BA_ "MsgType" BO_ 2621571659 4;
BA_ "CANFD_BRS" BO_ 2621571659 0;
BA_ "VFrameFormat" BO_ 2621571659 15;
BA_ "DiagRequest" BO_ 2621440586 1;
BA_ "MsgType" BO_ 2621440586 4;
BA_ "CANFD_BRS" BO_ 2621440586 0;
BA_ "VFrameFormat" BO_ 2621440586 15;
BA_ "DiagResponse" BO_ 2621571658 1;
BA_ "MsgType" BO_ 2621571658 4;
BA_ "CANFD_BRS" BO_ 2621571658 0;
BA_ "VFrameFormat" BO_ 2621571658 15;
BA_ "DiagRequest" BO_ 2621440575 1;
BA_ "MsgType" BO_ 2621440575 4;
BA_ "CANFD_BRS" BO_ 2621440575 0;
BA_ "VFrameFormat" BO_ 2621440575 15;
BA_ "DiagResponse" BO_ 2621571647 1;
BA_ "MsgType" BO_ 2621571647 4;
BA_ "CANFD_BRS" BO_ 2621571647 0;
BA_ "VFrameFormat" BO_ 2621571647 15;
BA_ "DiagRequest" BO_ 2621440574 1;
BA_ "MsgType" BO_ 2621440574 4;
BA_ "CANFD_BRS" BO_ 2621440574 0;
BA_ "VFrameFormat" BO_ 2621440574 15;
BA_ "DiagResponse" BO_ 2621571646 1;
BA_ "MsgType" BO_ 2621571646 4;
BA_ "CANFD_BRS" BO_ 2621571646 0;
BA_ "VFrameFormat" BO_ 2621571646 15;
BA_ "DiagRequest" BO_ 2621440677 1;
BA_ "MsgType" BO_ 2621440677 4;
BA_ "CANFD_BRS" BO_ 2621440677 0;
BA_ "VFrameFormat" BO_ 2621440677 15;
BA_ "DiagResponse" BO_ 2621571749 1;
BA_ "MsgType" BO_ 2621571749 4;
BA_ "CANFD_BRS" BO_ 2621571749 0;
BA_ "VFrameFormat" BO_ 2621571749 15;
BA_ "DiagState" BO_ 2564502513 1;
BA_ "MsgType" BO_ 2564502513 4;
BA_ "CANFD_BRS" BO_ 2564502513 0;
BA_ "VFrameFormat" BO_ 2564502513 15;
BA_ "CANFD_BRS" BO_ 28 0;
BA_ "VFrameFormat" BO_ 28 14;
BA_ "GenMsgCycleTime" BO_ 2589283656 500;
BA_ "GenMsgDelayTime" BO_ 2589283656 100;
BA_ "GenMsgILSupport" BO_ 2589283656 1;
BA_ "GenMsgSendType" BO_ 2589283656 0;
BA_ "CANFD_BRS" BO_ 2589283656 0;
BA_ "VFrameFormat" BO_ 2589283656 15;
BA_ "GenMsgCycleTime" BO_ 2527679741 240;
BA_ "GenMsgILSupport" BO_ 2527679741 1;
BA_ "GenMsgPDUConstants" BO_ 2527679741 "0x9d,0xe8,0x36,0xa1,0xca,0x3b,0x1d,0x33,0xe0,0xd5,0xbb,0x5f,0xae,0x3c,0x31,0x9f";
BA_ "GenMsgSendType" BO_ 2527679741 0;
BA_ "CANFD_BRS" BO_ 2527679741 0;
BA_ "VFrameFormat" BO_ 2527679741 15;
BA_ "GenMsgCycleTime" BO_ 233 1000;
BA_ "GenMsgDelayTime" BO_ 233 20;
BA_ "GenMsgILSupport" BO_ 233 1;
BA_ "GenMsgSendType" BO_ 233 0;
BA_ "CANFD_BRS" BO_ 233 0;
BA_ "VFrameFormat" BO_ 233 14;
BA_ "GenMsgCycleTime" BO_ 2463978635 320;
BA_ "GenMsgDelayTime" BO_ 2463978635 20;
BA_ "GenMsgILSupport" BO_ 2463978635 1;
BA_ "GenMsgSendType" BO_ 2463978635 0;
BA_ "CANFD_BRS" BO_ 2463978635 0;
BA_ "VFrameFormat" BO_ 2463978635 15;
BA_ "GenMsgCycleTime" BO_ 850 200;
BA_ "GenMsgILSupport" BO_ 850 1;
BA_ "GenMsgSendType" BO_ 850 0;
BA_ "CANFD_BRS" BO_ 850 0;
BA_ "VFrameFormat" BO_ 850 14;
BA_ "GenMsgCycleTime" BO_ 2527679498 1000;
BA_ "GenMsgCycleTimeFast" BO_ 2527679498 200;
BA_ "GenMsgDelayTime" BO_ 2527679498 50;
BA_ "GenMsgILSupport" BO_ 2527679498 1;
BA_ "GenMsgNrOfRepetition" BO_ 2527679498 3;
BA_ "GenMsgSendType" BO_ 2527679498 0;
BA_ "CANFD_BRS" BO_ 2527679498 0;
BA_ "VFrameFormat" BO_ 2527679498 15;
BA_ "GenMsgCycleTime" BO_ 2463978629 1000;
BA_ "GenMsgCycleTimeFast" BO_ 2463978629 200;
BA_ "GenMsgDelayTime" BO_ 2463978629 50;
BA_ "GenMsgILSupport" BO_ 2463978629 1;
BA_ "GenMsgNrOfRepetition" BO_ 2463978629 3;
BA_ "GenMsgSendType" BO_ 2463978629 0;
BA_ "CANFD_BRS" BO_ 2463978629 0;
BA_ "VFrameFormat" BO_ 2463978629 15;
BA_ "GenSigSendType" SG_ 332 CE_FlgLnchCtlPreCnd 0;
BA_ "GenSigSwitchedByIgnition" SG_ 332 CE_FlgLnchCtlPreCnd 0;
BA_ "GenSigSendType" SG_ 332 FoD_DTC_TSK_ACC 0;
BA_ "GenSigSwitchedByIgnition" SG_ 332 FoD_DTC_TSK_ACC 0;
BA_ "GenSigSendType" SG_ 332 FoD_DTC_TSK_GRA 0;
BA_ "GenSigSwitchedByIgnition" SG_ 332 FoD_DTC_TSK_GRA 0;
BA_ "GenSigSendType" SG_ 332 ISA_Regelung_aktiv 3;
BA_ "GenSigSwitchedByIgnition" SG_ 332 ISA_Regelung_aktiv 0;
BA_ "GenSigSendType" SG_ 332 ISA_Status 3;
BA_ "GenSigStartValue" SG_ 332 ISA_Status 1;
BA_ "GenSigSwitchedByIgnition" SG_ 332 ISA_Status 0;
BA_ "GenSigSendType" SG_ 332 ISA_Tempolimitwarnung 3;
BA_ "GenSigSwitchedByIgnition" SG_ 332 ISA_Tempolimitwarnung 0;
BA_ "GenSigSendType" SG_ 332 MO_Anforderung_HMS 3;
BA_ "GenSigSwitchedByIgnition" SG_ 332 MO_Anforderung_HMS 0;
BA_ "GenSigSendType" SG_ 332 MO_EBoost_verf_praed 0;
BA_ "GenSigSwitchedByIgnition" SG_ 332 MO_EBoost_verf_praed 0;
BA_ "GenSigSendType" SG_ 332 MO_eLaunch_verf 0;
BA_ "GenSigSwitchedByIgnition" SG_ 332 MO_eLaunch_verf 0;
BA_ "GenSigSendType" SG_ 332 MO_EMG_Max_Leistung 0;
BA_ "GenSigStartValue" SG_ 332 MO_EMG_Max_Leistung 2046;
BA_ "GenSigSwitchedByIgnition" SG_ 332 MO_EMG_Max_Leistung 0;
BA_ "Fehlerwert" SG_ 332 MO_EMG_Max_Leistung 2047;
BA_ "GenSigSendType" SG_ 332 MO_EMG_Min_Leistung 0;
BA_ "GenSigStartValue" SG_ 332 MO_EMG_Min_Leistung 2046;
BA_ "GenSigSwitchedByIgnition" SG_ 332 MO_EMG_Min_Leistung 0;
BA_ "Fehlerwert" SG_ 332 MO_EMG_Min_Leistung 2047;
BA_ "GenSigSendType" SG_ 332 MO_Fahrbereitschaft 3;
BA_ "GenSigSwitchedByIgnition" SG_ 332 MO_Fahrbereitschaft 0;
BA_ "GenSigSendType" SG_ 332 MO_Freilauf_Info 3;
BA_ "GenSigSwitchedByIgnition" SG_ 332 MO_Freilauf_Info 0;
BA_ "GenSigSendType" SG_ 332 MO_Freilauf_Status 3;
BA_ "GenSigSwitchedByIgnition" SG_ 332 MO_Freilauf_Status 0;
BA_ "Fehlerwert" SG_ 332 MO_Freilauf_Status 7;
BA_ "GenSigSendType" SG_ 332 MO_Heckspoiler_Anf 0;
BA_ "GenSigSwitchedByIgnition" SG_ 332 MO_Heckspoiler_Anf 0;
BA_ "GenSigSendType" SG_ 332 MO_Klima_Regelmodus 0;
BA_ "GenSigSwitchedByIgnition" SG_ 332 MO_Klima_Regelmodus 0;
BA_ "GenSigSendType" SG_ 332 MO_Krit_Heckobjekt 0;
BA_ "GenSigSwitchedByIgnition" SG_ 332 MO_Krit_Heckobjekt 0;
BA_ "Fehlerwert" SG_ 332 MO_Krit_Heckobjekt 7;
BA_ "GenSigSendType" SG_ 332 MO_Kuppl_betaetigt 3;
BA_ "GenSigSwitchedByIgnition" SG_ 332 MO_Kuppl_betaetigt 0;
BA_ "GenSigSendType" SG_ 332 MO_LaunchControl 0;
BA_ "GenSigSwitchedByIgnition" SG_ 332 MO_LaunchControl 0;
BA_ "GenSigSendType" SG_ 332 MO_MVEM_MaxLeistung_MVVerbrauch 0;
BA_ "GenSigStartValue" SG_ 332 MO_MVEM_MaxLeistung_MVVerbrauch 1022;
BA_ "GenSigSwitchedByIgnition" SG_ 332 MO_MVEM_MaxLeistung_MVVerbrauch 0;
BA_ "Fehlerwert" SG_ 332 MO_MVEM_MaxLeistung_MVVerbrauch 1023;
BA_ "GenSigSendType" SG_ 332 MO_MVEM_MinLeistung_MVVerbrauch 0;
BA_ "GenSigStartValue" SG_ 332 MO_MVEM_MinLeistung_MVVerbrauch 1022;
BA_ "GenSigSwitchedByIgnition" SG_ 332 MO_MVEM_MinLeistung_MVVerbrauch 0;
BA_ "Fehlerwert" SG_ 332 MO_MVEM_MinLeistung_MVVerbrauch 1023;
BA_ "GenSigSendType" SG_ 332 MO_NGS_Gangpos 3;
BA_ "GenSigSwitchedByIgnition" SG_ 332 MO_NGS_Gangpos 0;
BA_ "Fehlerwert" SG_ 332 MO_NGS_Gangpos 7;
BA_ "GenSigSendType" SG_ 332 MO_Positionierung_aktiv 0;
BA_ "GenSigSwitchedByIgnition" SG_ 332 MO_Positionierung_aktiv 0;
BA_ "GenSigSendType" SG_ 332 MO_QBit_Aussen_Temp 0;
BA_ "GenSigStartValue" SG_ 332 MO_QBit_Aussen_Temp 1;
BA_ "GenSigSwitchedByIgnition" SG_ 332 MO_QBit_Aussen_Temp 0;
BA_ "GenSigSendType" SG_ 332 MO_QBit_Kuppl_betaetigt 3;
BA_ "GenSigSwitchedByIgnition" SG_ 332 MO_QBit_Kuppl_betaetigt 0;
BA_ "GenSigSendType" SG_ 332 MO_Red_El_Fahrleistung 0;
BA_ "GenSigSwitchedByIgnition" SG_ 332 MO_Red_El_Fahrleistung 0;
BA_ "GenSigSendType" SG_ 332 MO_Servicemodus 0;
BA_ "GenSigSwitchedByIgnition" SG_ 332 MO_Servicemodus 0;
BA_ "GenSigSendType" SG_ 332 MO_Startwunsch 3;
BA_ "GenSigSwitchedByIgnition" SG_ 332 MO_Startwunsch 0;
BA_ "GenSigSendType" SG_ 332 MO_UBE_Hybrid_Reserve 0;
BA_ "GenSigStartValue" SG_ 332 MO_UBE_Hybrid_Reserve 1023;
BA_ "GenSigSwitchedByIgnition" SG_ 332 MO_UBE_Hybrid_Reserve 0;
BA_ "GenSigSendType" SG_ 332 MO_UBE_Reserve 0;
BA_ "GenSigStartValue" SG_ 332 MO_UBE_Reserve 1023;
BA_ "GenSigSwitchedByIgnition" SG_ 332 MO_UBE_Reserve 0;
BA_ "GenSigSendType" SG_ 332 MO_Veto_Launchcontrol 0;
BA_ "GenSigSwitchedByIgnition" SG_ 332 MO_Veto_Launchcontrol 0;
BA_ "GenSigSendType" SG_ 332 Motor_54_BZ 0;
BA_ "GenSigFuncType" SG_ 332 Motor_54_BZ 1;
BA_ "GenSigSwitchedByIgnition" SG_ 332 Motor_54_BZ 0;
BA_ "GenSigSendType" SG_ 332 Motor_54_CRC 0;
BA_ "GenSigFuncType" SG_ 332 Motor_54_CRC 2;
BA_ "GenSigSwitchedByIgnition" SG_ 332 Motor_54_CRC 0;
BA_ "GenSigSendType" SG_ 332 OBD_Abs_Load_Val 0;
BA_ "GenSigStartValue" SG_ 332 OBD_Abs_Load_Val 65535;
BA_ "GenSigSwitchedByIgnition" SG_ 332 OBD_Abs_Load_Val 0;
BA_ "GenSigSendType" SG_ 332 OBD_Abs_Pedal_Pos 0;
BA_ "GenSigStartValue" SG_ 332 OBD_Abs_Pedal_Pos 255;
BA_ "GenSigSwitchedByIgnition" SG_ 332 OBD_Abs_Pedal_Pos 0;
BA_ "GenSigSendType" SG_ 332 OBD_Abs_Throttle_Pos 0;
BA_ "GenSigStartValue" SG_ 332 OBD_Abs_Throttle_Pos 255;
BA_ "GenSigSwitchedByIgnition" SG_ 332 OBD_Abs_Throttle_Pos 0;
BA_ "GenSigSendType" SG_ 332 OBD_Aussen_Temp_gef 0;
BA_ "GenSigStartValue" SG_ 332 OBD_Aussen_Temp_gef 254;
BA_ "GenSigSwitchedByIgnition" SG_ 332 OBD_Aussen_Temp_gef 0;
BA_ "Fehlerwert" SG_ 332 OBD_Aussen_Temp_gef 255;
BA_ "GenSigSendType" SG_ 332 OBD_Calc_Load_Val 0;
BA_ "GenSigStartValue" SG_ 332 OBD_Calc_Load_Val 255;
BA_ "GenSigSwitchedByIgnition" SG_ 332 OBD_Calc_Load_Val 0;
BA_ "GenSigSendType" SG_ 332 OBD_ClearMem_Inhibit 0;
BA_ "GenSigSwitchedByIgnition" SG_ 332 OBD_ClearMem_Inhibit 0;
BA_ "GenSigSendType" SG_ 332 OBD_Driving_Cycle 0;
BA_ "GenSigSwitchedByIgnition" SG_ 332 OBD_Driving_Cycle 0;
BA_ "GenSigSendType" SG_ 332 OBD_Eng_Cool_Temp 0;
BA_ "GenSigStartValue" SG_ 332 OBD_Eng_Cool_Temp 255;
BA_ "GenSigSwitchedByIgnition" SG_ 332 OBD_Eng_Cool_Temp 0;
BA_ "GenSigSendType" SG_ 332 OBD_Kaltstart_Denominator 0;
BA_ "GenSigSwitchedByIgnition" SG_ 332 OBD_Kaltstart_Denominator 0;
BA_ "GenSigSendType" SG_ 332 OBD_Minimum_Trip 0;
BA_ "GenSigSwitchedByIgnition" SG_ 332 OBD_Minimum_Trip 0;
BA_ "GenSigSendType" SG_ 332 OBD_Normed_Trip 0;
BA_ "GenSigSwitchedByIgnition" SG_ 332 OBD_Normed_Trip 0;
BA_ "GenSigSendType" SG_ 332 OBD_Sperrung_IUMPR 0;
BA_ "GenSigSwitchedByIgnition" SG_ 332 OBD_Sperrung_IUMPR 0;
BA_ "GenSigSendType" SG_ 332 OBD_Sperrung_Kaltstart_Denom 0;
BA_ "GenSigSwitchedByIgnition" SG_ 332 OBD_Sperrung_Kaltstart_Denom 0;
BA_ "GenSigSendType" SG_ 332 OBD_Warm_Up_Cycle 0;
BA_ "GenSigSwitchedByIgnition" SG_ 332 OBD_Warm_Up_Cycle 0;
BA_ "GenSigSendType" SG_ 332 OBDProtocol_req 0;
BA_ "GenSigSwitchedByIgnition" SG_ 332 OBDProtocol_req 0;
BA_ "Fehlerwert" SG_ 332 OBDProtocol_req 255;
BA_ "GenSigSendType" SG_ 332 TSK_ACC_FoD_Status 0;
BA_ "GenSigSwitchedByIgnition" SG_ 332 TSK_ACC_FoD_Status 0;
BA_ "GenSigSendType" SG_ 332 TSK_aktives_System 3;
BA_ "GenSigSwitchedByIgnition" SG_ 332 TSK_aktives_System 0;
BA_ "GenSigSendType" SG_ 332 TSK_aktives_System_02 3;
BA_ "GenSigSwitchedByIgnition" SG_ 332 TSK_aktives_System_02 0;
BA_ "GenSigSendType" SG_ 332 TSK_Anf_Antriebsmoment 3;
BA_ "GenSigSwitchedByIgnition" SG_ 332 TSK_Anf_Antriebsmoment 0;
BA_ "GenSigSendType" SG_ 332 TSK_Einheit_vMax_Fahrerassistenz 0;
BA_ "GenSigSwitchedByIgnition" SG_ 332 TSK_Einheit_vMax_Fahrerassistenz 0;
BA_ "GenSigSendType" SG_ 332 TSK_erhoehter_Fahrwiderstand 3;
BA_ "GenSigSwitchedByIgnition" SG_ 332 TSK_erhoehter_Fahrwiderstand 0;
BA_ "GenSigSendType" SG_ 332 TSK_GRA_FoD_Status 0;
BA_ "GenSigSwitchedByIgnition" SG_ 332 TSK_GRA_FoD_Status 0;
BA_ "GenSigSendType" SG_ 332 TSK_Status_ARA 3;
BA_ "GenSigStartValue" SG_ 332 TSK_Status_ARA 1;
BA_ "GenSigSwitchedByIgnition" SG_ 332 TSK_Status_ARA 0;
BA_ "Fehlerwert" SG_ 332 TSK_Status_ARA 7;
BA_ "GenSigSendType" SG_ 332 TSK_Status_EA 3;
BA_ "GenSigStartValue" SG_ 332 TSK_Status_EA 1;
BA_ "GenSigSwitchedByIgnition" SG_ 332 TSK_Status_EA 0;
BA_ "Fehlerwert" SG_ 332 TSK_Status_EA 7;
BA_ "GenSigSendType" SG_ 332 TSK_Status_IPA 3;
BA_ "GenSigStartValue" SG_ 332 TSK_Status_IPA 1;
BA_ "GenSigSwitchedByIgnition" SG_ 332 TSK_Status_IPA 0;
BA_ "Fehlerwert" SG_ 332 TSK_Status_IPA 7;
BA_ "GenSigSendType" SG_ 332 TSK_Status_PLA 3;
BA_ "GenSigStartValue" SG_ 332 TSK_Status_PLA 1;
BA_ "GenSigSwitchedByIgnition" SG_ 332 TSK_Status_PLA 0;
BA_ "Fehlerwert" SG_ 332 TSK_Status_PLA 7;
BA_ "GenSigSendType" SG_ 332 TSK_Status_RHP 3;
BA_ "GenSigStartValue" SG_ 332 TSK_Status_RHP 1;
BA_ "GenSigSwitchedByIgnition" SG_ 332 TSK_Status_RHP 0;
BA_ "GenSigSendType" SG_ 332 TSK_vMax_aktuell 0;
BA_ "GenSigStartValue" SG_ 332 TSK_vMax_aktuell 255;
BA_ "GenSigSendType" SG_ 332 TSK_vMax_Fahrerassistenz 0;
BA_ "GenSigStartValue" SG_ 332 TSK_vMax_Fahrerassistenz 511;
BA_ "GenSigSwitchedByIgnition" SG_ 332 TSK_vMax_Fahrerassistenz 0;
BA_ "GenSigSendType" SG_ 1601 MO_Ansaugsystem 0;
BA_ "GenSigFuncType" SG_ 1601 MO_Ansaugsystem 8;
BA_ "GenSigSwitchedByIgnition" SG_ 1601 MO_Ansaugsystem 0;
BA_ "GenSigSendType" SG_ 1601 MO_Anzahl_Zyl 0;
BA_ "GenSigFuncType" SG_ 1601 MO_Anzahl_Zyl 8;
BA_ "GenSigSwitchedByIgnition" SG_ 1601 MO_Anzahl_Zyl 0;
BA_ "GenSigSendType" SG_ 1601 MO_Anzeige_StSt_gueltig 0;
BA_ "GenSigSwitchedByIgnition" SG_ 1601 MO_Anzeige_StSt_gueltig 0;
BA_ "GenSigSendType" SG_ 1601 MO_Code 0;
BA_ "GenSigSwitchedByIgnition" SG_ 1601 MO_Code 0;
BA_ "GenSigSendType" SG_ 1601 MO_DPF_verbaut 0;
BA_ "GenSigFuncType" SG_ 1601 MO_DPF_verbaut 8;
BA_ "GenSigSwitchedByIgnition" SG_ 1601 MO_DPF_verbaut 0;
BA_ "GenSigSendType" SG_ 1601 MO_Faktor_Momente_02 0;
BA_ "GenSigFuncType" SG_ 1601 MO_Faktor_Momente_02 8;
BA_ "GenSigSwitchedByIgnition" SG_ 1601 MO_Faktor_Momente_02 0;
BA_ "GenSigSendType" SG_ 1601 MO_Getriebe_Code 0;
BA_ "GenSigSwitchedByIgnition" SG_ 1601 MO_Getriebe_Code 0;
BA_ "GenSigSendType" SG_ 1601 MO_Hubraum 0;
BA_ "GenSigFuncType" SG_ 1601 MO_Hubraum 8;
BA_ "GenSigSwitchedByIgnition" SG_ 1601 MO_Hubraum 0;
BA_ "GenSigSendType" SG_ 1601 MO_Hybridfahrzeug 0;
BA_ "GenSigFuncType" SG_ 1601 MO_Hybridfahrzeug 8;
BA_ "GenSigSwitchedByIgnition" SG_ 1601 MO_Hybridfahrzeug 0;
BA_ "GenSigSendType" SG_ 1601 MO_Kraftstoffart 0;
BA_ "GenSigFuncType" SG_ 1601 MO_Kraftstoffart 8;
BA_ "GenSigSwitchedByIgnition" SG_ 1601 MO_Kraftstoffart 0;
BA_ "GenSigSendType" SG_ 1601 MO_Leistung 0;
BA_ "GenSigSwitchedByIgnition" SG_ 1601 MO_Leistung 0;
BA_ "GenSigSendType" SG_ 1601 MO_OBD_Typ 0;
BA_ "GenSigSwitchedByIgnition" SG_ 1601 MO_OBD_Typ 0;
BA_ "GenSigSendType" SG_ 1601 MO_StartStopp_Codiert 0;
BA_ "GenSigFuncType" SG_ 1601 MO_StartStopp_Codiert 8;
BA_ "GenSigSwitchedByIgnition" SG_ 1601 MO_StartStopp_Codiert 0;
BA_ "GenSigSendType" SG_ 1601 Motor_Code_01_BZ 0;
BA_ "GenSigFuncType" SG_ 1601 Motor_Code_01_BZ 1;
BA_ "GenSigSwitchedByIgnition" SG_ 1601 Motor_Code_01_BZ 0;
BA_ "GenSigSendType" SG_ 1601 Motor_Code_01_CRC 0;
BA_ "GenSigFuncType" SG_ 1601 Motor_Code_01_CRC 2;
BA_ "GenSigSwitchedByIgnition" SG_ 1601 Motor_Code_01_CRC 0;
BA_ "GenSigSendType" SG_ 1601 TSK_Codierung 0;
BA_ "GenSigStartValue" SG_ 1601 TSK_Codierung 7;
BA_ "GenSigSwitchedByIgnition" SG_ 1601 TSK_Codierung 0;
BA_ "GenSigSendType" SG_ 391 EV_Rekuperationsstufe 0;
BA_ "GenSigSwitchedByIgnition" SG_ 391 EV_Rekuperationsstufe 0;
BA_ "GenSigSendType" SG_ 391 MO_Drehzahl_VM 0;
BA_ "GenSigSwitchedByIgnition" SG_ 391 MO_Drehzahl_VM 0;
BA_ "GenSigSendType" SG_ 391 MO_Fehler_Notabschaltung_Klima 3;
BA_ "GenSigSwitchedByIgnition" SG_ 391 MO_Fehler_Notabschaltung_Klima 0;
BA_ "GenSigSendType" SG_ 391 MO_Fehler_NTKreis 0;
BA_ "GenSigSwitchedByIgnition" SG_ 391 MO_Fehler_NTKreis 0;
BA_ "Fehlerwert" SG_ 391 MO_Fehler_NTKreis 1;
BA_ "GenSigSendType" SG_ 391 MO_KLE_FStatus 0;
BA_ "GenSigSwitchedByIgnition" SG_ 391 MO_KLE_FStatus 0;
BA_ "Fehlerwert" SG_ 391 MO_KLE_FStatus 3;
BA_ "GenSigSendType" SG_ 391 MO_Tankbereitschaft_Status 0;
BA_ "GenSigSwitchedByIgnition" SG_ 391 MO_Tankbereitschaft_Status 0;
BA_ "GenSigSendType" SG_ 391 MO_Tankklappensteuerung 0;
BA_ "GenSigSwitchedByIgnition" SG_ 391 MO_Tankklappensteuerung 0;
BA_ "GenSigSendType" SG_ 391 MO_Waehlpos 3;
BA_ "GenSigSwitchedByIgnition" SG_ 391 MO_Waehlpos 0;
BA_ "Fehlerwert" SG_ 391 MO_Waehlpos 7;
BA_ "GenSigSendType" SG_ 391 MO_WH_Texte 3;
BA_ "GenSigSwitchedByIgnition" SG_ 391 MO_WH_Texte 0;
BA_ "GenSigSendType" SG_ 391 Motor_EV_01_BZ 0;
BA_ "GenSigFuncType" SG_ 391 Motor_EV_01_BZ 1;
BA_ "GenSigSwitchedByIgnition" SG_ 391 Motor_EV_01_BZ 0;
BA_ "GenSigSendType" SG_ 391 Motor_EV_01_CRC 0;
BA_ "GenSigFuncType" SG_ 391 Motor_EV_01_CRC 2;
BA_ "GenSigSwitchedByIgnition" SG_ 391 Motor_EV_01_CRC 0;
BA_ "GenSigSwitchedByIgnition" SG_ 16 WFS_MSG1_CRC 0;
BA_ "GenSigSendType" SG_ 16 WFS_MSG1_RND 1;
BA_ "GenSigSwitchedByIgnition" SG_ 16 WFS_MSG1_RND 0;
BA_ "GenSigSwitchedByIgnition" SG_ 22 WFS_MSG3_CRC 0;
BA_ "GenSigSendType" SG_ 22 WFS_MSG3_RND 1;
BA_ "GenSigSwitchedByIgnition" SG_ 22 WFS_MSG3_RND 0;
BA_ "GenSigSwitchedByIgnition" SG_ 24 WFS_MSG4_CRC 0;
BA_ "GenSigSendType" SG_ 24 WFS_MSG4_RND 1;
BA_ "GenSigSwitchedByIgnition" SG_ 24 WFS_MSG4_RND 0;
BA_ "GenSigSendType" SG_ 2527679770 NavMan_ApproachDistanceInPercent 0;
BA_ "GenSigStartValue" SG_ 2527679770 NavMan_ApproachDistanceInPercent 126;
BA_ "GenSigSwitchedByIgnition" SG_ 2527679770 NavMan_ApproachDistanceInPercent 0;
BA_ "GenSigSendType" SG_ 2527679770 NavMan_DirectionType 0;
BA_ "GenSigSwitchedByIgnition" SG_ 2527679770 NavMan_DirectionType 0;
BA_ "GenSigSendType" SG_ 2527679770 NavMan_Distance 0;
BA_ "GenSigSendType" SG_ 2527679770 NavMan_Distance_Unit 0;
BA_ "GenSigSendType" SG_ 2527679770 NavMan_MainType 0;
BA_ "GenSigSwitchedByIgnition" SG_ 2527679770 NavMan_MainType 0;
BA_ "GenSigSendType" SG_ 2527679645 NFC_MiKo_ESM_aktiv 0;
BA_ "GenSigSwitchedByIgnition" SG_ 2527679645 NFC_MiKo_ESM_aktiv 0;
BA_ "GenSigSendType" SG_ 2527679645 NFC_MiKo_Fehler 0;
BA_ "GenSigSwitchedByIgnition" SG_ 2527679645 NFC_MiKo_Fehler 0;
BA_ "GenSigSendType" SG_ 2527679645 NFC_MiKo_Laden_unterbrechen 0;
BA_ "GenSigSwitchedByIgnition" SG_ 2527679645 NFC_MiKo_Laden_unterbrechen 0;
BA_ "GenSigSendType" SG_ 2527679645 NFC_MiKo_NFC_Device_gekoppelt 0;
BA_ "GenSigSwitchedByIgnition" SG_ 2527679645 NFC_MiKo_NFC_Device_gekoppelt 0;
BA_ "GenSigSendType" SG_ 2527679645 NFC_MiKo_NFC_Device_Status 0;
BA_ "GenSigSwitchedByIgnition" SG_ 2527679645 NFC_MiKo_NFC_Device_Status 0;
BA_ "GenSigSendType" SG_ 2527679646 KY_Oeffnen_Annaeherung 0;
BA_ "GenSigSwitchedByIgnition" SG_ 2527679646 KY_Oeffnen_Annaeherung 0;
BA_ "GenSigSendType" SG_ 2527679646 KY_Oeffnen_Betaetigung 0;
BA_ "GenSigSwitchedByIgnition" SG_ 2527679646 KY_Oeffnen_Betaetigung 0;
BA_ "GenSigSendType" SG_ 2527679646 KY_Schliessen_Annaeherung 0;
BA_ "GenSigSwitchedByIgnition" SG_ 2527679646 KY_Schliessen_Annaeherung 0;
BA_ "GenSigSendType" SG_ 2527679646 KY_Schliessen_Betaetigung 0;
BA_ "GenSigSwitchedByIgnition" SG_ 2527679646 KY_Schliessen_Betaetigung 0;
BA_ "GenSigSendType" SG_ 2527679646 NFC_TGS_ESM_aktiv 0;
BA_ "GenSigSwitchedByIgnition" SG_ 2527679646 NFC_TGS_ESM_aktiv 0;
BA_ "GenSigSendType" SG_ 2527679646 NFC_TGS_Fehler 0;
BA_ "GenSigSwitchedByIgnition" SG_ 2527679646 NFC_TGS_Fehler 0;
BA_ "GenSigSendType" SG_ 2527679646 NFC_TGS_Licht_Fehler 0;
BA_ "GenSigSwitchedByIgnition" SG_ 2527679646 NFC_TGS_Licht_Fehler 0;
BA_ "GenSigSendType" SG_ 2527679646 NFC_TGS_NFC_Device_gekoppelt 0;
BA_ "GenSigSwitchedByIgnition" SG_ 2527679646 NFC_TGS_NFC_Device_gekoppelt 0;
BA_ "GenSigSendType" SG_ 2527679646 NFC_TGS_NFC_Device_Status 0;
BA_ "GenSigSwitchedByIgnition" SG_ 2527679646 NFC_TGS_NFC_Device_Status 0;
BA_ "GenSigFuncType" SG_ 2600468494 NM_BCM1_CAB_V14 16;
BA_ "GenSigSwitchedByIgnition" SG_ 2600468494 NM_BCM1_CAB_V14 0;
BA_ "GenSigSwitchedByIgnition" SG_ 2600468494 NM_BCM1_Car_Wakeup 0;
BA_ "GenSigSwitchedByIgnition" SG_ 2600468494 NM_BCM1_CBV_AWB 0;
BA_ "GenSigSwitchedByIgnition" SG_ 2600468494 NM_BCM1_CBV_CRI 0;
BA_ "GenSigSwitchedByIgnition" SG_ 2600468494 NM_BCM1_NM_aktiv_Applikation 0;
BA_ "GenSigSwitchedByIgnition" SG_ 2600468494 NM_BCM1_NM_aktiv_Aussenlicht 0;
BA_ "GenSigSwitchedByIgnition" SG_ 2600468494 NM_BCM1_NM_aktiv_Diagnose 0;
BA_ "GenSigSwitchedByIgnition" SG_ 2600468494 NM_BCM1_NM_aktiv_DWA 0;
BA_ "GenSigSwitchedByIgnition" SG_ 2600468494 NM_BCM1_NM_aktiv_Funk 0;
BA_ "GenSigSwitchedByIgnition" SG_ 2600468494 NM_BCM1_NM_aktiv_Heizung 0;
BA_ "GenSigSwitchedByIgnition" SG_ 2600468494 NM_BCM1_NM_aktiv_Innenlicht 0;
BA_ "GenSigSwitchedByIgnition" SG_ 2600468494 NM_BCM1_NM_aktiv_Kessy 0;
BA_ "GenSigSwitchedByIgnition" SG_ 2600468494 NM_BCM1_NM_aktiv_KL15 0;
BA_ "GenSigSwitchedByIgnition" SG_ 2600468494 NM_BCM1_NM_aktiv_Remot_Door_L_Un 0;
BA_ "GenSigSwitchedByIgnition" SG_ 2600468494 NM_BCM1_NM_aktiv_Remotestart 0;
BA_ "GenSigSwitchedByIgnition" SG_ 2600468494 NM_BCM1_NM_aktiv_TK_geschlossen 0;
BA_ "GenSigSwitchedByIgnition" SG_ 2600468494 NM_BCM1_NM_aktiv_Tmin 0;
BA_ "GenSigSwitchedByIgnition" SG_ 2600468494 NM_BCM1_NM_aktiv_VLW 0;
BA_ "GenSigSwitchedByIgnition" SG_ 2600468494 NM_BCM1_NM_aktiv_ZV 0;
BA_ "GenSigSwitchedByIgnition" SG_ 2600468494 NM_BCM1_NM_State 0;
BA_ "GenSigSwitchedByIgnition" SG_ 2600468494 NM_BCM1_UDS_CC 0;
BA_ "GenSigFuncType" SG_ 2600468496 NM_Gateway_CAB_V14 16;
BA_ "GenSigSwitchedByIgnition" SG_ 2600468496 NM_Gateway_CAB_V14 0;
BA_ "GenSigSwitchedByIgnition" SG_ 2600468496 NM_Gateway_Car_Wakeup 0;
BA_ "GenSigSwitchedByIgnition" SG_ 2600468496 NM_Gateway_CBV_AWB 0;
BA_ "GenSigSwitchedByIgnition" SG_ 2600468496 NM_Gateway_CBV_CRI 0;
BA_ "GenSigSwitchedByIgnition" SG_ 2600468496 NM_Gateway_NM_aktiv_Buskopplung 0;
BA_ "GenSigSwitchedByIgnition" SG_ 2600468496 NM_Gateway_NM_aktiv_CWU 0;
BA_ "GenSigSwitchedByIgnition" SG_ 2600468496 NM_Gateway_NM_aktiv_Diagnose 0;
BA_ "GenSigSwitchedByIgnition" SG_ 2600468496 NM_Gateway_NM_aktiv_EM 0;
BA_ "GenSigSwitchedByIgnition" SG_ 2600468496 NM_Gateway_NM_aktiv_FC 0;
BA_ "GenSigSwitchedByIgnition" SG_ 2600468496 NM_Gateway_NM_aktiv_KL15 0;
BA_ "GenSigSwitchedByIgnition" SG_ 2600468496 NM_Gateway_NM_aktiv_Tmin 0;
BA_ "GenSigSwitchedByIgnition" SG_ 2600468496 NM_Gateway_NM_State 0;
BA_ "GenSigSwitchedByIgnition" SG_ 2600468496 NM_Gateway_UDS_CC 0;
BA_ "GenSigSwitchedByIgnition" SG_ 2600468555 NM_TSG_BFS_Car_Wakeup 0;
BA_ "GenSigSwitchedByIgnition" SG_ 2600468555 NM_TSG_BFS_CBV_AWB 0;
BA_ "GenSigSwitchedByIgnition" SG_ 2600468555 NM_TSG_BFS_CBV_CRI 0;
BA_ "GenSigSwitchedByIgnition" SG_ 2600468555 NM_TSG_BFS_NM_aktiv_Diagnose 0;
BA_ "GenSigSwitchedByIgnition" SG_ 2600468555 NM_TSG_BFS_NM_aktiv_KL15 0;
BA_ "GenSigSwitchedByIgnition" SG_ 2600468555 NM_TSG_BFS_NM_aktiv_LIN 0;
BA_ "GenSigSwitchedByIgnition" SG_ 2600468555 NM_TSG_BFS_NM_aktiv_Taster 0;
BA_ "GenSigSwitchedByIgnition" SG_ 2600468555 NM_TSG_BFS_NM_aktiv_Tmin 0;
BA_ "GenSigSwitchedByIgnition" SG_ 2600468555 NM_TSG_BFS_NM_State 0;
BA_ "GenSigSwitchedByIgnition" SG_ 2600468555 NM_TSG_BFS_UDS_CC 0;
BA_ "GenSigFuncType" SG_ 2600468555 NM_TSG_BT_CAB_V14 16;
BA_ "GenSigSwitchedByIgnition" SG_ 2600468555 NM_TSG_BT_CAB_V14 0;
BA_ "GenSigSwitchedByIgnition" SG_ 2600468554 NM_TSG_FS_Car_Wakeup 0;
BA_ "GenSigSwitchedByIgnition" SG_ 2600468554 NM_TSG_FS_CBV_AWB 0;
BA_ "GenSigSwitchedByIgnition" SG_ 2600468554 NM_TSG_FS_CBV_CRI 0;
BA_ "GenSigSwitchedByIgnition" SG_ 2600468554 NM_TSG_FS_NM_aktiv_Diagnose 0;
BA_ "GenSigSwitchedByIgnition" SG_ 2600468554 NM_TSG_FS_NM_aktiv_KL15 0;
BA_ "GenSigSwitchedByIgnition" SG_ 2600468554 NM_TSG_FS_NM_aktiv_LIN 0;
BA_ "GenSigSwitchedByIgnition" SG_ 2600468554 NM_TSG_FS_NM_aktiv_Taster 0;
BA_ "GenSigSwitchedByIgnition" SG_ 2600468554 NM_TSG_FS_NM_aktiv_Tmin 0;
BA_ "GenSigSwitchedByIgnition" SG_ 2600468554 NM_TSG_FS_NM_State 0;
BA_ "GenSigSwitchedByIgnition" SG_ 2600468554 NM_TSG_FS_UDS_CC 0;
BA_ "GenSigFuncType" SG_ 2600468554 NM_TSG_FT_CAB_V14 16;
BA_ "GenSigSwitchedByIgnition" SG_ 2600468554 NM_TSG_FT_CAB_V14 0;
BA_ "GenSigFuncType" SG_ 2600468543 NM_TSG_HBFS_CAB_V14 16;
BA_ "GenSigSwitchedByIgnition" SG_ 2600468543 NM_TSG_HBFS_CAB_V14 0;
BA_ "GenSigSwitchedByIgnition" SG_ 2600468543 NM_TSG_HBFS_Car_Wakeup 0;
BA_ "GenSigSwitchedByIgnition" SG_ 2600468543 NM_TSG_HBFS_CBV_AWB 0;
BA_ "GenSigSwitchedByIgnition" SG_ 2600468543 NM_TSG_HBFS_CBV_CRI 0;
BA_ "GenSigSwitchedByIgnition" SG_ 2600468543 NM_TSG_HBFS_NM_aktiv_Diagnose 0;
BA_ "GenSigSwitchedByIgnition" SG_ 2600468543 NM_TSG_HBFS_NM_aktiv_KL15 0;
BA_ "GenSigSwitchedByIgnition" SG_ 2600468543 NM_TSG_HBFS_NM_aktiv_Tmin 0;
BA_ "GenSigSwitchedByIgnition" SG_ 2600468543 NM_TSG_HBFS_NM_State 0;
BA_ "GenSigSwitchedByIgnition" SG_ 2600468543 NM_TSG_HBFS_UDS_CC 0;
BA_ "GenSigFuncType" SG_ 2600468542 NM_TSG_HFS_CAB_V14 16;
BA_ "GenSigSwitchedByIgnition" SG_ 2600468542 NM_TSG_HFS_CAB_V14 0;
BA_ "GenSigSwitchedByIgnition" SG_ 2600468542 NM_TSG_HFS_Car_Wakeup 0;
BA_ "GenSigSwitchedByIgnition" SG_ 2600468542 NM_TSG_HFS_CBV_AWB 0;
BA_ "GenSigSwitchedByIgnition" SG_ 2600468542 NM_TSG_HFS_CBV_CRI 0;
BA_ "GenSigSwitchedByIgnition" SG_ 2600468542 NM_TSG_HFS_NM_aktiv_Diagnose 0;
BA_ "GenSigSwitchedByIgnition" SG_ 2600468542 NM_TSG_HFS_NM_aktiv_KL15 0;
BA_ "GenSigSwitchedByIgnition" SG_ 2600468542 NM_TSG_HFS_NM_aktiv_Tmin 0;
BA_ "GenSigSwitchedByIgnition" SG_ 2600468542 NM_TSG_HFS_NM_State 0;
BA_ "GenSigSwitchedByIgnition" SG_ 2600468542 NM_TSG_HFS_UDS_CC 0;
BA_ "GenSigSwitchedByIgnition" SG_ 2600468645 NM_WLC1_aktiv_Diagnose 0;
BA_ "GenSigSwitchedByIgnition" SG_ 2600468645 NM_WLC1_aktiv_Tmin 0;
BA_ "GenSigFuncType" SG_ 2600468645 NM_WLC1_CAB_V14 16;
BA_ "GenSigSwitchedByIgnition" SG_ 2600468645 NM_WLC1_CAB_V14 0;
BA_ "GenSigSwitchedByIgnition" SG_ 2600468645 NM_WLC1_Car_Wakeup 0;
BA_ "GenSigSwitchedByIgnition" SG_ 2600468645 NM_WLC1_CBV_AWB 0;
BA_ "GenSigSwitchedByIgnition" SG_ 2600468645 NM_WLC1_CBV_CRI 0;
BA_ "GenSigSwitchedByIgnition" SG_ 2600468645 NM_WLC1_NM_aktiv_KL15 0;
BA_ "GenSigSwitchedByIgnition" SG_ 2600468645 NM_WLC1_NM_State 0;
BA_ "GenSigSwitchedByIgnition" SG_ 2600468645 NM_WLC1_UDS_CC 0;
BA_ "GenSigSendType" SG_ 2621440526 OBDC_BCM1_Req_FD_Data 3;
BA_ "GenSigFuncType" SG_ 2621440526 OBDC_BCM1_Req_FD_Data 9;
BA_ "GenSigSwitchedByIgnition" SG_ 2621440526 OBDC_BCM1_Req_FD_Data 0;
BA_ "GenSigSendType" SG_ 2621571598 OBDC_BCM1_Resp_FD_Data 3;
BA_ "GenSigFuncType" SG_ 2621571598 OBDC_BCM1_Resp_FD_Data 9;
BA_ "GenSigSwitchedByIgnition" SG_ 2621571598 OBDC_BCM1_Resp_FD_Data 0;
BA_ "GenSigSendType" SG_ 2549875386 OBDC_DDA_Req_Data 3;
BA_ "GenSigFuncType" SG_ 2549875386 OBDC_DDA_Req_Data 9;
BA_ "GenSigSwitchedByIgnition" SG_ 2549875386 OBDC_DDA_Req_Data 0;
BA_ "GenSigSendType" SG_ 2550006458 OBDC_DDA_Resp_Data 3;
BA_ "GenSigFuncType" SG_ 2550006458 OBDC_DDA_Resp_Data 9;
BA_ "GenSigSwitchedByIgnition" SG_ 2550006458 OBDC_DDA_Resp_Data 0;
BA_ "GenSigSendType" SG_ 2549940736 OBDC_Funktionaler_Req_All_Data 3;
BA_ "GenSigFuncType" SG_ 2549940736 OBDC_Funktionaler_Req_All_Data 9;
BA_ "GenSigSwitchedByIgnition" SG_ 2549940736 OBDC_Funktionaler_Req_All_Data 0;
BA_ "GenSigSendType" SG_ 2621506048 OBDC_Funktion_Req_All_FD_Data 3;
BA_ "GenSigFuncType" SG_ 2621506048 OBDC_Funktion_Req_All_FD_Data 9;
BA_ "GenSigSwitchedByIgnition" SG_ 2621506048 OBDC_Funktion_Req_All_FD_Data 0;
BA_ "GenSigSendType" SG_ 2549875250 OBDC_Kessy_Req_Data 3;
BA_ "GenSigFuncType" SG_ 2549875250 OBDC_Kessy_Req_Data 9;
BA_ "GenSigSwitchedByIgnition" SG_ 2549875250 OBDC_Kessy_Req_Data 0;
BA_ "GenSigSendType" SG_ 2550006322 OBDC_Kessy_Resp_Data 3;
BA_ "GenSigFuncType" SG_ 2550006322 OBDC_Kessy_Resp_Data 9;
BA_ "GenSigSwitchedByIgnition" SG_ 2550006322 OBDC_Kessy_Resp_Data 0;
BA_ "GenSigSendType" SG_ 2549875350 OBDC_LED_LM_L_Req_Data 3;
BA_ "GenSigFuncType" SG_ 2549875350 OBDC_LED_LM_L_Req_Data 9;
BA_ "GenSigSwitchedByIgnition" SG_ 2549875350 OBDC_LED_LM_L_Req_Data 0;
BA_ "GenSigSendType" SG_ 2550006422 OBDC_LED_LM_L_Resp_Data 3;
BA_ "GenSigFuncType" SG_ 2550006422 OBDC_LED_LM_L_Resp_Data 9;
BA_ "GenSigSwitchedByIgnition" SG_ 2550006422 OBDC_LED_LM_L_Resp_Data 0;
BA_ "GenSigSendType" SG_ 2549875351 OBDC_LED_LM_R_Req_Data 3;
BA_ "GenSigFuncType" SG_ 2549875351 OBDC_LED_LM_R_Req_Data 9;
BA_ "GenSigSwitchedByIgnition" SG_ 2549875351 OBDC_LED_LM_R_Req_Data 0;
BA_ "GenSigSendType" SG_ 2550006423 OBDC_LED_LM_R_Resp_Data 3;
BA_ "GenSigFuncType" SG_ 2550006423 OBDC_LED_LM_R_Resp_Data 9;
BA_ "GenSigSwitchedByIgnition" SG_ 2550006423 OBDC_LED_LM_R_Resp_Data 0;
BA_ "GenSigSendType" SG_ 2550399491 OBDC_RSAD_HL_Req_Data 3;
BA_ "GenSigFuncType" SG_ 2550399491 OBDC_RSAD_HL_Req_Data 9;
BA_ "GenSigSwitchedByIgnition" SG_ 2550399491 OBDC_RSAD_HL_Req_Data 0;
BA_ "GenSigSendType" SG_ 2621702659 OBDC_RSAD_HL_Req_FD_Data 3;
BA_ "GenSigFuncType" SG_ 2621702659 OBDC_RSAD_HL_Req_FD_Data 9;
BA_ "GenSigSwitchedByIgnition" SG_ 2621702659 OBDC_RSAD_HL_Req_FD_Data 0;
BA_ "GenSigSendType" SG_ 2550530563 OBDC_RSAD_HL_Resp_Data 3;
BA_ "GenSigFuncType" SG_ 2550530563 OBDC_RSAD_HL_Resp_Data 9;
BA_ "GenSigSwitchedByIgnition" SG_ 2550530563 OBDC_RSAD_HL_Resp_Data 0;
BA_ "GenSigSendType" SG_ 2621833731 OBDC_RSAD_HL_Resp_FD_Data 3;
BA_ "GenSigFuncType" SG_ 2621833731 OBDC_RSAD_HL_Resp_FD_Data 9;
BA_ "GenSigSwitchedByIgnition" SG_ 2621833731 OBDC_RSAD_HL_Resp_FD_Data 0;
BA_ "GenSigSendType" SG_ 2550399492 OBDC_RSAD_HR_Req_Data 3;
BA_ "GenSigFuncType" SG_ 2550399492 OBDC_RSAD_HR_Req_Data 9;
BA_ "GenSigSwitchedByIgnition" SG_ 2550399492 OBDC_RSAD_HR_Req_Data 0;
BA_ "GenSigSendType" SG_ 2621702660 OBDC_RSAD_HR_Req_FD_Data 3;
BA_ "GenSigFuncType" SG_ 2621702660 OBDC_RSAD_HR_Req_FD_Data 9;
BA_ "GenSigSwitchedByIgnition" SG_ 2621702660 OBDC_RSAD_HR_Req_FD_Data 0;
BA_ "GenSigSendType" SG_ 2550530564 OBDC_RSAD_HR_Resp_Data 3;
BA_ "GenSigFuncType" SG_ 2550530564 OBDC_RSAD_HR_Resp_Data 9;
BA_ "GenSigSwitchedByIgnition" SG_ 2550530564 OBDC_RSAD_HR_Resp_Data 0;
BA_ "GenSigSendType" SG_ 2621833732 OBDC_RSAD_HR_Resp_FD_Data 3;
BA_ "GenSigFuncType" SG_ 2621833732 OBDC_RSAD_HR_Resp_FD_Data 9;
BA_ "GenSigSwitchedByIgnition" SG_ 2621833732 OBDC_RSAD_HR_Resp_FD_Data 0;
BA_ "GenSigSendType" SG_ 2621702709 OBDC_RSAD_IN2_Req_FD_Data 3;
BA_ "GenSigFuncType" SG_ 2621702709 OBDC_RSAD_IN2_Req_FD_Data 9;
BA_ "GenSigSwitchedByIgnition" SG_ 2621702709 OBDC_RSAD_IN2_Req_FD_Data 0;
BA_ "GenSigSendType" SG_ 2621833781 OBDC_RSAD_IN2_Resp_FD_Data 3;
BA_ "GenSigFuncType" SG_ 2621833781 OBDC_RSAD_IN2_Resp_FD_Data 9;
BA_ "GenSigSwitchedByIgnition" SG_ 2621833781 OBDC_RSAD_IN2_Resp_FD_Data 0;
BA_ "GenSigSendType" SG_ 2621702710 OBDC_RSAD_IN3_Req_FD_Data 3;
BA_ "GenSigFuncType" SG_ 2621702710 OBDC_RSAD_IN3_Req_FD_Data 9;
BA_ "GenSigSwitchedByIgnition" SG_ 2621702710 OBDC_RSAD_IN3_Req_FD_Data 0;
BA_ "GenSigSendType" SG_ 2621833782 OBDC_RSAD_IN3_Resp_FD_Data 3;
BA_ "GenSigFuncType" SG_ 2621833782 OBDC_RSAD_IN3_Resp_FD_Data 9;
BA_ "GenSigSwitchedByIgnition" SG_ 2621833782 OBDC_RSAD_IN3_Resp_FD_Data 0;
BA_ "GenSigSendType" SG_ 2621702711 OBDC_RSAD_IN4_Req_FD_Data 3;
BA_ "GenSigFuncType" SG_ 2621702711 OBDC_RSAD_IN4_Req_FD_Data 9;
BA_ "GenSigSwitchedByIgnition" SG_ 2621702711 OBDC_RSAD_IN4_Req_FD_Data 0;
BA_ "GenSigSendType" SG_ 2621833783 OBDC_RSAD_IN4_Resp_FD_Data 3;
BA_ "GenSigFuncType" SG_ 2621833783 OBDC_RSAD_IN4_Resp_FD_Data 9;
BA_ "GenSigSwitchedByIgnition" SG_ 2621833783 OBDC_RSAD_IN4_Resp_FD_Data 0;
BA_ "GenSigSendType" SG_ 2550399493 OBDC_RSAD_IN_Req_Data 3;
BA_ "GenSigFuncType" SG_ 2550399493 OBDC_RSAD_IN_Req_Data 9;
BA_ "GenSigSwitchedByIgnition" SG_ 2550399493 OBDC_RSAD_IN_Req_Data 0;
BA_ "GenSigSendType" SG_ 2621702661 OBDC_RSAD_IN_Req_FD_Data 3;
BA_ "GenSigFuncType" SG_ 2621702661 OBDC_RSAD_IN_Req_FD_Data 9;
BA_ "GenSigSwitchedByIgnition" SG_ 2621702661 OBDC_RSAD_IN_Req_FD_Data 0;
BA_ "GenSigSendType" SG_ 2550530565 OBDC_RSAD_IN_Resp_Data 3;
BA_ "GenSigFuncType" SG_ 2550530565 OBDC_RSAD_IN_Resp_Data 9;
BA_ "GenSigSwitchedByIgnition" SG_ 2550530565 OBDC_RSAD_IN_Resp_Data 0;
BA_ "GenSigSendType" SG_ 2621833733 OBDC_RSAD_IN_Resp_FD_Data 3;
BA_ "GenSigFuncType" SG_ 2621833733 OBDC_RSAD_IN_Resp_FD_Data 9;
BA_ "GenSigSwitchedByIgnition" SG_ 2621833733 OBDC_RSAD_IN_Resp_FD_Data 0;
BA_ "GenSigSendType" SG_ 2550399489 OBDC_RSAD_VL_Req_Data 3;
BA_ "GenSigFuncType" SG_ 2550399489 OBDC_RSAD_VL_Req_Data 9;
BA_ "GenSigSwitchedByIgnition" SG_ 2550399489 OBDC_RSAD_VL_Req_Data 0;
BA_ "GenSigSendType" SG_ 2621702657 OBDC_RSAD_VL_Req_FD_Data 3;
BA_ "GenSigFuncType" SG_ 2621702657 OBDC_RSAD_VL_Req_FD_Data 9;
BA_ "GenSigSwitchedByIgnition" SG_ 2621702657 OBDC_RSAD_VL_Req_FD_Data 0;
BA_ "GenSigSendType" SG_ 2550530561 OBDC_RSAD_VL_Resp_Data 3;
BA_ "GenSigFuncType" SG_ 2550530561 OBDC_RSAD_VL_Resp_Data 9;
BA_ "GenSigSwitchedByIgnition" SG_ 2550530561 OBDC_RSAD_VL_Resp_Data 0;
BA_ "GenSigSendType" SG_ 2621833729 OBDC_RSAD_VL_Resp_FD_Data 3;
BA_ "GenSigFuncType" SG_ 2621833729 OBDC_RSAD_VL_Resp_FD_Data 9;
BA_ "GenSigSwitchedByIgnition" SG_ 2621833729 OBDC_RSAD_VL_Resp_FD_Data 0;
BA_ "GenSigSendType" SG_ 2550399490 OBDC_RSAD_VR_Req_Data 3;
BA_ "GenSigFuncType" SG_ 2550399490 OBDC_RSAD_VR_Req_Data 9;
BA_ "GenSigSwitchedByIgnition" SG_ 2550399490 OBDC_RSAD_VR_Req_Data 0;
BA_ "GenSigSendType" SG_ 2621702658 OBDC_RSAD_VR_Req_FD_Data 3;
BA_ "GenSigFuncType" SG_ 2621702658 OBDC_RSAD_VR_Req_FD_Data 9;
BA_ "GenSigSwitchedByIgnition" SG_ 2621702658 OBDC_RSAD_VR_Req_FD_Data 0;
BA_ "GenSigSendType" SG_ 2550530562 OBDC_RSAD_VR_Resp_Data 3;
BA_ "GenSigFuncType" SG_ 2550530562 OBDC_RSAD_VR_Resp_Data 9;
BA_ "GenSigSwitchedByIgnition" SG_ 2550530562 OBDC_RSAD_VR_Resp_Data 0;
BA_ "GenSigSendType" SG_ 2621833730 OBDC_RSAD_VR_Resp_FD_Data 3;
BA_ "GenSigFuncType" SG_ 2621833730 OBDC_RSAD_VR_Resp_FD_Data 9;
BA_ "GenSigSwitchedByIgnition" SG_ 2621833730 OBDC_RSAD_VR_Resp_FD_Data 0;
BA_ "GenSigSendType" SG_ 2549903595 OBDC_SSN_NFC_TGS_Req_Data 3;
BA_ "GenSigFuncType" SG_ 2549903595 OBDC_SSN_NFC_TGS_Req_Data 9;
BA_ "GenSigSwitchedByIgnition" SG_ 2549903595 OBDC_SSN_NFC_TGS_Req_Data 0;
BA_ "GenSigSendType" SG_ 2550034667 OBDC_SSN_NFC_TGS_Resp_Data 3;
BA_ "GenSigFuncType" SG_ 2550034667 OBDC_SSN_NFC_TGS_Resp_Data 9;
BA_ "GenSigSwitchedByIgnition" SG_ 2550034667 OBDC_SSN_NFC_TGS_Resp_Data 0;
BA_ "GenSigSendType" SG_ 2621440587 OBDC_TSG_BT_Req_FD_Data 3;
BA_ "GenSigFuncType" SG_ 2621440587 OBDC_TSG_BT_Req_FD_Data 9;
BA_ "GenSigSwitchedByIgnition" SG_ 2621440587 OBDC_TSG_BT_Req_FD_Data 0;
BA_ "GenSigSendType" SG_ 2621571659 OBDC_TSG_BT_Resp_FD_Data 3;
BA_ "GenSigFuncType" SG_ 2621571659 OBDC_TSG_BT_Resp_FD_Data 9;
BA_ "GenSigSwitchedByIgnition" SG_ 2621571659 OBDC_TSG_BT_Resp_FD_Data 0;
BA_ "GenSigSendType" SG_ 2621440586 OBDC_TSG_FT_Req_FD_Data 3;
BA_ "GenSigFuncType" SG_ 2621440586 OBDC_TSG_FT_Req_FD_Data 9;
BA_ "GenSigSwitchedByIgnition" SG_ 2621440586 OBDC_TSG_FT_Req_FD_Data 0;
BA_ "GenSigSendType" SG_ 2621571658 OBDC_TSG_FT_Resp_FD_Data 3;
BA_ "GenSigFuncType" SG_ 2621571658 OBDC_TSG_FT_Resp_FD_Data 9;
BA_ "GenSigSwitchedByIgnition" SG_ 2621571658 OBDC_TSG_FT_Resp_FD_Data 0;
BA_ "GenSigSendType" SG_ 2621440575 OBDC_TSG_HBFS_Req_FD_Data 3;
BA_ "GenSigFuncType" SG_ 2621440575 OBDC_TSG_HBFS_Req_FD_Data 9;
BA_ "GenSigSwitchedByIgnition" SG_ 2621440575 OBDC_TSG_HBFS_Req_FD_Data 0;
BA_ "GenSigSendType" SG_ 2621571647 OBDC_TSG_HBFS_Resp_FD_Data 3;
BA_ "GenSigFuncType" SG_ 2621571647 OBDC_TSG_HBFS_Resp_FD_Data 9;
BA_ "GenSigSwitchedByIgnition" SG_ 2621571647 OBDC_TSG_HBFS_Resp_FD_Data 0;
BA_ "GenSigSendType" SG_ 2621440574 OBDC_TSG_HFS_Req_FD_Data 3;
BA_ "GenSigFuncType" SG_ 2621440574 OBDC_TSG_HFS_Req_FD_Data 9;
BA_ "GenSigSwitchedByIgnition" SG_ 2621440574 OBDC_TSG_HFS_Req_FD_Data 0;
BA_ "GenSigSendType" SG_ 2621571646 OBDC_TSG_HFS_Resp_FD_Data 3;
BA_ "GenSigFuncType" SG_ 2621571646 OBDC_TSG_HFS_Resp_FD_Data 9;
BA_ "GenSigSwitchedByIgnition" SG_ 2621571646 OBDC_TSG_HFS_Resp_FD_Data 0;
BA_ "GenSigSendType" SG_ 2621440677 OBDC_WLC1_Req_FD_Data 3;
BA_ "GenSigFuncType" SG_ 2621440677 OBDC_WLC1_Req_FD_Data 9;
BA_ "GenSigSwitchedByIgnition" SG_ 2621440677 OBDC_WLC1_Req_FD_Data 0;
BA_ "GenSigSendType" SG_ 2621571749 OBDC_WLC1_Resp_FD_Data 3;
BA_ "GenSigFuncType" SG_ 2621571749 OBDC_WLC1_Resp_FD_Data 9;
BA_ "GenSigSwitchedByIgnition" SG_ 2621571749 OBDC_WLC1_Resp_FD_Data 0;
BA_ "GenSigSendType" SG_ 2564502513 OBDx_allOBD_Req_Data 3;
BA_ "GenSigFuncType" SG_ 2564502513 OBDx_allOBD_Req_Data 9;
BA_ "GenSigSwitchedByIgnition" SG_ 2564502513 OBDx_allOBD_Req_Data 0;
BA_ "GenSigSwitchedByIgnition" SG_ 28 OCU_WFS_Anfrage_CRC 0;
BA_ "GenSigSwitchedByIgnition" SG_ 28 OCU_WFS_Anfrage_Status 0;
BA_ "GenSigSwitchedByIgnition" SG_ 28 OCU_WFS_Anfrage_Typ 0;
BA_ "GenSigSendType" SG_ 2589283656 ORU_Status 3;
BA_ "GenSigSwitchedByIgnition" SG_ 2589283656 ORU_Status 0;
BA_ "GenSigSendType" SG_ 2589283656 ORU_Warnung 3;
BA_ "GenSigSwitchedByIgnition" SG_ 2589283656 ORU_Warnung 0;
BA_ "GenSigSendType" SG_ 2527679741 PAO_OFF_Status 0;
BA_ "GenSigSwitchedByIgnition" SG_ 2527679741 PAO_OFF_Status 0;
BA_ "GenSigSendType" SG_ 2527679741 PAO_ON_Status 0;
BA_ "GenSigSwitchedByIgnition" SG_ 2527679741 PAO_ON_Status 0;
BA_ "GenSigSendType" SG_ 2527679741 PAO_Status_01_BZ 0;
BA_ "GenSigFuncType" SG_ 2527679741 PAO_Status_01_BZ 1;
BA_ "GenSigSwitchedByIgnition" SG_ 2527679741 PAO_Status_01_BZ 0;
BA_ "GenSigSendType" SG_ 2527679741 PAO_Status_01_CRC 0;
BA_ "GenSigFuncType" SG_ 2527679741 PAO_Status_01_CRC 2;
BA_ "GenSigSwitchedByIgnition" SG_ 2527679741 PAO_Status_01_CRC 0;
BA_ "GenSigSendType" SG_ 2527679741 PAO_Status_Reserve_Byte3 0;
BA_ "GenSigSwitchedByIgnition" SG_ 2527679741 PAO_Status_Reserve_Byte3 0;
BA_ "GenSigSendType" SG_ 233 Parken_Aktives_Bedienelement 3;
BA_ "GenSigSwitchedByIgnition" SG_ 233 Parken_Aktives_Bedienelement 0;
BA_ "GenSigSendType" SG_ 233 Parken_Anhaltegrund_ext 3;
BA_ "GenSigSwitchedByIgnition" SG_ 233 Parken_Anhaltegrund_ext 0;
BA_ "GenSigSendType" SG_ 233 Parken_BT_Wunsch 3;
BA_ "GenSigSwitchedByIgnition" SG_ 233 Parken_BT_Wunsch 0;
BA_ "GenSigSendType" SG_ 233 Parken_Fahrtaster_Empfehlung 3;
BA_ "GenSigSwitchedByIgnition" SG_ 233 Parken_Fahrtaster_Empfehlung 0;
BA_ "GenSigSendType" SG_ 233 Parken_FFB_Status 3;
BA_ "GenSigSwitchedByIgnition" SG_ 233 Parken_FFB_Status 0;
BA_ "GenSigSendType" SG_ 233 Parken_Fortschrittszaehler 3;
BA_ "GenSigStartValue" SG_ 233 Parken_Fortschrittszaehler 127;
BA_ "GenSigSwitchedByIgnition" SG_ 233 Parken_Fortschrittszaehler 0;
BA_ "GenSigSendType" SG_ 233 Parken_Funktionsstatus 3;
BA_ "GenSigSwitchedByIgnition" SG_ 233 Parken_Funktionsstatus 0;
BA_ "GenSigSendType" SG_ 233 Parken_Hindernis_Bereich 3;
BA_ "GenSigSwitchedByIgnition" SG_ 233 Parken_Hindernis_Bereich 0;
BA_ "GenSigSendType" SG_ 233 Parken_Hindernis_erkannt 3;
BA_ "GenSigSwitchedByIgnition" SG_ 233 Parken_Hindernis_erkannt 0;
BA_ "GenSigSendType" SG_ 233 Parken_Manoever 3;
BA_ "GenSigSwitchedByIgnition" SG_ 233 Parken_Manoever 0;
BA_ "GenSigSendType" SG_ 233 Parken_Manoever_Aktiv 3;
BA_ "GenSigSwitchedByIgnition" SG_ 233 Parken_Manoever_Aktiv 0;
BA_ "GenSigSendType" SG_ 233 Parken_Reversieren_moeglich 3;
BA_ "GenSigSwitchedByIgnition" SG_ 233 Parken_Reversieren_moeglich 0;
BA_ "GenSigSendType" SG_ 233 Parken_Richtung 3;
BA_ "GenSigSwitchedByIgnition" SG_ 233 Parken_Richtung 0;
BA_ "GenSigSendType" SG_ 233 Parken_Richtung_Aktiv 3;
BA_ "GenSigSwitchedByIgnition" SG_ 233 Parken_Richtung_Aktiv 0;
BA_ "GenSigSendType" SG_ 233 Parken_Seite 3;
BA_ "GenSigSwitchedByIgnition" SG_ 233 Parken_Seite 0;
BA_ "GenSigSendType" SG_ 233 Parken_Seite_Aktiv 3;
BA_ "GenSigSwitchedByIgnition" SG_ 233 Parken_Seite_Aktiv 0;
BA_ "GenSigSendType" SG_ 233 Parken_SM_AktivesRemoteSystem 3;
BA_ "GenSigSwitchedByIgnition" SG_ 233 Parken_SM_AktivesRemoteSystem 0;
BA_ "GenSigSendType" SG_ 233 Parken_SM_Anhaenger 3;
BA_ "GenSigSwitchedByIgnition" SG_ 233 Parken_SM_Anhaenger 0;
BA_ "GenSigSendType" SG_ 233 Parken_SM_Fahrbereitschaft 3;
BA_ "GenSigSwitchedByIgnition" SG_ 233 Parken_SM_Fahrbereitschaft 0;
BA_ "GenSigSendType" SG_ 233 Parken_SM_Fahrstufe 3;
BA_ "GenSigSwitchedByIgnition" SG_ 233 Parken_SM_Fahrstufe 0;
BA_ "GenSigSendType" SG_ 233 Parken_SM_Schluessel 3;
BA_ "GenSigSwitchedByIgnition" SG_ 233 Parken_SM_Schluessel 0;
BA_ "GenSigSendType" SG_ 233 Parken_SM_Sensor 3;
BA_ "GenSigSwitchedByIgnition" SG_ 233 Parken_SM_Sensor 0;
BA_ "GenSigSendType" SG_ 233 Parken_SM_Stillstand 3;
BA_ "GenSigSwitchedByIgnition" SG_ 233 Parken_SM_Stillstand 0;
BA_ "GenSigSendType" SG_ 233 Parken_SM_Tueren 3;
BA_ "GenSigSwitchedByIgnition" SG_ 233 Parken_SM_Tueren 0;
BA_ "GenSigSendType" SG_ 233 Parken_Szenario 3;
BA_ "GenSigSwitchedByIgnition" SG_ 233 Parken_Szenario 0;
BA_ "GenSigSendType" SG_ 233 Parken_Szenario_Aktiv 3;
BA_ "GenSigSwitchedByIgnition" SG_ 233 Parken_Szenario_Aktiv 0;
BA_ "GenSigSendType" SG_ 233 Parken_Touchdiagnose_Anf 3;
BA_ "GenSigSwitchedByIgnition" SG_ 233 Parken_Touchdiagnose_Anf 0;
BA_ "GenSigSendType" SG_ 2463978635 Parken_Hindernis_erkannt_02 3;
BA_ "GenSigSwitchedByIgnition" SG_ 2463978635 Parken_Hindernis_erkannt_02 0;
BA_ "GenSigSendType" SG_ 2463978635 Parken_Szenario_02 3;
BA_ "GenSigSwitchedByIgnition" SG_ 2463978635 Parken_Szenario_02 0;
BA_ "GenSigSendType" SG_ 2463978635 Parken_Traj_aktueller_Zug 3;
BA_ "GenSigSwitchedByIgnition" SG_ 2463978635 Parken_Traj_aktueller_Zug 0;
BA_ "GenSigSendType" SG_ 2463978635 Parken_Traj_Anzahl_Punkte 3;
BA_ "GenSigSwitchedByIgnition" SG_ 2463978635 Parken_Traj_Anzahl_Punkte 0;
BA_ "GenSigSendType" SG_ 2463978635 Parken_Traj_Fahrtrichtung 3;
BA_ "GenSigSwitchedByIgnition" SG_ 2463978635 Parken_Traj_Fahrtrichtung 0;
BA_ "GenSigSendType" SG_ 2463978635 Parken_Traj_Fzg_Pos_X 3;
BA_ "GenSigSwitchedByIgnition" SG_ 2463978635 Parken_Traj_Fzg_Pos_X 0;
BA_ "GenSigSendType" SG_ 2463978635 Parken_Traj_Fzg_Pos_Y 3;
BA_ "GenSigSwitchedByIgnition" SG_ 2463978635 Parken_Traj_Fzg_Pos_Y 0;
BA_ "GenSigSendType" SG_ 2463978635 Parken_Traj_Fzg_Winkel 3;
BA_ "GenSigSwitchedByIgnition" SG_ 2463978635 Parken_Traj_Fzg_Winkel 0;
BA_ "GenSigSendType" SG_ 2463978635 Parken_Traj_letzter_Zug 3;
BA_ "GenSigSwitchedByIgnition" SG_ 2463978635 Parken_Traj_letzter_Zug 0;
BA_ "GenSigSendType" SG_ 2463978635 Parken_Traj_Trans_ID 3;
BA_ "GenSigSwitchedByIgnition" SG_ 2463978635 Parken_Traj_Trans_ID 0;
BA_ "GenSigSendType" SG_ 850 Parken_SM_03_MUX 0;
BA_ "GenSigSwitchedByIgnition" SG_ 850 Parken_SM_03_MUX 0;
BA_ "GenSigSwitchedByIgnition" SG_ 850 Parken_SM_03_Traj_Trans_ID_00 0;
BA_ "GenSigSwitchedByIgnition" SG_ 850 Parken_SM_03_Traj_Trans_ID_01 0;
BA_ "GenSigSwitchedByIgnition" SG_ 850 Parken_SM_03_Traj_Trans_ID_02 0;
BA_ "GenSigSwitchedByIgnition" SG_ 850 Parken_SM_03_Traj_Trans_ID_03 0;
BA_ "GenSigSwitchedByIgnition" SG_ 850 Parken_SM_03_Traj_Trans_ID_04 0;
BA_ "GenSigSwitchedByIgnition" SG_ 850 Parken_SM_03_Traj_Trans_ID_05 0;
BA_ "GenSigSwitchedByIgnition" SG_ 850 Parken_SM_03_Traj_Trans_ID_06 0;
BA_ "GenSigSwitchedByIgnition" SG_ 850 Parken_Traj_P1_Pos_X 0;
BA_ "GenSigSwitchedByIgnition" SG_ 850 Parken_Traj_P1_Pos_Y 0;
BA_ "GenSigSwitchedByIgnition" SG_ 850 Parken_Traj_P1_Tangent 0;
BA_ "GenSigSwitchedByIgnition" SG_ 850 Parken_Traj_P2_Pos_X 0;
BA_ "GenSigSwitchedByIgnition" SG_ 850 Parken_Traj_P2_Pos_Y 0;
BA_ "GenSigSwitchedByIgnition" SG_ 850 Parken_Traj_P2_Tangent 0;
BA_ "GenSigSwitchedByIgnition" SG_ 850 Parken_Traj_P3_Pos_X 0;
BA_ "GenSigSwitchedByIgnition" SG_ 850 Parken_Traj_P3_Pos_Y 0;
BA_ "GenSigSwitchedByIgnition" SG_ 850 Parken_Traj_P3_Tangent 0;
BA_ "GenSigSwitchedByIgnition" SG_ 850 Parken_Traj_P4_Pos_X 0;
BA_ "GenSigSwitchedByIgnition" SG_ 850 Parken_Traj_P4_Pos_Y 0;
BA_ "GenSigSwitchedByIgnition" SG_ 850 Parken_Traj_P4_Tangent 0;
BA_ "GenSigSwitchedByIgnition" SG_ 850 Parken_Traj_P5_Pos_X 0;
BA_ "GenSigSwitchedByIgnition" SG_ 850 Parken_Traj_P5_Pos_Y 0;
BA_ "GenSigSwitchedByIgnition" SG_ 850 Parken_Traj_P5_Tangent 0;
BA_ "GenSigSwitchedByIgnition" SG_ 850 Parken_Traj_P6_Pos_X 0;
BA_ "GenSigSwitchedByIgnition" SG_ 850 Parken_Traj_P6_Pos_Y 0;
BA_ "GenSigSwitchedByIgnition" SG_ 850 Parken_Traj_P6_Tangent 0;
BA_ "GenSigSwitchedByIgnition" SG_ 850 Parken_Traj_P7_Pos_X 0;
BA_ "GenSigSwitchedByIgnition" SG_ 850 Parken_Traj_P7_Pos_Y 0;
BA_ "GenSigSwitchedByIgnition" SG_ 850 Parken_Traj_P7_Tangent 0;
BA_ "GenSigSwitchedByIgnition" SG_ 850 Parken_Traj_P8_Pos_X 0;
BA_ "GenSigSwitchedByIgnition" SG_ 850 Parken_Traj_P8_Pos_Y 0;
BA_ "GenSigSwitchedByIgnition" SG_ 850 Parken_Traj_P8_Tangent 0;
BA_ "GenSigSwitchedByIgnition" SG_ 850 Parken_Traj_P9_Pos_X 0;
BA_ "GenSigSwitchedByIgnition" SG_ 850 Parken_Traj_P9_Pos_Y 0;
BA_ "GenSigSwitchedByIgnition" SG_ 850 Parken_Traj_P9_Tangent 0;
BA_ "GenSigSendType" SG_ 2527679498 IAA_Active_User_ID 4;
BA_ "GenSigSwitchedByIgnition" SG_ 2527679498 IAA_Active_User_ID 0;
BA_ "GenSigSendType" SG_ 2527679498 IAA_Identified_User_ID 4;
BA_ "GenSigSwitchedByIgnition" SG_ 2527679498 IAA_Identified_User_ID 0;
BA_ "GenSigSendType" SG_ 2527679498 IAA_PSO_wake_up 4;
BA_ "GenSigSwitchedByIgnition" SG_ 2527679498 IAA_PSO_wake_up 0;
BA_ "GenSigSendType" SG_ 2527679498 Perso_Aktiv 4;
BA_ "GenSigSwitchedByIgnition" SG_ 2527679498 Perso_Aktiv 0;
BA_ "GenSigSendType" SG_ 2527679498 Perso_Bedienstelle 4;
BA_ "GenSigSwitchedByIgnition" SG_ 2527679498 Perso_Bedienstelle 0;
BA_ "GenSigSendType" SG_ 2527679498 Perso_Fahrernummer 4;
BA_ "GenSigSwitchedByIgnition" SG_ 2527679498 Perso_Fahrernummer 0;
BA_ "GenSigSendType" SG_ 2527679498 Perso_Freigabe_Verstellung 4;
BA_ "GenSigSwitchedByIgnition" SG_ 2527679498 Perso_Freigabe_Verstellung 0;
BA_ "GenSigSendType" SG_ 2527679498 Perso_Kontonummer 4;
BA_ "GenSigSwitchedByIgnition" SG_ 2527679498 Perso_Kontonummer 0;
BA_ "GenSigSendType" SG_ 2527679498 Perso_Schreibschutz 4;
BA_ "GenSigSwitchedByIgnition" SG_ 2527679498 Perso_Schreibschutz 0;
BA_ "GenSigSendType" SG_ 2527679498 Perso_Status 1;
BA_ "GenSigSwitchedByIgnition" SG_ 2527679498 Perso_Status 0;
BA_ "GenSigSendType" SG_ 2527679498 Perso_Steuerung 4;
BA_ "GenSigSwitchedByIgnition" SG_ 2527679498 Perso_Steuerung 0;
BA_ "GenSigSendType" SG_ 2527679498 Perso_Steuerungsparameter 4;
BA_ "GenSigSwitchedByIgnition" SG_ 2527679498 Perso_Steuerungsparameter 0;
BA_ "GenSigSendType" SG_ 2463978629 IAA_Active_User_ID_02 4;
BA_ "GenSigSwitchedByIgnition" SG_ 2463978629 IAA_Active_User_ID_02 0;
BA_ "GenSigSendType" SG_ 2463978629 IAA_Identified_User_ID_02 4;
BA_ "GenSigSwitchedByIgnition" SG_ 2463978629 IAA_Identified_User_ID_02 0;
BA_ "GenSigSendType" SG_ 2463978629 Perso_Aktiv_02 4;
BA_ "GenSigSwitchedByIgnition" SG_ 2463978629 Perso_Aktiv_02 0;
BA_ "GenSigSendType" SG_ 2463978629 Perso_Bedienstelle_02 4;
BA_ "GenSigSwitchedByIgnition" SG_ 2463978629 Perso_Bedienstelle_02 0;
BA_ "GenSigSendType" SG_ 2463978629 Perso_Fahrernummer_02 4;
BA_ "GenSigSwitchedByIgnition" SG_ 2463978629 Perso_Fahrernummer_02 0;
BA_ "GenSigSendType" SG_ 2463978629 Perso_Freigabe_Verstellung_02 4;
BA_ "GenSigSwitchedByIgnition" SG_ 2463978629 Perso_Freigabe_Verstellung_02 0;
BA_ "GenSigSendType" SG_ 2463978629 Perso_Kontonummer_02 4;
BA_ "GenSigSwitchedByIgnition" SG_ 2463978629 Perso_Kontonummer_02 0;
BA_ "GenSigSendType" SG_ 2463978629 Perso_Schreibschutz_02 4;
BA_ "GenSigSwitchedByIgnition" SG_ 2463978629 Perso_Schreibschutz_02 0;
BA_ "GenSigSendType" SG_ 2463978629 Perso_Status_02 1;
BA_ "GenSigSwitchedByIgnition" SG_ 2463978629 Perso_Status_02 0;
BA_ "GenSigSendType" SG_ 2463978629 Perso_Steuerung_02 4;
BA_ "GenSigSwitchedByIgnition" SG_ 2463978629 Perso_Steuerung_02 0;
BA_ "GenSigSendType" SG_ 2463978629 Perso_Steuerungsparameter_02 4;
BA_ "GenSigSwitchedByIgnition" SG_ 2463978629 Perso_Steuerungsparameter_02 0;
BA_REL_ "GenSigTimeoutTime" BU_SG_REL_ BCM SG_ 332 Motor_54_CRC 1000;
BA_REL_ "GenSigTimeoutTime" BU_SG_REL_ BCM SG_ 332 Motor_54_BZ 1000;
BA_REL_ "GenSigTimeoutTime" BU_SG_REL_ BCM SG_ 332 MO_Kuppl_betaetigt 1000;
BA_REL_ "GenSigTimeoutTime" BU_SG_REL_ BCM SG_ 332 MO_QBit_Kuppl_betaetigt 1000;
BA_REL_ "GenSigTimeoutTime" BU_SG_REL_ BCM SG_ 332 MO_Fahrbereitschaft 1000;
BA_REL_ "GenSigTimeoutTime" BU_SG_REL_ BCM SG_ 332 MO_Startwunsch 1000;
BA_REL_ "GenSigTimeoutTime" BU_SG_REL_ BCM SG_ 1601 MO_Hybridfahrzeug 5000;
BA_REL_ "GenSigTimeoutTime" BU_SG_REL_ BCM SG_ 1601 MO_Getriebe_Code 5000;
BA_REL_ "GenSigTimeoutTime" BU_SG_REL_ BCM SG_ 391 MO_Waehlpos 1000;
BA_REL_ "GenSigTimeoutTime" BU_SG_REL_ BCM SG_ 391 MO_Tankklappensteuerung 1000;
BA_REL_ "GenSigTimeoutTime" BU_SG_REL_ BCM SG_ 2527679770 NavMan_MainType 2000;
BA_REL_ "GenSigTimeoutTime" BU_SG_REL_ BCM SG_ 2527679770 NavMan_ApproachDistanceInPercent 2000;
BA_REL_ "GenSigTimeoutTime" BU_SG_REL_ BCM SG_ 2527679770 NavMan_DirectionType 2000;
BA_REL_ "GenSigTimeoutTime" BU_SG_REL_ BCM SG_ 2527679645 NFC_MiKo_NFC_Device_Status 2000;
BA_REL_ "GenSigTimeoutTime" BU_SG_REL_ BCM SG_ 2527679645 NFC_MiKo_NFC_Device_gekoppelt 2000;
BA_REL_ "GenSigTimeoutTime" BU_SG_REL_ BCM SG_ 2600468496 NM_Gateway_NM_State 2000;
BA_REL_ "GenSigTimeoutTime" BU_SG_REL_ BCM SG_ 2600468555 NM_TSG_BFS_NM_State 2000;
BA_REL_ "GenSigTimeoutTime" BU_SG_REL_ BCM SG_ 2600468554 NM_TSG_FS_NM_State 2000;
BA_REL_ "GenSigTimeoutTime" BU_SG_REL_ BCM SG_ 2600468543 NM_TSG_HBFS_NM_State 2000;
BA_REL_ "GenSigTimeoutTime" BU_SG_REL_ BCM SG_ 2600468542 NM_TSG_HFS_NM_State 2000;
BA_REL_ "GenSigTimeoutTime" BU_SG_REL_ BCM SG_ 2600468645 NM_WLC1_NM_State 2000;
BA_REL_ "GenSigTimeoutTime" BU_SG_REL_ BCM SG_ 2589283656 ORU_Status 5000;
BA_REL_ "GenSigTimeoutTime" BU_SG_REL_ BCM SG_ 2463978629 Perso_Kontonummer_02 5000;
BA_REL_ "GenSigTimeoutTime" BU_SG_REL_ BCM SG_ 2463978629 Perso_Steuerung_02 5000;
BA_REL_ "GenSigTimeoutTime" BU_SG_REL_ BCM SG_ 2463978629 Perso_Steuerungsparameter_02 5000;
BA_REL_ "GenSigTimeoutTime" BU_SG_REL_ BCM SG_ 2463978629 Perso_Status_02 5000;
BA_REL_ "GenSigTimeoutTime" BU_SG_REL_ BCM SG_ 2463978629 Perso_Bedienstelle_02 5000;
BA_REL_ "GenSigTimeoutTime" BU_SG_REL_ BCM SG_ 2463978629 Perso_Freigabe_Verstellung_02 5000;
BA_REL_ "GenSigTimeoutTime" BU_SG_REL_ BCM SG_ 2463978629 Perso_Aktiv_02 5000;
BA_REL_ "GenSigTimeoutTime" BU_SG_REL_ BCM SG_ 2463978629 Perso_Fahrernummer_02 5000;
BA_REL_ "GenSigTimeoutTime" BU_SG_REL_ BCM SG_ 2463978629 Perso_Schreibschutz_02 5000;
BA_REL_ "GenSigTimeoutTime" BU_SG_REL_ BCM SG_ 2463978629 IAA_Active_User_ID_02 5000;
BA_REL_ "GenSigTimeoutTime" BU_SG_REL_ BCM SG_ 2463978629 IAA_Identified_User_ID_02 5000;
BA_REL_ "GenSigTimeoutTime" BU_SG_REL_ Gateway_Max SG_ 2600468494 NM_BCM1_CBV_AWB 2000;
BA_REL_ "GenSigTimeoutTime" BU_SG_REL_ Gateway_Max SG_ 2600468494 NM_BCM1_CBV_CRI 2000;
BA_REL_ "GenSigTimeoutTime" BU_SG_REL_ Gateway_Max SG_ 2600468494 NM_BCM1_Car_Wakeup 2000;
BA_REL_ "GenSigTimeoutTime" BU_SG_REL_ Gateway_Max SG_ 2600468494 NM_BCM1_CAB_V14 2000;
BA_REL_ "GenSigTimeoutTime" BU_SG_REL_ Gateway_Max SG_ 2600468555 NM_TSG_BFS_CBV_AWB 2000;
BA_REL_ "GenSigTimeoutTime" BU_SG_REL_ Gateway_Max SG_ 2600468555 NM_TSG_BFS_CBV_CRI 2000;
BA_REL_ "GenSigTimeoutTime" BU_SG_REL_ Gateway_Max SG_ 2600468555 NM_TSG_BFS_Car_Wakeup 2000;
BA_REL_ "GenSigTimeoutTime" BU_SG_REL_ Gateway_Max SG_ 2600468555 NM_TSG_BT_CAB_V14 2000;
BA_REL_ "GenSigTimeoutTime" BU_SG_REL_ Gateway_Max SG_ 2600468554 NM_TSG_FS_CBV_AWB 2000;
BA_REL_ "GenSigTimeoutTime" BU_SG_REL_ Gateway_Max SG_ 2600468554 NM_TSG_FS_CBV_CRI 2000;
BA_REL_ "GenSigTimeoutTime" BU_SG_REL_ Gateway_Max SG_ 2600468554 NM_TSG_FS_Car_Wakeup 2000;
BA_REL_ "GenSigTimeoutTime" BU_SG_REL_ Gateway_Max SG_ 2600468554 NM_TSG_FT_CAB_V14 2000;
BA_REL_ "GenSigTimeoutTime" BU_SG_REL_ Gateway_Max SG_ 2600468543 NM_TSG_HBFS_CBV_CRI 2000;
BA_REL_ "GenSigTimeoutTime" BU_SG_REL_ Gateway_Max SG_ 2600468543 NM_TSG_HBFS_Car_Wakeup 2000;
BA_REL_ "GenSigTimeoutTime" BU_SG_REL_ Gateway_Max SG_ 2600468543 NM_TSG_HBFS_CAB_V14 2000;
BA_REL_ "GenSigTimeoutTime" BU_SG_REL_ Gateway_Max SG_ 2600468542 NM_TSG_HFS_Car_Wakeup 2000;
BA_REL_ "GenSigTimeoutTime" BU_SG_REL_ Gateway_Max SG_ 2600468542 NM_TSG_HFS_CAB_V14 2000;
BA_REL_ "GenSigTimeoutTime" BU_SG_REL_ Gateway_Max SG_ 2600468645 NM_WLC1_CBV_AWB 2000;
BA_REL_ "GenSigTimeoutTime" BU_SG_REL_ Gateway_Max SG_ 2600468645 NM_WLC1_CBV_CRI 2000;
BA_REL_ "GenSigTimeoutTime" BU_SG_REL_ Gateway_Max SG_ 2600468645 NM_WLC1_Car_Wakeup 2000;
BA_REL_ "GenSigTimeoutTime" BU_SG_REL_ Gateway_Max SG_ 2600468645 NM_WLC1_CAB_V14 2000;
BA_REL_ "GenSigTimeoutTime" BU_SG_REL_ Gateway_Max SG_ 2527679741 PAO_ON_Status 2400;
BA_REL_ "GenSigTimeoutTime" BU_SG_REL_ Gateway_Max SG_ 2527679498 Perso_Kontonummer 5000;
BA_REL_ "GenSigTimeoutTime" BU_SG_REL_ Gateway_Max SG_ 2527679498 Perso_Steuerung 5000;
BA_REL_ "GenSigTimeoutTime" BU_SG_REL_ Gateway_Max SG_ 2527679498 Perso_Steuerungsparameter 5000;
BA_REL_ "GenSigTimeoutTime" BU_SG_REL_ Gateway_Max SG_ 2527679498 Perso_Status 5000;
BA_REL_ "GenSigTimeoutTime" BU_SG_REL_ Gateway_Max SG_ 2527679498 IAA_Active_User_ID 5000;
BA_REL_ "GenSigTimeoutTime" BU_SG_REL_ TSGGen3_BFS SG_ 332 OBD_Driving_Cycle 1000;
BA_REL_ "GenSigTimeoutTime" BU_SG_REL_ TSGGen3_BFS SG_ 332 OBD_Warm_Up_Cycle 1000;
BA_REL_ "GenSigTimeoutTime" BU_SG_REL_ TSGGen3_BFS SG_ 1601 MO_Hybridfahrzeug 5000;
BA_REL_ "GenSigTimeoutTime" BU_SG_REL_ TSGGen3_BFS SG_ 2600468494 NM_BCM1_NM_State 2000;
BA_REL_ "GenSigTimeoutTime" BU_SG_REL_ TSGGen3_BFS SG_ 2600468496 NM_Gateway_NM_State 2000;
BA_REL_ "GenSigTimeoutTime" BU_SG_REL_ TSGGen3_BFS SG_ 2600468554 NM_TSG_FS_NM_State 2000;
BA_REL_ "GenSigTimeoutTime" BU_SG_REL_ TSGGen3_BFS SG_ 2600468543 NM_TSG_HBFS_NM_State 2000;
BA_REL_ "GenSigTimeoutTime" BU_SG_REL_ TSGGen3_BFS SG_ 2600468542 NM_TSG_HFS_NM_State 2000;
BA_REL_ "GenSigTimeoutTime" BU_SG_REL_ TSGGen3_BFS SG_ 2600468645 NM_WLC1_NM_State 2000;
BA_REL_ "GenSigTimeoutTime" BU_SG_REL_ TSGGen3_BFS SG_ 2589283656 ORU_Status 5000;
BA_REL_ "GenSigTimeoutTime" BU_SG_REL_ TSGGen3_BFS SG_ 2527679498 Perso_Kontonummer 5000;
BA_REL_ "GenSigTimeoutTime" BU_SG_REL_ TSGGen3_BFS SG_ 2527679498 Perso_Steuerung 5000;
BA_REL_ "GenSigTimeoutTime" BU_SG_REL_ TSGGen3_BFS SG_ 2527679498 Perso_Steuerungsparameter 5000;
BA_REL_ "GenSigTimeoutTime" BU_SG_REL_ TSGGen3_BFS SG_ 2527679498 Perso_Status 5000;
BA_REL_ "GenSigTimeoutTime" BU_SG_REL_ TSGGen3_BFS SG_ 2527679498 Perso_Fahrernummer 5000;
BA_REL_ "GenSigTimeoutTime" BU_SG_REL_ TSGGen3_FS SG_ 332 OBD_Driving_Cycle 1000;
BA_REL_ "GenSigTimeoutTime" BU_SG_REL_ TSGGen3_FS SG_ 332 OBD_Warm_Up_Cycle 1000;
BA_REL_ "GenSigTimeoutTime" BU_SG_REL_ TSGGen3_FS SG_ 1601 MO_Hybridfahrzeug 5000;
BA_REL_ "GenSigTimeoutTime" BU_SG_REL_ TSGGen3_FS SG_ 2527679646 KY_Oeffnen_Betaetigung 2000;
BA_REL_ "GenSigTimeoutTime" BU_SG_REL_ TSGGen3_FS SG_ 2527679646 KY_Oeffnen_Annaeherung 2000;
BA_REL_ "GenSigTimeoutTime" BU_SG_REL_ TSGGen3_FS SG_ 2600468494 NM_BCM1_NM_State 2000;
BA_REL_ "GenSigTimeoutTime" BU_SG_REL_ TSGGen3_FS SG_ 2600468496 NM_Gateway_NM_State 2000;
BA_REL_ "GenSigTimeoutTime" BU_SG_REL_ TSGGen3_FS SG_ 2600468555 NM_TSG_BFS_NM_State 2000;
BA_REL_ "GenSigTimeoutTime" BU_SG_REL_ TSGGen3_FS SG_ 2600468543 NM_TSG_HBFS_NM_State 2000;
BA_REL_ "GenSigTimeoutTime" BU_SG_REL_ TSGGen3_FS SG_ 2600468542 NM_TSG_HFS_NM_State 2000;
BA_REL_ "GenSigTimeoutTime" BU_SG_REL_ TSGGen3_FS SG_ 2600468645 NM_WLC1_NM_State 2000;
BA_REL_ "GenSigTimeoutTime" BU_SG_REL_ TSGGen3_FS SG_ 2589283656 ORU_Status 5000;
BA_REL_ "GenSigTimeoutTime" BU_SG_REL_ TSGGen3_FS SG_ 2527679498 Perso_Kontonummer 5000;
BA_REL_ "GenSigTimeoutTime" BU_SG_REL_ TSGGen3_FS SG_ 2527679498 Perso_Steuerung 5000;
BA_REL_ "GenSigTimeoutTime" BU_SG_REL_ TSGGen3_FS SG_ 2527679498 Perso_Steuerungsparameter 5000;
BA_REL_ "GenSigTimeoutTime" BU_SG_REL_ TSGGen3_FS SG_ 2527679498 Perso_Status 5000;
BA_REL_ "GenSigTimeoutTime" BU_SG_REL_ TSGGen3_FS SG_ 2527679498 Perso_Fahrernummer 5000;
BA_REL_ "GenSigTimeoutTime" BU_SG_REL_ TSGGen3_HBFS SG_ 332 OBD_Driving_Cycle 1000;
BA_REL_ "GenSigTimeoutTime" BU_SG_REL_ TSGGen3_HBFS SG_ 332 OBD_Warm_Up_Cycle 1000;
BA_REL_ "GenSigTimeoutTime" BU_SG_REL_ TSGGen3_HBFS SG_ 1601 MO_Hybridfahrzeug 5000;
BA_REL_ "GenSigTimeoutTime" BU_SG_REL_ TSGGen3_HBFS SG_ 2600468494 NM_BCM1_NM_State 2000;
BA_REL_ "GenSigTimeoutTime" BU_SG_REL_ TSGGen3_HBFS SG_ 2600468496 NM_Gateway_NM_State 2000;
BA_REL_ "GenSigTimeoutTime" BU_SG_REL_ TSGGen3_HBFS SG_ 2600468555 NM_TSG_BFS_NM_State 2000;
BA_REL_ "GenSigTimeoutTime" BU_SG_REL_ TSGGen3_HBFS SG_ 2600468554 NM_TSG_FS_NM_State 2000;
BA_REL_ "GenSigTimeoutTime" BU_SG_REL_ TSGGen3_HBFS SG_ 2600468542 NM_TSG_HFS_NM_State 2000;
BA_REL_ "GenSigTimeoutTime" BU_SG_REL_ TSGGen3_HBFS SG_ 2600468645 NM_WLC1_NM_State 2000;
BA_REL_ "GenSigTimeoutTime" BU_SG_REL_ TSGGen3_HBFS SG_ 2589283656 ORU_Status 5000;
BA_REL_ "GenSigTimeoutTime" BU_SG_REL_ TSGGen3_HBFS SG_ 2527679498 Perso_Kontonummer 5000;
BA_REL_ "GenSigTimeoutTime" BU_SG_REL_ TSGGen3_HBFS SG_ 2527679498 Perso_Steuerung 5000;
BA_REL_ "GenSigTimeoutTime" BU_SG_REL_ TSGGen3_HBFS SG_ 2527679498 Perso_Steuerungsparameter 5000;
BA_REL_ "GenSigTimeoutTime" BU_SG_REL_ TSGGen3_HBFS SG_ 2527679498 Perso_Status 5000;
BA_REL_ "GenSigTimeoutTime" BU_SG_REL_ TSGGen3_HBFS SG_ 2527679498 Perso_Fahrernummer 5000;
BA_REL_ "GenSigTimeoutTime" BU_SG_REL_ TSGGen3_HFS SG_ 332 OBD_Driving_Cycle 1000;
BA_REL_ "GenSigTimeoutTime" BU_SG_REL_ TSGGen3_HFS SG_ 332 OBD_Warm_Up_Cycle 1000;
BA_REL_ "GenSigTimeoutTime" BU_SG_REL_ TSGGen3_HFS SG_ 1601 MO_Hybridfahrzeug 5000;
BA_REL_ "GenSigTimeoutTime" BU_SG_REL_ TSGGen3_HFS SG_ 2600468494 NM_BCM1_NM_State 2000;
BA_REL_ "GenSigTimeoutTime" BU_SG_REL_ TSGGen3_HFS SG_ 2600468496 NM_Gateway_NM_State 2000;
BA_REL_ "GenSigTimeoutTime" BU_SG_REL_ TSGGen3_HFS SG_ 2600468555 NM_TSG_BFS_NM_State 2000;
BA_REL_ "GenSigTimeoutTime" BU_SG_REL_ TSGGen3_HFS SG_ 2600468554 NM_TSG_FS_NM_State 2000;
BA_REL_ "GenSigTimeoutTime" BU_SG_REL_ TSGGen3_HFS SG_ 2600468543 NM_TSG_HBFS_NM_State 2000;
BA_REL_ "GenSigTimeoutTime" BU_SG_REL_ TSGGen3_HFS SG_ 2600468645 NM_WLC1_NM_State 2000;
BA_REL_ "GenSigTimeoutTime" BU_SG_REL_ TSGGen3_HFS SG_ 2589283656 ORU_Status 5000;
BA_REL_ "GenSigTimeoutTime" BU_SG_REL_ TSGGen3_HFS SG_ 2527679498 Perso_Kontonummer 5000;
BA_REL_ "GenSigTimeoutTime" BU_SG_REL_ TSGGen3_HFS SG_ 2527679498 Perso_Steuerung 5000;
BA_REL_ "GenSigTimeoutTime" BU_SG_REL_ TSGGen3_HFS SG_ 2527679498 Perso_Steuerungsparameter 5000;
BA_REL_ "GenSigTimeoutTime" BU_SG_REL_ TSGGen3_HFS SG_ 2527679498 Perso_Status 5000;
BA_REL_ "GenSigTimeoutTime" BU_SG_REL_ TSGGen3_HFS SG_ 2527679498 Perso_Fahrernummer 5000;
BA_REL_ "GenSigTimeoutTime" BU_SG_REL_ WLC_01_CFD SG_ 332 OBD_Driving_Cycle 1000;
BA_REL_ "GenSigTimeoutTime" BU_SG_REL_ WLC_01_CFD SG_ 332 OBD_Warm_Up_Cycle 1000;
BA_REL_ "GenSigTimeoutTime" BU_SG_REL_ WLC_01_CFD SG_ 2600468494 NM_BCM1_NM_State 2000;
BA_REL_ "GenSigTimeoutTime" BU_SG_REL_ WLC_01_CFD SG_ 2600468496 NM_Gateway_NM_State 2000;
BA_REL_ "GenSigTimeoutTime" BU_SG_REL_ WLC_01_CFD SG_ 2600468555 NM_TSG_BFS_NM_State 2000;
BA_REL_ "GenSigTimeoutTime" BU_SG_REL_ WLC_01_CFD SG_ 2600468554 NM_TSG_FS_NM_State 2000;
BA_REL_ "GenSigTimeoutTime" BU_SG_REL_ WLC_01_CFD SG_ 2600468543 NM_TSG_HBFS_NM_State 2000;
BA_REL_ "GenSigTimeoutTime" BU_SG_REL_ WLC_01_CFD SG_ 2600468542 NM_TSG_HFS_NM_State 2000;
VAL_ 332 MO_Anforderung_HMS 0 "keine_Anforderung" 1 "halten" 2 "parken" 3 "halten_Standby" 4 "anfahren" 5 "Loesen_ueber_Rampe" 7 "HMS_uebernehmen" ;
VAL_ 332 FoD_DTC_TSK_GRA 0 "Kein_DTC" 1 "DTC_vorhanden_oder_in_Quali" ;
VAL_ 332 TSK_vMax_aktuell 254 "kein_Limit_aktiv" 255 "Init" ;
VAL_ 332 ISA_Status 0 "ISA_nicht_aktiv" 1 "Init" 2 "ISA_degradiert" 3 "ISA_aktiv" 4 "reserviert" 5 "reserviert" 6 "reserviert" 7 "reserviert" ;
VAL_ 332 ISA_Regelung_aktiv 0 "ISA_Regelung_nicht_aktiv" 1 "ISA_Regelung_aktiv" ;
VAL_ 332 ISA_Tempolimitwarnung 0 "ISA_keine_Warnung" 1 "ISA_Warnung_aktiv" ;
VAL_ 332 MO_Red_El_Fahrleistung 0 "keine_Anzeige" 1 "mehr_als_20Prcnt_Red" 2 "Reserve_1" 3 "Reserve_2" 4 "unter_GBB_Schwelle_Anhaenger" 5 "unter_GBB_Schwelle" 6 "unter_minimal_Schwelle" 7 "kein_Vortrieb" ;
VAL_ 332 TSK_Status_EA 0 "Aus" 1 "Init_oder_nicht_verbaut" 3 "Aktiv" 4 "Uebertreten" 5 "Abschaltung_laeuft" 6 "Reversibel_aus" 7 "Fehler" ;
VAL_ 332 FoD_DTC_TSK_ACC 0 "Kein_DTC" 1 "DTC_vorhanden_oder_in_Quali" ;
VAL_ 332 TSK_ACC_FoD_Status 0 "default" 1 "nicht_aktiv" 2 "aktiv" 3 "nicht_genutzt" ;
VAL_ 332 TSK_GRA_FoD_Status 0 "default" 1 "nicht_aktiv" 2 "aktiv" 3 "nicht_genutzt" ;
VAL_ 332 TSK_vMax_Fahrerassistenz 511 "Init_ungueltig_keine_Beschraenkung" ;
VAL_ 332 TSK_Einheit_vMax_Fahrerassistenz 0 "kmh" 1 "mph" ;
VAL_ 332 TSK_Status_PLA 0 "Aus_Funktionsbereit" 1 "Init_oder_nicht_verbaut" 2 "aktivierbar" 3 "aktiv" 5 "Abschaltung_laeuft" 6 "reversibel_aus" 7 "Fehler" ;
VAL_ 332 TSK_aktives_System 0 "keine_Funktion_aktiv" 1 "GRA_ACC" 2 "ARA" 3 "Speedlimiter" 4 "IPA" 5 "PLA" 6 "PEA_Ausrollassistent" 7 "EA" ;
VAL_ 332 TSK_erhoehter_Fahrwiderstand 0 "kein_erhoehter_Fahrwiderstand" 1 "erhoehter_Fahrwiderstand" ;
VAL_ 332 TSK_Anf_Antriebsmoment 0 "keine_Anforderung" 1 "Anforderung_aktiv" ;
VAL_ 332 TSK_Status_ARA 0 "Aus" 1 "Init_oder_nicht_verbaut" 2 "aktivierbar" 3 "aktiv" 5 "abschaltung_laeuft" 6 "reversibel_aus" 7 "Fehler" ;
VAL_ 332 TSK_Status_IPA 0 "Aus_Funktionsbereit" 1 "Init_oder_nicht_verbaut" 2 "aktivierbar" 3 "aktiv" 4 "Fahreruebernahme_angefordert" 5 "Abschaltung_laueft" 6 "reversibel_aus" 7 "Fehler" ;
VAL_ 332 TSK_aktives_System_02 0 "keine_Funktion_aktiv" 1 "GRA_ACC" 2 "ARA" 3 "Speedlimiter" 4 "IPA" 5 "PLA" 6 "PEA_Ausrollassistent" 7 "EA" 8 "Staupilot" 9 "RHP" ;
VAL_ 332 TSK_Status_RHP 0 "off" 1 "init" 2 "standby" 3 "active" 4 "driver_override" 5 "shutdown" 6 "reversible_failure" 7 "irreversible_failure" ;
VAL_ 332 MO_Kuppl_betaetigt 0 "Kupplung_nicht_betaetigt" 1 "Kupplung_betaetigt" ;
VAL_ 332 MO_QBit_Kuppl_betaetigt 0 "gueltiger_Wert" 1 "Ersatz_Init_oder_Fehlerwert" ;
VAL_ 332 MO_Klima_Regelmodus 0 "Init" 1 "Regelmodus_1" 2 "Regelmodus_2" 3 "Regelmodus_3" ;
VAL_ 332 MO_Fahrbereitschaft 0 "Fahrzykl_inaktiv__kein_Antrieb" 1 "Fahrzykl_aktiv__kein_Antrieb" 2 "Fahrzykl_aktiv__Antrieb_moeglich" ;
VAL_ 332 MO_Freilauf_Info 0 "Freilauf_freigegeben" 1 "Weiches_Veto_uebertippbar" 2 "Hartes_Veto_Abbruch" 3 "Freilauf_Anforderung" ;
VAL_ 332 CE_FlgLnchCtlPreCnd 0 "not_fulfilled" 1 "fulfilled" ;
VAL_ 332 MO_Krit_Heckobjekt 0 "Init_kein_relevantes_Objekt" 1 "Entfernung_grosser_Abstand" 2 "Annaeherung_grosser_Abstand" 3 "Entfernung_geringer_Abstand" 4 "Annaeherung_geringer_Abstand" 7 "Fehler" ;
VAL_ 332 MO_NGS_Gangpos 0 "nicht_bedient" 1 "1_3_oder_5" 2 "2_4_6_oder_R" 3 "R" 4 "Neutralposition" 5 "Zwischenposition" 6 "Sensor_temp_nicht_verfuegbar" 7 "Fehler" ;
VAL_ 332 MO_Freilauf_Status 0 "Freilauf_inaktiv_aber_moeglich" 1 "Freilauf_aktiv" 2 "Freilauf_nicht_moegl_1Verhinderer" 3 "Freilauf_nicht_moegl_gr_1Verhinderer" 7 "Fehler" ;
VAL_ 332 MO_EBoost_verf_praed 0 "Init_oder_nicht_verfuegbar" 1 "EBoost_kurzzeit_verfuegbar" 2 "EBoost_langzeit_verfuegbar" ;
VAL_ 332 MO_Heckspoiler_Anf 0 "nicht_angefordert" 1 "angefordert" ;
VAL_ 332 MO_eLaunch_verf 0 "Init" 1 "nicht_verfuegbar" 2 "verfuegbar" ;
VAL_ 332 MO_Positionierung_aktiv 0 "keine_Positionierung_aktiv" 1 "Positionierung_aktiv" ;
VAL_ 332 MO_Veto_Launchcontrol 0 "kein_Veto__LC_moeglich" 1 "Veto__LC_nicht_moeglich" ;
VAL_ 332 MO_Startwunsch 0 "kein_Startwunsch" 1 "Startwunsch" ;
VAL_ 332 MO_LaunchControl 0 "nicht_verfuegbar" 1 "verfuegbar" ;
VAL_ 332 MO_UBE_Hybrid_Reserve 1023 "Init" ;
VAL_ 332 OBDProtocol_req 0 "OBDonUDS" 1 "OBDclassic" 254 "Init" 255 "Fehler" ;
VAL_ 332 MO_Servicemodus 0 "nicht_aktiv" 1 "Service_Mode_1" 2 "Service_Mode_2" 3 "Service_Mode_3" 4 "Service_Mode_4" 5 "Service_Mode_5" 6 "Service_Mode_6" 7 "Service_Mode_7" 8 "Service_Mode_8" 9 "Service_Mode_9" 10 "Service_Mode_10" 11 "Service_Mode_11" 12 "Service_Mode_12" 13 "Service_Mode_13" 14 "Service_Mode_14" 15 "Service_Mode_15" ;
VAL_ 332 OBD_ClearMem_Inhibit 0 "FSP_Loeschen_zulaessig" 1 "FSP_Loeschen_nicht_zulaessig" ;
VAL_ 332 OBD_Sperrung_Kaltstart_Denom 0 "EVAP_Berechnung_freigegeben" 1 "EVAP_Berechnung_gesperrt" ;
VAL_ 332 MO_QBit_Aussen_Temp 0 "gueltiger_Wert" 1 "Ersatz_Init_oder_Fehlerwert" ;
VAL_ 332 OBD_Sperrung_IUMPR 0 "IUMPR_Berechnung_freigegeben" 1 "IUMPR_Berechnung_gesperrt" ;
VAL_ 332 OBD_Kaltstart_Denominator 0 "Denominator_nicht_hochzaehlen" 1 "Bedingungen_zum_Inkr_des_Kaltstart_Denom_erf" ;
VAL_ 332 OBD_Minimum_Trip 0 "kein_Min_Normed_Trip" 1 "Min_Normed_Trip" ;
VAL_ 332 OBD_Driving_Cycle 0 "kein_Driving_Cycle_erkannt" 1 "Driving_Cycle_erkannt" ;
VAL_ 332 OBD_Warm_Up_Cycle 0 "kein_Warm_Up_Cycle_erkannt" 1 "Warm_Up_Cycle_erkannt" ;
VAL_ 332 OBD_Normed_Trip 0 "kein_Normed_Trip" 1 "Normed_Trip" ;
VAL_ 332 MO_EMG_Min_Leistung 2046 "Init" 2047 "Fehler" ;
VAL_ 332 MO_EMG_Max_Leistung 2046 "Init" 2047 "Fehler" ;
VAL_ 332 MO_MVEM_MinLeistung_MVVerbrauch 1022 "Init" 1023 "Fehler" ;
VAL_ 332 MO_MVEM_MaxLeistung_MVVerbrauch 1022 "Init" 1023 "Fehler" ;
VAL_ 332 MO_UBE_Reserve 1023 "Init" ;
VAL_ 332 OBD_Aussen_Temp_gef 254 "Initwert" 255 "Fehler" ;
VAL_ 1601 MO_Faktor_Momente_02 0 "nicht_belegt" ;
VAL_ 1601 MO_Hybridfahrzeug 0 "kein_Hybridfahrzeug" 1 "Mild_Hybrid" 2 "Full_Hybrid" 3 "PlugIn_Hybrid" ;
VAL_ 1601 MO_Getriebe_Code 0 "Init" 2 "DL501" 3 "DL800" 4 "VL381" 5 "DL382_Front" 6 "DL382_Allrad" 7 "DL702" 8 "AL552_Allrad" 9 "AL552_Front" 10 "AL651" 11 "AL551__AL951__AL1000_8A" 12 "PDK_PAG" 13 "AL551_Hybrid" 15 "Handschalter_konventionell" 16 "AQ250_160" 17 "AQ450" 18 "DQ200" 19 "DQ250" 20 "DQ500" 21 "SQ100" 22 "SQ200" 23 "DQ400E" 24 "DQ381" 25 "AL550" 26 "AQ300" 31 "DL800E" 32 "Single_Gear__ohne_GSG_WH_am_MSG" 33 "EQ550_2P" ;
VAL_ 1601 MO_StartStopp_Codiert 0 "Start_Stopp_nicht_verbaut" 1 "Start_Stopp_verbaut" ;
VAL_ 1601 MO_Anzeige_StSt_gueltig 0 "MO_Text_Motorstart_gueltig" 1 "Signale_MO_Anzeige_StSt_gueltig" ;
VAL_ 1601 MO_Anzahl_Zyl 0 "kein_Zylinder" 1 "1_Zylinder" 2 "2_Zylinder" 3 "3_Zylinder" 4 "4_Zylinder" 5 "5_Zylinder" 6 "6_Zylinder" 7 "7_Zylinder" 8 "8_Zylinder" 9 "9_Zylinder" 10 "10_Zylinder" 11 "11_Zylinder" 12 "12_Zylinder" 13 "15_Zylinder" 14 "16_Zylinder" 15 "18_Zylinder" ;
VAL_ 1601 MO_Kraftstoffart 0 "Diesel" 1 "Benzin_inkl_E25_E85" 2 "CNG" 3 "LPG" 4 "Wasserstoff" 5 "E100_Ethanol" 15 "kein_Verbrennungskraftstoff" ;
VAL_ 1601 MO_Ansaugsystem 0 "Turbo" 1 "Sauger" ;
VAL_ 1601 MO_OBD_Typ 0 "NoOBD_RdW" 1 "EOBD" 2 "US_OBD" 3 "reserviert" ;
VAL_ 1601 MO_DPF_verbaut 0 "kein_DPF_verbaut" 1 "DPF_verbaut" ;
VAL_ 1601 TSK_Codierung 0 "kein_Fahrgeschwindigkeitsregler" 1 "GRA" 2 "GRA_Plus" 3 "Basis_ACC" 4 "ACC_Follow_to_Stop" 5 "ACC_Stop_and_Go" 7 "Codierung_in_Plausibilisierungsphase" ;
VAL_ 391 EV_Rekuperationsstufe 0 "keine_Anzeige" 1 "1" 2 "2" 3 "3" 4 "4" 5 "5" ;
VAL_ 391 MO_Waehlpos 0 "Init_nicht_unterstuetzt" 1 "reserviert" 2 "P" 3 "R" 4 "N" 5 "D" 6 "B" 7 "Fehler" ;
VAL_ 391 MO_Fehler_NTKreis 0 "kein_Fehler" 1 "Fehler" ;
VAL_ 391 MO_Fehler_Notabschaltung_Klima 0 "Init" 1 "HVIL_ist_OK" 2 "HVIL_Fehler" 3 "ohne_Funktion" ;
VAL_ 391 MO_KLE_FStatus 0 "kein_Fehler" 2 "Fehlerentprellung" 3 "Fehler" ;
VAL_ 391 MO_WH_Texte 0 "keine_Anzeige" 1 "ShiftLock__Fussbremse_betaetigen" 3 "Wegrollgefahr_bitte_P_einlegen" 4 "Parksperre_Warnstufe_I" 5 "Parksperre_Warnstufe_II" 6 "P_nur_im_Stillstand_moeglich" ;
VAL_ 391 MO_Tankbereitschaft_Status 0 "keine_Aktion_Init" 1 "Tankbereitschaft_wird_hergestellt" 2 "Tankbereitschaft_ist_hergestellt" 3 "Tankbereitschaft_kann_nicht_hergestellt_werden" 4 "Tanksystem_Systemfehler" 5 "Tankklappe_pruefen_schliessen" 6 "Tankvorgang_abgebrochen" ;
VAL_ 391 MO_Tankklappensteuerung 0 "Init_nicht_verbaut" 1 "Tankklappe_soll_entriegeln" 2 "Tankklappe_soll_verriegeln" 3 "keine_Aktion" ;
VAL_ 2527679770 NavMan_MainType 0 "NoSymbol" 1 "NoInfo" 2 "DirectionToDestination" 3 "Arrived" 4 "NearDestination" 5 "ArrivedDestinationOffmap" 6 "OffRoad" 7 "OffMap" 8 "NoRoute" 9 "CalcRoute" 10 "RecalcRoute" 11 "FollowStreet" 12 "ChangeLane" 13 "Turn" 14 "TurnOnMainroad" 15 "ExitRight" 16 "ExitLeft" 17 "ServiceRoadRight" 18 "ServiceRoadLeft" 19 "Fork_2" 20 "Fork_3" 21 "RoundaboutTrsRight" 22 "RoundaboutTrsLeft" 23 "SquareTrsRight" 24 "SquareTrsLeft" 25 "Uturn" 26 "ExitRoudaboutTrsRight" 27 "ExitRoudaboutTrsLeft" 28 "PrepareTurn" 29 "PrepareRoundabout" 30 "PrepareSquare" 31 "PrepareUTurn" 32 "reserved_ExitRight_RampUp" 33 "reserved_ExitRight_RampDown" 34 "MichigangTurn" 35 "DoubleTurn" 36 "reserved_ExitLeft_RampUp" 37 "reserved_ExitLeft_RampDown" 38 "DirectionToWaypoint" 39 "reserved" 63 "reserved" ;
VAL_ 2527679770 NavMan_Distance_Unit 0 "meter" 1 "kilometer" 2 "yard" 3 "feet" 4 "mile_UK_and_US_statute_mile" 5 "quarter_mile" 6 "reserved" 7 "Init" ;
VAL_ 2527679770 NavMan_ApproachDistanceInPercent 101 "reserved" 125 "reserved" 126 "Init" ;
VAL_ 2527679645 NFC_MiKo_Fehler 0 "SG_iO" 1 "SG_defekt" 2 "Antenne_defekt" 4 "Unterspannung" 8 "Ueberspannung" 16 "Ueberhitzung" ;
VAL_ 2527679645 NFC_MiKo_NFC_Device_Status 0 "Init_nicht_erkannt" 1 "NFC_Device_erkannt" 2 "MDK_Framework_erkannt" 3 "MDK_Applet_erkannt" 4 "MDK_Servicekarte_erkannt" 5 "MDK_Device_authentifiziert" ;
VAL_ 2527679645 NFC_MiKo_NFC_Device_gekoppelt 0 "Init_kein_NFC_Device_gekoppelt" 1 "NFC_Device_gekoppelt" ;
VAL_ 2527679645 NFC_MiKo_Laden_unterbrechen 0 "Init_keine_Unterbrechung" 1 "Laden_unterbrechen" ;
VAL_ 2527679645 NFC_MiKo_ESM_aktiv 0 "Init_kein_ESM" 1 "ESM_aktiv" ;
VAL_ 2527679646 NFC_TGS_NFC_Device_Status 0 "Init_nicht_erkannt" 1 "NFC_Device_erkannt" 2 "MDK_Framework_erkannt" 3 "MDK_Applet_erkannt" 4 "MDK_Servicekarte_erkannt" 5 "MDK_Device_authentifiziert" ;
VAL_ 2527679646 NFC_TGS_Licht_Fehler 0 "Init" 1 "elektrischer_Fehler" 2 "Unterspannung_LED" 4 "Ueberspannung_LED" 8 "Ueberhitzung_LED" ;
VAL_ 2527679646 NFC_TGS_Fehler 0 "SG_iO" 1 "SG_defekt" 2 "Antenne_defekt" 4 "Unterspannung" 8 "Ueberspannung" 16 "Ueberhitzung" ;
VAL_ 2527679646 KY_Schliessen_Betaetigung 0 "Init_keine_Annaeherung" 1 "Betaetigung_Schliessen_erkannt" ;
VAL_ 2527679646 KY_Schliessen_Annaeherung 0 "Init_keine_Annaeherung" 1 "Annaeherung_Schliessen_erkannt" ;
VAL_ 2527679646 KY_Oeffnen_Betaetigung 0 "Init_keine_Annaeherung" 1 "Betaetigung_Oeffnen_erkannt" ;
VAL_ 2527679646 KY_Oeffnen_Annaeherung 0 "Init_keine_Annaeherung" 1 "Annaeherung_Oeffnen_erkannt" ;
VAL_ 2527679646 NFC_TGS_NFC_Device_gekoppelt 0 "Init_kein_NFC_Device_gekoppelt" 1 "NFC_Device_gekoppelt" ;
VAL_ 2527679646 NFC_TGS_ESM_aktiv 0 "Init_kein_ESM" 1 "ESM_aktiv" ;
VAL_ 2600468494 NM_BCM1_CBV_AWB 0 "Passiver_WakeUp" 1 "Aktiver_WakeUp" ;
VAL_ 2600468494 NM_BCM1_CBV_CRI 0 "NM_ohne_Clusteranforderungen" 1 "NM_mit_Clusteranforderungen" ;
VAL_ 2600468494 NM_BCM1_NM_State 0 "Init" 1 "NM_RM_aus_BSM" 2 "NM_RM_aus_PBSM" 4 "NM_NO_aus_RM" 8 "NM_NO_aus_RS" 16 "reserved" 32 "reserved" ;
VAL_ 2600468494 NM_BCM1_Car_Wakeup 0 "Inaktiv" 1 "Car_Wakeup" ;
VAL_ 2600468494 NM_BCM1_UDS_CC 0 "Inaktiv" 1 "CC_aktiv" ;
VAL_ 2600468494 NM_BCM1_NM_aktiv_KL15 0 "Inaktiv" 1 "KL15_EIN" ;
VAL_ 2600468494 NM_BCM1_NM_aktiv_Diagnose 0 "Init" 1 "Diagnose_aktiv" ;
VAL_ 2600468494 NM_BCM1_NM_aktiv_Tmin 0 "Inaktiv" 1 "Mindestaktivzeit" ;
VAL_ 2600468494 NM_BCM1_NM_aktiv_Aussenlicht 0 "Init" 1 "Aussenlicht_aktiv" ;
VAL_ 2600468494 NM_BCM1_NM_aktiv_ZV 0 "Init" 1 "ZV_aktiv" ;
VAL_ 2600468494 NM_BCM1_NM_aktiv_Heizung 0 "Init" 1 "Heizung_aktiv" ;
VAL_ 2600468494 NM_BCM1_NM_aktiv_Innenlicht 0 "Init" 1 "Innenlicht_aktiv" ;
VAL_ 2600468494 NM_BCM1_NM_aktiv_DWA 0 "Init" 1 "DWA_aktiv" ;
VAL_ 2600468494 NM_BCM1_NM_aktiv_Funk 0 "Init" 1 "Funk_aktiv" ;
VAL_ 2600468494 NM_BCM1_NM_aktiv_Kessy 0 "Init" 1 "Kessy_Komm_aktiv" ;
VAL_ 2600468494 NM_BCM1_NM_aktiv_TK_geschlossen 0 "Init" 1 "TK_geschlossen_aktiv" ;
VAL_ 2600468494 NM_BCM1_NM_aktiv_Applikation 1 "Applikationsanforderung_CAN" ;
VAL_ 2600468494 NM_BCM1_NM_aktiv_Remotestart 0 "Init" 1 "Remotestart_aktiv" ;
VAL_ 2600468494 NM_BCM1_NM_aktiv_Remot_Door_L_Un 0 "Inaktiv" 1 "Remote_Door_Lock_Unlock_aktiv" ;
VAL_ 2600468494 NM_BCM1_NM_aktiv_VLW 0 "Init" 1 "VLW_aktiv" ;
VAL_ 2600468494 NM_BCM1_CAB_V14 0 "Init" 1 "CAB_01_Antrieb" 2 "CAB_02_Hybrid_Laden" 4 "CAB_03_Fahrwerk" 8 "CAB_04_Fahrerassistenz" 16 "CAB_05_Komfort" 32 "CAB_06_Anzeige" 64 "CAB_07_Connect" 128 "CAB_08_MIB" 256 "CAB_09_Standheizung" 1024 "CAB_11_VLAN_Fahrerassistenz" 2048 "CAB_12_VLAN_Komfort" 4096 "CAB_13_VLAN_Connect" 8192 "CAB_14_VLAN_Infotainment" 16384 "CAB_15_Laden" 32768 "CAB_16_Licht" ;
VAL_ 2600468496 NM_Gateway_CBV_AWB 0 "Passiver_WakeUp" 1 "Aktiver_WakeUp" ;
VAL_ 2600468496 NM_Gateway_CBV_CRI 0 "NM_ohne_Clusteranforderungen" 1 "NM_mit_Clusteranforderungen" ;
VAL_ 2600468496 NM_Gateway_NM_State 0 "Init" 1 "NM_RM_aus_BSM" 2 "NM_RM_aus_PBSM" 4 "NM_NO_aus_RM" 8 "NM_NO_aus_RS" 16 "reserved" 32 "reserved" ;
VAL_ 2600468496 NM_Gateway_Car_Wakeup 0 "Inaktiv" 1 "Car_Wakeup" ;
VAL_ 2600468496 NM_Gateway_UDS_CC 0 "Inaktiv" 1 "CC_aktiv" ;
VAL_ 2600468496 NM_Gateway_NM_aktiv_KL15 0 "Inaktiv" 1 "KL15_EIN" ;
VAL_ 2600468496 NM_Gateway_NM_aktiv_Diagnose 0 "Init" 1 "Diagnose_aktiv" ;
VAL_ 2600468496 NM_Gateway_NM_aktiv_Tmin 0 "Inaktiv" 1 "Mindestaktivzeit" ;
VAL_ 2600468496 NM_Gateway_NM_aktiv_CWU 0 "kein_CWU_gesetzt" 1 "CWU_gesetzt" ;
VAL_ 2600468496 NM_Gateway_NM_aktiv_FC 0 "kein_FC_gesetzt" 1 "FC_gesetzt" ;
VAL_ 2600468496 NM_Gateway_NM_aktiv_EM 0 "inaktiv" 1 "Nachlauf_aufgrund_Energiemanagement" ;
VAL_ 2600468496 NM_Gateway_NM_aktiv_Buskopplung 0 "inaktiv" 1 "Nachlauf_aufgrund_Buskopplung" ;
VAL_ 2600468496 NM_Gateway_CAB_V14 0 "Init" 1 "CAB_01_Antrieb" 2 "CAB_02_Hybrid_Laden" 4 "CAB_03_Fahrwerk" 8 "CAB_04_Fahrerassistenz" 16 "CAB_05_Komfort" 32 "CAB_06_Anzeige" 64 "CAB_07_Connect" 128 "CAB_08_MIB" 256 "CAB_09_Standheizung" 1024 "CAB_11_VLAN_Fahrerassistenz" 2048 "CAB_12_VLAN_Komfort" 4096 "CAB_13_VLAN_Connect" 8192 "CAB_14_VLAN_Infotainment" 16384 "CAB_15_Laden" 32768 "CAB_16_Licht" ;
VAL_ 2600468555 NM_TSG_BFS_CBV_AWB 0 "Passiver_WakeUp" 1 "Aktiver_WakeUp" ;
VAL_ 2600468555 NM_TSG_BFS_CBV_CRI 0 "Standard_Layout" 1 "TNB_Layout" ;
VAL_ 2600468555 NM_TSG_BFS_NM_State 0 "Init" 1 "NM_RM_aus_BSM" 2 "NM_RM_aus_PBSM" 4 "NM_NO_aus_RM" 8 "NM_NO_aus_RS" 16 "NM_RM_aus_RS" 32 "NM_RM_aus_NO" ;
VAL_ 2600468555 NM_TSG_BFS_Car_Wakeup 0 "Inaktiv" 1 "Car_Wakeup" ;
VAL_ 2600468555 NM_TSG_BFS_UDS_CC 0 "Init" 1 "CC_aktiv" ;
VAL_ 2600468555 NM_TSG_BFS_NM_aktiv_KL15 0 "Inaktiv" 1 "KL15_EIN" ;
VAL_ 2600468555 NM_TSG_BFS_NM_aktiv_Diagnose 0 "Init" 1 "Diagnose_aktiv" ;
VAL_ 2600468555 NM_TSG_BFS_NM_aktiv_Tmin 0 "Inaktiv" 1 "Mindestaktivzeit" ;
VAL_ 2600468555 NM_TSG_BFS_NM_aktiv_Taster 1 "Taster_betaetigt" ;
VAL_ 2600468555 NM_TSG_BFS_NM_aktiv_LIN 1 "LIN_aktiv" ;
VAL_ 2600468555 NM_TSG_BT_CAB_V14 0 "Init" 1 "CAB_01_Antrieb" 2 "CAB_02_Hybrid_Laden" 4 "CAB_03_Fahrwerk" 8 "CAB_04_Fahrerassistenz" 16 "CAB_05_Komfort" 32 "CAB_06_Anzeige" 64 "CAB_07_Connect" 128 "CAB_08_MIB" 256 "CAB_09_Standheizung" 1024 "CAB_11_VLAN_Fahrerassistenz" 2048 "CAB_12_VLAN_Komfort" 4096 "CAB_13_VLAN_Connect" 8192 "CAB_14_VLAN_Infotainment" 16384 "CAB_15_Laden" 32768 "CAB_16_Licht" ;
VAL_ 2600468554 NM_TSG_FS_CBV_AWB 0 "Passiver_WakeUp" 1 "Aktiver_WakeUp" ;
VAL_ 2600468554 NM_TSG_FS_CBV_CRI 0 "Standard_Layout" 1 "TNB_Layout" ;
VAL_ 2600468554 NM_TSG_FS_NM_State 0 "Init" 1 "NM_RM_aus_BSM" 2 "NM_RM_aus_PBSM" 4 "NM_NO_aus_RM" 8 "NM_NO_aus_RS" 16 "NM_RM_aus_RS" 32 "NM_RM_aus_NO" ;
VAL_ 2600468554 NM_TSG_FS_Car_Wakeup 0 "Inaktiv" 1 "Car_Wakeup" ;
VAL_ 2600468554 NM_TSG_FS_UDS_CC 0 "Init" 1 "CC_aktiv" ;
VAL_ 2600468554 NM_TSG_FS_NM_aktiv_KL15 0 "Inaktiv" 1 "KL15_EIN" ;
VAL_ 2600468554 NM_TSG_FS_NM_aktiv_Diagnose 0 "Init" 1 "Diagnose_aktiv" ;
VAL_ 2600468554 NM_TSG_FS_NM_aktiv_Tmin 0 "Inaktiv" 1 "Mindestaktivzeit" ;
VAL_ 2600468554 NM_TSG_FS_NM_aktiv_Taster 1 "Taster_betaetigt" ;
VAL_ 2600468554 NM_TSG_FS_NM_aktiv_LIN 1 "LIN_aktiv" ;
VAL_ 2600468554 NM_TSG_FT_CAB_V14 0 "Init" 1 "CAB_01_Antrieb" 2 "CAB_02_Hybrid_Laden" 4 "CAB_03_Fahrwerk" 8 "CAB_04_Fahrerassistenz" 16 "CAB_05_Komfort" 32 "CAB_06_Anzeige" 64 "CAB_07_Connect" 128 "CAB_08_MIB" 256 "CAB_09_Standheizung" 1024 "CAB_11_VLAN_Fahrerassistenz" 2048 "CAB_12_VLAN_Komfort" 4096 "CAB_13_VLAN_Connect" 8192 "CAB_14_VLAN_Infotainment" 16384 "CAB_15_Laden" 32768 "CAB_16_Licht" ;
VAL_ 2600468543 NM_TSG_HBFS_CBV_AWB 0 "Passiver_WakeUp" 1 "Aktiver_WakeUp" ;
VAL_ 2600468543 NM_TSG_HBFS_CBV_CRI 0 "NM_ohne_Clusteranforderungen" 1 "NM_mit_Clusteranforderungen" ;
VAL_ 2600468543 NM_TSG_HBFS_NM_State 0 "Init" 1 "NM_RM_aus_BSM" 2 "NM_RM_aus_PBSM" 4 "NM_NO_aus_RM" 8 "NM_NO_aus_RS" 16 "reserved" 32 "reserved" ;
VAL_ 2600468543 NM_TSG_HBFS_Car_Wakeup 0 "Inaktiv" 1 "Car_Wakeup" ;
VAL_ 2600468543 NM_TSG_HBFS_UDS_CC 0 "Inaktiv" 1 "CC_aktiv" ;
VAL_ 2600468543 NM_TSG_HBFS_NM_aktiv_KL15 0 "Inaktiv" 1 "KL15_EIN" ;
VAL_ 2600468543 NM_TSG_HBFS_NM_aktiv_Diagnose 0 "Init" 1 "Diagnose_aktiv" ;
VAL_ 2600468543 NM_TSG_HBFS_NM_aktiv_Tmin 0 "Inaktiv" 1 "Mindestaktivzeit" ;
VAL_ 2600468543 NM_TSG_HBFS_CAB_V14 0 "Init" 1 "CAB_01_Antrieb" 2 "CAB_02_Hybrid_Laden" 4 "CAB_03_Fahrwerk" 8 "CAB_04_Fahrerassistenz" 16 "CAB_05_Komfort" 32 "CAB_06_Anzeige" 64 "CAB_07_Connect" 128 "CAB_08_MIB" 256 "CAB_09_Standheizung" 1024 "CAB_11_VLAN_Fahrerassistenz" 2048 "CAB_12_VLAN_Komfort" 4096 "CAB_13_VLAN_Connect" 8192 "CAB_14_VLAN_Infotainment" 16384 "CAB_15_Laden" 32768 "CAB_16_Licht" ;
VAL_ 2600468542 NM_TSG_HFS_CBV_AWB 0 "Passiver_WakeUp" 1 "Aktiver_WakeUp" ;
VAL_ 2600468542 NM_TSG_HFS_CBV_CRI 0 "NM_ohne_Clusteranforderungen" 1 "NM_mit_Clusteranforderungen" ;
VAL_ 2600468542 NM_TSG_HFS_NM_State 0 "Init" 1 "NM_RM_aus_BSM" 2 "NM_RM_aus_PBSM" 4 "NM_NO_aus_RM" 8 "NM_NO_aus_RS" 16 "reserved" 32 "reserved" ;
VAL_ 2600468542 NM_TSG_HFS_Car_Wakeup 0 "Inaktiv" 1 "Car_Wakeup" ;
VAL_ 2600468542 NM_TSG_HFS_UDS_CC 0 "Inaktiv" 1 "CC_aktiv" ;
VAL_ 2600468542 NM_TSG_HFS_NM_aktiv_KL15 0 "Inaktiv" 1 "KL15_EIN" ;
VAL_ 2600468542 NM_TSG_HFS_NM_aktiv_Diagnose 0 "Init" 1 "Diagnose_aktiv" ;
VAL_ 2600468542 NM_TSG_HFS_NM_aktiv_Tmin 0 "Inaktiv" 1 "Mindestaktivzeit" ;
VAL_ 2600468542 NM_TSG_HFS_CAB_V14 0 "Init" 1 "CAB_01_Antrieb" 2 "CAB_02_Hybrid_Laden" 4 "CAB_03_Fahrwerk" 8 "CAB_04_Fahrerassistenz" 16 "CAB_05_Komfort" 32 "CAB_06_Anzeige" 64 "CAB_07_Connect" 128 "CAB_08_MIB" 256 "CAB_09_Standheizung" 1024 "CAB_11_VLAN_Fahrerassistenz" 2048 "CAB_12_VLAN_Komfort" 4096 "CAB_13_VLAN_Connect" 8192 "CAB_14_VLAN_Infotainment" 16384 "CAB_15_Laden" 32768 "CAB_16_Licht" ;
VAL_ 2600468645 NM_WLC1_CBV_AWB 0 "Passiver_WakeUp" 1 "Aktiver_WakeUp" ;
VAL_ 2600468645 NM_WLC1_CBV_CRI 0 "NM_ohne_Clusteranforderungen" 1 "NM_mit_Clusteranforderungen" ;
VAL_ 2600468645 NM_WLC1_NM_State 0 "Init" 1 "NM_RM_aus_BSM" 2 "NM_RM_aus_PBSM" 4 "NM_NO_aus_RM" 8 "NM_NO_aus_RS" 16 "reserved" 32 "reserved" ;
VAL_ 2600468645 NM_WLC1_Car_Wakeup 0 "Inaktiv" 1 "Car_Wakeup" ;
VAL_ 2600468645 NM_WLC1_UDS_CC 0 "Inaktiv" 1 "CC_aktiv" ;
VAL_ 2600468645 NM_WLC1_NM_aktiv_KL15 0 "Inaktiv" 1 "KL15_EIN" ;
VAL_ 2600468645 NM_WLC1_aktiv_Diagnose 0 "Init" 1 "Diagnose_aktiv" ;
VAL_ 2600468645 NM_WLC1_aktiv_Tmin 0 "Inaktiv" 1 "Mindestaktivzeit" ;
VAL_ 2600468645 NM_WLC1_CAB_V14 0 "Init" 1 "CAB_01_Antrieb" 2 "CAB_02_Hybrid_Laden" 4 "CAB_03_Fahrwerk" 8 "CAB_04_Fahrerassistenz" 16 "CAB_05_Komfort" 32 "CAB_06_Anzeige" 64 "CAB_07_Connect" 128 "CAB_08_MIB" 256 "CAB_09_Standheizung" 1024 "CAB_11_VLAN_Fahrerassistenz" 2048 "CAB_12_VLAN_Komfort" 4096 "CAB_13_VLAN_Connect" 8192 "CAB_14_VLAN_Infotainment" 16384 "CAB_15_Laden" 32768 "CAB_16_Licht" ;
VAL_ 28 OCU_WFS_Anfrage_Typ 0 "Init" ;
VAL_ 28 OCU_WFS_Anfrage_CRC 0 "Init" ;
VAL_ 28 OCU_WFS_Anfrage_Status 0 "Init" ;
VAL_ 2589283656 ORU_Warnung 0 "keine_Anzeige" 1 "Update_unvollstaendig_Prio1" 2 "Update_fehlgeschlagen_Prio1" 3 "reserviert" ;
VAL_ 2589283656 ORU_Status 0 "IDLE" 1 "PENDING" 2 "PREPARATION" 3 "PREPARATION_HV" 4 "RUNNING" 5 "RUNNING_HV" 6 "PENDING_NOTREADY" 7 "FAILURE_POWERTRAIN_DISABLED" ;
VAL_ 2527679741 PAO_ON_Status 0 "LED_aus" 1 "LED_an" 2 "LED_blinkt" 3 "LED_defekt" ;
VAL_ 2527679741 PAO_OFF_Status 0 "LED_aus" 1 "LED_an" 2 "LED_blinkt" 3 "LED_defekt" ;
VAL_ 233 Parken_Hindernis_Bereich 0 "Kein_Hindernis" 1 "Objekt_in_Bereich_1" 2 "Objekt_in_Bereich_2" 3 "Objekt_in_Bereich_3" 4 "Objekt_in_Bereich_4" 5 "Objekt_in_Bereich_5" 6 "Objekt_in_Bereich_6" 7 "Objekt_in_Bereich_7" 8 "Objekt_in_Bereich_8" 9 "Objekt_in_Bereich_9" 10 "Objekt_in_Bereich_10" 11 "Objekt_in_Bereich_11" 12 "Objekt_in_Bereich_12" 13 "Objekt_in_Bereich_13" 14 "Objekt_in_Bereich_14" 15 "Objekt_in_Bereich_15" ;
VAL_ 233 Parken_SM_Sensor 0 "Kamera_verschmutzt" 1 "Kamera_liefert_Bilddaten" ;
VAL_ 233 Parken_SM_Stillstand 0 "Kein_Stillstand" 1 "Stillstand" ;
VAL_ 233 Parken_SM_Schluessel 0 "Kein_Schluessel_vorhanden" 1 "Schluessel_vorhanden" ;
VAL_ 233 Parken_SM_Tueren 0 "Tuer_geoeffnet" 1 "Tueren_geschlossen" ;
VAL_ 233 Parken_SM_Anhaenger 0 "Kein_Anhaenger" 1 "Anhaenger_erkannt" ;
VAL_ 233 Parken_SM_Fahrbereitschaft 0 "Keine_Fahrbereitschaft" 1 "Fahrbereitschaft" ;
VAL_ 233 Parken_SM_Fahrstufe 0 "Falsche_Fahrstufe" 1 "Korrekte_Fahrstufe" ;
VAL_ 233 Parken_Anhaltegrund_ext 0 "Kein_Grund_aktiv" 1 "Stoerung" 2 "Funktion_nicht_verfuegbar" 3 "Tueren_Klappen" 4 "Verkehr_erkannt" 5 "Interaktion_erkannt" 6 "Eingriff_Fahrzeugsystem" 7 "Zeitlimit" 8 "Keine_Weiterfahrt_moeglich" 9 "Ladestecker_gesteckt" 10 "Empfang_gestoert" 11 "Ladezustand_gering" 12 "Land_nicht_zulaessig" 13 "Schluessel_Taste_betaetigt" 14 "Strecke_nicht_angelernt" 15 "Garagentor_oeffnen" 16 "Schluessel_im_Innenraum" 17 "Mehrere_Schluessel_gefunden" 18 "Offroad_aktiv" 19 "Luftfahrwerkhoehe_nio" 20 "Maximale_strecke_erreicht" 21 "Rangier_Flaeche_zu_klein" 22 "Abbruch_durch_GwSm" 23 "Maximale_Zuege_erreicht" 24 "Luecke_zu_klein" 25 "Schluessel_ausser_Reichweite" 26 "Hindernis_erkannt" 27 "Anhaenger_erkannt" 28 "Abbruch_ESC_Eingriff" 29 "PP_Fehler_Schluesselautorisier" 30 "Verlust_PP_PosOK" 31 "Abbruch_TSK_Steigung" 32 "Stby_Erhoehter_Fahrwiderstand" 33 "Abbruch_Erhoehter_Fahrwiderstand" 34 "KAB_VoKo_VKM_aus" 35 "KAB_VoKo_VKM_an" ;
VAL_ 233 Parken_Touchdiagnose_Anf 0 "Keine_Anf" 1 "Anf_Touchdiagnose" ;
VAL_ 233 Parken_BT_Wunsch 0 "kein_BT_erforderlich" 1 "BT_erwuenscht" ;
VAL_ 233 Parken_Hindernis_erkannt 0 "None" 1 "Obstacle_detected" ;
VAL_ 233 Parken_Fortschrittszaehler 127 "Init" ;
VAL_ 233 Parken_SM_AktivesRemoteSystem 0 "kein_System_aktiv" 1 "RPA_aktiv" 2 "AAA_aktiv" 3 "TPA_aktiv" ;
VAL_ 233 Parken_Fahrtaster_Empfehlung 0 "No_Recommendation" 1 "Drive_1" 2 "Drive_2" ;
VAL_ 233 Parken_Aktives_Bedienelement 0 "None" 1 "Mobile_Device" 2 "Drive_Button" 3 "Key" ;
VAL_ 233 Parken_FFB_Status 0 "Init" 1 "Key_in_range" 2 "Key_leaving_range" 3 "Key_out_of_range" 4 "Key_invalid" ;
VAL_ 233 Parken_Reversieren_moeglich 0 "Reversing_not_possible" 1 "Reversing_possible" ;
VAL_ 233 Parken_Seite 0 "Init" 1 "Left" 2 "Right" 3 "Left_or_Right" 4 "Straight" 5 "Left_or_Straight" 6 "Right_or_Straight" 7 "Left_or_Right_or_Straight" ;
VAL_ 233 Parken_Seite_Aktiv 0 "Init" 1 "left" 2 "right" 3 "straight" ;
VAL_ 233 Parken_Szenario_Aktiv 0 "Init" 1 "Parallel" 2 "Perpendicular" 3 "Garage" 4 "Basic" 5 "Custom_Drive" 6 "TPA" 7 "AAA" ;
VAL_ 233 Parken_Manoever_Aktiv 0 "Init" 1 "Einparken" 2 "Ausparken" ;
VAL_ 233 Parken_Manoever 0 "Init" 1 "Einparken" 2 "Ausparken" 3 "Einparken_Ausparken" ;
VAL_ 233 Parken_Szenario 0 "Init" 1 "Parallel" 2 "Perpendicular" 3 "Parallel_or_Perpendicular" 4 "Garage" 5 "Garage_or_Parallel" 6 "Garage_or_Perpendicular" 7 "Garage_or_Parallel_or_Perpendicular" 8 "Basic" 9 "Basic_or_Parallel" 10 "Basic_or_Perpendicular" 11 "Basic_or_Parallel_or_Perpendicular" 12 "Basic_or_Garage" 13 "Basic_or_Garage_or_Parallel" 14 "Basic_or_Garage_or_Perpendicular" 15 "Basic_or_Garage_or_Parallel_or_Perpendicular" ;
VAL_ 233 Parken_Funktionsstatus 0 "Undefined" 1 "Starting_Up" 2 "Engine_Ready_to_Start" 3 "Ready_to_Start" 4 "In_Progress" 5 "Paused" 6 "Finished" 7 "Aborted_resuming_possible" 8 "Aborted_resuming_not_possible" 9 "Custom_Drive" 10 "Engine_Start_requested" ;
VAL_ 233 Parken_Richtung 0 "Init" 1 "Forward" 2 "Backward" 3 "Forward_or_Backward" ;
VAL_ 233 Parken_Richtung_Aktiv 0 "Init" 1 "Forward" 2 "Backward" ;
VAL_ 2463978635 Parken_Traj_Trans_ID 0 "Transaktions_ID_0" 1 "Transaktions_ID_1" 2 "Transaktions_ID_2" 3 "Transaktions_ID_3" 4 "Transaktions_ID_4" 5 "Transaktions_ID_5" 6 "Transaktions_ID_6" 7 "Transaktions_ID_7" 8 "Transaktions_ID_8" 9 "Transaktions_ID_9" 10 "Transaktions_ID_10" 11 "Transaktions_ID_11" 12 "Transaktions_ID_12" 13 "Transaktions_ID_13" 14 "Transaktions_ID_14" 15 "Transaktions_ID_15" ;
VAL_ 2463978635 Parken_Hindernis_erkannt_02 0 "kein_Hindernis_erkannt" 1 "Hindernis_in_Parkrichtung" 2 "Hindernis_entgegen_Parkrichtung" 3 "Hindernis_vor_und_hinter" ;
VAL_ 2463978635 Parken_Szenario_02 0 "Init" 1 "Parallel" 2 "Perpendicular" 3 "Parallel_or_Perpendicular" 4 "Garage" 5 "Garage_or_Parallel" 6 "Garage_or_Perpendicular" 7 "Garage_or_Parallel_or_Perpendicular" 8 "Basic" 9 "Basic_or_Parallel" 10 "Basic_or_Perpendicular" 11 "Basic_or_Parallel_or_Perpendicular" 12 "Basic_or_Garage" 13 "Basic_or_Garage_or_Parallel" 14 "Basic_or_Garage_or_Perpendicular" 15 "Basic_or_Garage_or_Parallel_or_Perpendicular" 16 "TPA" 17 "TPA_or_Parallel" 18 "TPA_or_Perpendicular" 19 "TPA_or_Parallel_or_Perpendicular" 20 "TPA_or_Garage" 21 "TPA_or_Garage_or_Parallel" 22 "TPA_or_Garage_or_Perpendicular" 23 "TPA_or_Garage_or_Parallel_or_Per" 24 "TPA_or_Basic" 25 "TPA_or_Basic_or_Parallel" 26 "TPA_or_Basic_or_Perpendicular" 27 "TPA_or_Basic_or_Parallel_or_Per" 28 "TPA_or_Basic_or_Garage" 29 "TPA_or_Basic_or_Garage_or_Par" 30 "TPA_or_Basic_or_Garage_or_Per" 31 "TPA_or_Bas_or_Gar_or_Par_or_Per" ;
VAL_ 2463978635 Parken_Traj_aktueller_Zug 0 "init" 1 "Zug_1" 2 "Zug_2" 3 "Zug_3" 4 "Zug_4" 5 "Zug_5" 6 "Zug_6" 7 "Zug_7" 8 "Zug_8" 9 "Zug_9" 10 "Zug_10" 11 "Zug_11" 12 "Zug_12" 13 "Zug_13" 14 "Zug_14" 15 "Zug_15" ;
VAL_ 2463978635 Parken_Traj_Anzahl_Punkte 0 "init" 1 "Punkte_Anz_1" 2 "Punkte_Anz_2" 3 "Punkte_Anz_3" 4 "Punkte_Anz_4" 5 "Punkte_Anz_5" 6 "Punkte_Anz_6" 7 "Punkte_Anz_7" 8 "Punkte_Anz_8" 9 "Punkte_Anz_9" ;
VAL_ 2463978635 Parken_Traj_letzter_Zug 0 "Wendepunkt" 1 "Zielpunkt" ;
VAL_ 2463978635 Parken_Traj_Fahrtrichtung 0 "Fahrtrichtung_Vorwaerts" 1 "Fahrtrichtung_Rueckwaerts" ;
VAL_ 850 Parken_SM_03_MUX 0 "MUX_Gruppe_Punktinfo_0" 1 "MUX_Gruppe_Punktinfo_1" 2 "MUX_Gruppe_Punktinfo_2" 3 "MUX_Gruppe_Punktinfo_3" 4 "MUX_Gruppe_Punktinfo_4" 5 "MUX_Gruppe_Punktinfo_5" 6 "MUX_Gruppe_Punktinfo_6" ;
VAL_ 850 Parken_SM_03_Traj_Trans_ID_00 0 "Transaktions_ID_0" 1 "Transaktions_ID_1" 2 "Transaktions_ID_2" 3 "Transaktions_ID_3" 4 "Transaktions_ID_4" 5 "Transaktions_ID_5" 6 "Transaktions_ID_6" 7 "Transaktions_ID_7" 8 "Transaktions_ID_8" 9 "Transaktions_ID_9" 10 "Transaktions_ID_10" 11 "Transaktions_ID_11" 12 "Transaktions_ID_12" 13 "Transaktions_ID_13" 14 "Transaktions_ID_14" 15 "Transaktions_ID_15" ;
VAL_ 850 Parken_SM_03_Traj_Trans_ID_01 0 "Transaktions_ID_0" 1 "Transaktions_ID_1" 2 "Transaktions_ID_2" 3 "Transaktions_ID_3" 4 "Transaktions_ID_4" 5 "Transaktions_ID_5" 6 "Transaktions_ID_6" 7 "Transaktions_ID_7" 8 "Transaktions_ID_8" 9 "Transaktions_ID_9" 10 "Transaktions_ID_10" 11 "Transaktions_ID_11" 12 "Transaktions_ID_12" 13 "Transaktions_ID_13" 14 "Transaktions_ID_14" 15 "Transaktions_ID_15" ;
VAL_ 850 Parken_SM_03_Traj_Trans_ID_02 0 "Transaktions_ID_0" 1 "Transaktions_ID_1" 2 "Transaktions_ID_2" 3 "Transaktions_ID_3" 4 "Transaktions_ID_4" 5 "Transaktions_ID_5" 6 "Transaktions_ID_6" 7 "Transaktions_ID_7" 8 "Transaktions_ID_8" 9 "Transaktions_ID_9" 10 "Transaktions_ID_10" 11 "Transaktions_ID_11" 12 "Transaktions_ID_12" 13 "Transaktions_ID_13" 14 "Transaktions_ID_14" 15 "Transaktions_ID_15" ;
VAL_ 850 Parken_SM_03_Traj_Trans_ID_03 0 "Transaktions_ID_0" 1 "Transaktions_ID_1" 2 "Transaktions_ID_2" 3 "Transaktions_ID_3" 4 "Transaktions_ID_4" 5 "Transaktions_ID_5" 6 "Transaktions_ID_6" 7 "Transaktions_ID_7" 8 "Transaktions_ID_8" 9 "Transaktions_ID_9" 10 "Transaktions_ID_10" 11 "Transaktions_ID_11" 12 "Transaktions_ID_12" 13 "Transaktions_ID_13" 14 "Transaktions_ID_14" 15 "Transaktions_ID_15" ;
VAL_ 850 Parken_SM_03_Traj_Trans_ID_04 0 "Transaktions_ID_0" 1 "Transaktions_ID_1" 2 "Transaktions_ID_2" 3 "Transaktions_ID_3" 4 "Transaktions_ID_4" 5 "Transaktions_ID_5" 6 "Transaktions_ID_6" 7 "Transaktions_ID_7" 8 "Transaktions_ID_8" 9 "Transaktions_ID_9" 10 "Transaktions_ID_10" 11 "Transaktions_ID_11" 12 "Transaktions_ID_12" 13 "Transaktions_ID_13" 14 "Transaktions_ID_14" 15 "Transaktions_ID_15" ;
VAL_ 850 Parken_SM_03_Traj_Trans_ID_05 0 "Transaktions_ID_0" 1 "Transaktions_ID_1" 2 "Transaktions_ID_2" 3 "Transaktions_ID_3" 4 "Transaktions_ID_4" 5 "Transaktions_ID_5" 6 "Transaktions_ID_6" 7 "Transaktions_ID_7" 8 "Transaktions_ID_8" 9 "Transaktions_ID_9" 10 "Transaktions_ID_10" 11 "Transaktions_ID_11" 12 "Transaktions_ID_12" 13 "Transaktions_ID_13" 14 "Transaktions_ID_14" 15 "Transaktions_ID_15" ;
VAL_ 850 Parken_SM_03_Traj_Trans_ID_06 0 "Transaktions_ID_0" 1 "Transaktions_ID_1" 2 "Transaktions_ID_2" 3 "Transaktions_ID_3" 4 "Transaktions_ID_4" 5 "Transaktions_ID_5" 6 "Transaktions_ID_6" 7 "Transaktions_ID_7" 8 "Transaktions_ID_8" 9 "Transaktions_ID_9" 10 "Transaktions_ID_10" 11 "Transaktions_ID_11" 12 "Transaktions_ID_12" 13 "Transaktions_ID_13" 14 "Transaktions_ID_14" 15 "Transaktions_ID_15" ;
VAL_ 2527679498 Perso_Kontonummer 0 "kein_Benutzerkonto" 1 "Benutzerkonto_1" 2 "Benutzerkonto_2" 3 "Benutzerkonto_3" 4 "Benutzerkonto_4" 5 "Benutzerkonto_5" 6 "Benutzerkonto_6" 7 "Benutzerkonto_7" ;
VAL_ 2527679498 Perso_Steuerung 0 "keine_Steuerung" 1 "Reset_alle_Konten" 2 "Reset_aktives_Konto" 3 "Kopiere_aktives_Konto_nach" 4 "Wiederherstellen_aktives_Konto" 5 "Aktivieren_aktives_Konto" 6 "Reset_Konto" 7 "Reset_alle_Fahrer" 8 "Reset_aktiver_Fahrer" 9 "Reset_Fahrer" ;
VAL_ 2527679498 Perso_Steuerungsparameter 0 "kein_Parameter" 1 "Benutzerkonto_1" 2 "Benutzerkonto_2" 3 "Benutzerkonto_3" 4 "Benutzerkonto_4" 5 "Benutzerkonto_5" 6 "Benutzerkonto_6" 7 "Benutzerkonto_7" ;
VAL_ 2527679498 Perso_Status 0 "deaktiviert" 1 "PSO_1x_aktiviert" 2 "PSO_2x_aktiviert" ;
VAL_ 2527679498 Perso_Bedienstelle 0 "Init" 1 "Kombiinstrument" 2 "ABT" ;
VAL_ 2527679498 Perso_Freigabe_Verstellung 0 "Init" 1 "freigegeben" ;
VAL_ 2527679498 Perso_Aktiv 0 "deaktiviert" 1 "aktiviert" ;
VAL_ 2527679498 IAA_PSO_wake_up 0 "wake_up_inactive" 1 "wake_up_active" ;
VAL_ 2527679498 Perso_Fahrernummer 0 "kein_Fahrer" 1 "Fahrer_1" 2 "Fahrer_2" 3 "Fahrer_3" 4 "Fahrer_4" 5 "Fahrer_5" 6 "Fahrer_6" 7 "Fahrer_7" ;
VAL_ 2527679498 Perso_Schreibschutz 0 "Schreibschutz_deaktiviert" 1 "Schreibschutz_aktiviert" ;
VAL_ 2463978629 Perso_Kontonummer_02 0 "kein_Benutzerkonto" 1 "Benutzerkonto_1" 2 "Benutzerkonto_2" 3 "Benutzerkonto_3" 4 "Benutzerkonto_4" 5 "Benutzerkonto_5" 6 "Benutzerkonto_6" 7 "Benutzerkonto_7" ;
VAL_ 2463978629 Perso_Steuerung_02 0 "keine_Steuerung" 1 "Reset_alle_Konten" 2 "Reset_aktives_Konto" 3 "Kopiere_aktives_Konto_nach" 4 "Wiederherstellen_aktives_Konto" 5 "Aktivieren_aktives_Konto" 6 "Reset_Konto" 7 "Reset_alle_Fahrer" 8 "Reset_aktiver_Fahrer" 9 "Reset_Fahrer" ;
VAL_ 2463978629 Perso_Steuerungsparameter_02 0 "kein_Parameter" 1 "Benutzerkonto_1" 2 "Benutzerkonto_2" 3 "Benutzerkonto_3" 4 "Benutzerkonto_4" 5 "Benutzerkonto_5" 6 "Benutzerkonto_6" 7 "Benutzerkonto_7" ;
VAL_ 2463978629 Perso_Status_02 0 "InitWert_deaktiviert" 1 "PSO_1x_aktiviert" 2 "PSO_2x_aktiviert" ;
VAL_ 2463978629 Perso_Bedienstelle_02 0 "Init" 1 "Kombiinstrument" 2 "ABT" ;
VAL_ 2463978629 Perso_Freigabe_Verstellung_02 0 "Init" 1 "freigegeben" ;
VAL_ 2463978629 Perso_Aktiv_02 0 "deaktiviert" 1 "aktiviert" ;
VAL_ 2463978629 Perso_Fahrernummer_02 0 "kein_Fahrer" 1 "Fahrer_1" 2 "Fahrer_2" 3 "Fahrer_3" 4 "Fahrer_4" 5 "Fahrer_5" 6 "Fahrer_6" 7 "Fahrer_7" ;
VAL_ 2463978629 Perso_Schreibschutz_02 0 "Schreibschutz_deaktiviert" 1 "Schreibschutz_aktiviert" ;
